VERSION ""

NS_ :

BS_:

BU_: PBWM MCPB MCPA IDCM EVCU2 ECM DMPI BPCM

BO_ 2564554485 DIAGNOSTIC_REQUEST_FUNC_FOTA: 64 EVCU2
 SG_ N_PDU : 7|64@0+ (1,0) [0|0] "" MCPB,MCPA

BO_ 292 BATTERY_HV_STATUS1: 64 BPCM
 SG_ MessageCounter_BATT_HV_STATUS1 : 435|4@0+ (1,0) [0|15] "-"  DMPI,EVCU2,MCPB,MCPA,IDCM
 SG_ CRC_BATT_HV_STATUS1 : 447|8@0+ (1,0) [0|255] "-"  DMPI,EVCU2,MCPB,MCPA,IDCM
 SG_ HVBatContactorWeldCheck : 302|1@0+ (1,0) [0|1] "" EVCU2
 SG_ HVBatReady : 268|1@0+ (1,0) [0|1] "" EVCU2
 SG_ BPCM_DC_CntctrsMidTrmOpeningWarn : 267|1@0+ (1,0) [0|1] "" EVCU2
 SG_ BPCM_DC_CntctrsShtTrmOpeningWarn : 266|1@0+ (1,0) [0|1] "" EVCU2
 SG_ BPCM_ImpactHardwireV : 188|1@0+ (1,0) [0|1] "" EVCU2
 SG_ BPCM_ImpactHardwire : 187|1@0+ (1,0) [0|1] "" EVCU2
 SG_ BPCM_HV_Char_Main_Contac_Sts : 178|3@0+ (1,0) [0|7] "" EVCU2
 SG_ BPCM_HV_Trac_Main_Contac_Sts : 181|3@0+ (1,0) [0|7] "" DMPI,EVCU2,MCPB,MCPA,IDCM
 SG_ BPCM_HV_BalancingMode : 164|2@0+ (1,0) [0|3] "" EVCU2
 SG_ BPCM_HV_ChargingBusVoltage : 162|11@0+ (1,0) [0|2047] "V"  EVCU2
 SG_ BPCM_HV_TractionBusVoltage : 146|11@0+ (1,0) [0|2047] "V"  DMPI,EVCU2,MCPB,MCPA,IDCM
 SG_ BPCM_Pwr_Limp_Home_On : 55|1@0+ (1,0) [0|1] "" EVCU2
 SG_ BPCM_HV_Trac_Bus_Sts : 36|3@0+ (1,0) [0|7] "" EVCU2,MCPB,MCPA,IDCM
 SG_ BPCM_HV_Char_Bus_Sts : 39|3@0+ (1,0) [0|7] "" EVCU2
 SG_ BPCM_HV_SOH_Low : 30|7@0+ (1,0) [0|127] "" EVCU2
 SG_ BPCM_HV_SOH : 22|7@0+ (1,0) [0|127] "" EVCU2
 SG_ HVBatContactorOpenTime : 15|8@0+ (0.2,0) [0|51] "Hours"  EVCU2
 SG_ HVBatLastSlept : 7|8@0+ (0.2,0) [0|51] "Days"  EVCU2
 SG_ BPCMInterlockSts : 54|3@0+ (1,0) [0|4] "" EVCU2
 SG_ BPCM_HV_BatIntrlk_InternalStat : 271|3@0+ (1,0) [0|3] "" EVCU2
 SG_ BPCM_HV_Temperature_Min : 218|11@0+ (0.1,-40) [-40|164.7] "°C"  EVCU2
 SG_ BPCM_HV_Temperature_Max : 202|11@0+ (0.1,-40) [-40|164.7] "°C"  EVCU2
 SG_ BPCM_HV_Temperature_Avg : 186|11@0+ (0.1,-40) [-40|164.7] "°C"  EVCU2
 SG_ BPCM_HV_SOC : 33|10@0+ (0.1,0) [0|102.3] "%"  DMPI,EVCU2
 SG_ BPCM_HV_Outlet_Temp : 250|11@0+ (0.1,-40) [-40|164.7] "°C"  EVCU2
 SG_ BPCM_HV_InternalVoltage : 133|14@0+ (0.1,90.9) [90.9|1729.2] "V"  DMPI,EVCU2
 SG_ BPCM_HV_Inlet_Temp : 234|11@0+ (0.1,-40) [-40|164.7] "°C"  EVCU2
 SG_ BPCM_HV_Current : 71|16@0+ (0.1,-3276.7) [-3276.7|3276.8] "A"  DMPI,EVCU2
 SG_ BPCM_HV_Capacity : 51|12@0+ (0.15,0) [0|614.25] "Ah"  EVCU2
 SG_ BPCM_HV_Battery_GFD_Sts : 149|3@0+ (1,0) [0|4] "" EVCU2
 SG_ BPCM_Wakeup_Request : 23|1@0+ (1,0) [0|1] "" EVCU2
 SG_ BPCM_HV_ThermalRunaway : 135|2@0+ (1,0) [0|3] "" EVCU2
 SG_ BPCM_MILRequest : 31|1@0+ (1,0) [0|1] "" EVCU2
 SG_ HVBP_Busbar_Temp : 423|8@0+ (1,-40) [-40|215] "°C"  EVCU2
 SG_ HVBP_BDU_Busbar_Temp : 415|8@0+ (1,-40) [-40|215] "°C"  EVCU2
 SG_ BPCM_HV_DCFC_Isolation_Sts : 167|3@0+ (1,0) [0|7] "" EVCU2
 SG_ BPCM_HV_Trac_PreCha_Contac_Sts : 354|3@0+ (1,0) [0|7] "" EVCU2

BO_ 485 BATTERY_HV_VLIMITS: 64 BPCM
 SG_ MessageCounter_BATT_HV_VLIMITS : 435|4@0+ (1,0) [0|15] "-"  EVCU2
 SG_ CRC_BATT_HV_VLIMITS : 447|8@0+ (1,0) [0|255] "-"  EVCU2
 SG_ BPCM_HV_NumCellMinTemp : 224|9@0+ (1,0) [0|511] "" EVCU2
 SG_ BPCM_HV_NumCellMaxTemp : 192|9@0+ (1,0) [0|511] "" EVCU2
 SG_ BPCM_HV_NumCellMinVolt : 80|9@0+ (1,0) [0|511] "" EVCU2
 SG_ BPCM_HV_NumCellMaxVolt : 64|9@0+ (1,0) [0|511] "" EVCU2
 SG_ BPCM_Min_Pk_Volt_Allowed : 50|11@0+ (1,0) [0|2047] "V"  EVCU2
 SG_ BPCM_Max_Pk_Volt_Allowed : 18|11@0+ (1,0) [0|2047] "V"  EVCU2
 SG_ BPCM_OCV_Min_Cell_Volt : 180|13@0+ (0.001,0) [0|8.191] "V"  EVCU2
 SG_ BPCM_OCV_Max_Cell_Volt : 164|13@0+ (0.001,0) [0|8.191] "V"  EVCU2
 SG_ BPCM_OCV_Avg_Cell_Volt : 148|13@0+ (0.001,0) [0|8.191] "V"  EVCU2
 SG_ BPCM_Min_Cell_Volt_Allowed : 36|13@0+ (0.001,0) [0|8.191] "V"  EVCU2
 SG_ BPCM_Max_Cell_Volt_Allowed : 132|13@0+ (0.001,0) [0|8.191] "V"  EVCU2
 SG_ BPCM_HV_Insulation_Resistance : 215|16@0+ (1,0) [0|65535] "kOhm"  EVCU2
 SG_ BPCM_Cell_Volt_Min : 116|13@0+ (0.001,0) [0|8.191] "V"  EVCU2
 SG_ BPCM_Cell_Volt_Max : 100|13@0+ (0.001,0) [0|8.191] "V"  EVCU2
 SG_ BPCM_Cell_Volt_Avg : 4|13@0+ (0.001,0) [0|8.191] "V"  EVCU2

BO_ 288 BATTERY_HV_POWERLIMITS: 64 BPCM
 SG_ BPCM_HV_HVBatChargeStat : 215|3@0+ (1,0) [0|7] "" EVCU2
 SG_ BPCM_HV_PwrLmtInstDschg : 245|14@0+ (0.1,0) [0|1638.3] "" EVCU2
 SG_ BPCM_HV_PwrLmtInstChrg : 309|14@0+ (0.1,0) [0|1638.3] "" EVCU2
 SG_ BPCM_HV_Pwr_MaxDischrg_ShrTrm : 69|14@0+ (0.1,0) [0|1638.3] "kW"  DMPI,EVCU2
 SG_ BPCM_HV_Power_MaxDischarge_MdTrm : 133|14@0+ (0.1,0) [0|1638.3] "kW"  EVCU2
 SG_ BPCM_HV_Power_MaxDischarge_LgTrm : 197|14@0+ (0.1,0) [0|1638.3] "kW"  EVCU2
 SG_ BPCM_HV_Power_MaxCharge_ShrTrm : 53|14@0+ (0.1,0) [0|1638.3] "kW"  EVCU2
 SG_ BPCM_HV_Power_MaxCharge_MdTrm : 117|14@0+ (0.1,0) [0|1638.3] "kW"  EVCU2
 SG_ BPCM_HV_Power_MaxCharge_LgTrm : 181|14@0+ (0.1,0) [0|1638.3] "kW"  EVCU2
 SG_ BPCM_HV_CrntLmtInstDschg : 374|15@0+ (0.1,0) [0|3276.7] "A"  EVCU2
 SG_ BPCM_HV_CrntLmtInstChrg : 390|15@0+ (0.1,0) [0|3276.7] "A"  EVCU2
 SG_ BPCM_HV_ChargingCurrentProfile : 6|15@0+ (0.1,0) [0|3276.7] "A"  EVCU2
 SG_ BPCM_HV_Cell_MinDischrg_Imped : 228|13@0+ (0.01,0) [0|81.91] "Ohm"  EVCU2
 SG_ BPCM_HV_Cell_MaxDischrg_Imped : 212|13@0+ (0.01,0) [0|81.91] "Ohm"  EVCU2
 SG_ BPCM_CntctrsShtTrmOpeningWarn : 417|1@0+ (1,0) [0|1] "" DMPI,EVCU2,IDCM
 SG_ BPCM_CntctrsMidTrmOpeningWarn : 416|1@0+ (1,0) [0|1] "" EVCU2
 SG_ MessageCounter_BATT_HV_POWERLIMS : 435|4@0+ (1,0) [0|15] "-"  EVCU2
 SG_ CRC_BATT_HV_POWERLIMS : 447|8@0+ (1,0) [0|255] "-"  EVCU2

BO_ 2654339161 PDC_INFO_FD_MCPB: 32 MCPB
 SG_ WakeupSource_FD16_MCPB : 95|8@0+ (1,0) [0|255] "" EVCU2
 SG_ WakeupSource_FD05_MCPB : 23|8@0+ (1,0) [0|255] "" EVCU2
 SG_ StayActiveSource_FD16_MCPB : 111|64@0+ (1,0) [0|0] "" EVCU2
 SG_ StayActiveSource_FD05_MCPB : 31|64@0+ (1,0) [0|0] "" EVCU2
 SG_ PreviousCanNMState_FD16_MCPB : 103|4@0+ (1,0) [0|15] "" EVCU2
 SG_ PreviousCanNMState_FD05_MCPB : 11|4@0+ (1,0) [0|15] "" EVCU2
 SG_ GenericFailSts_FD05_MCPB : 5|1@0+ (1,0) [0|1] "" EVCU2
 SG_ EOL_FD16_MCPB : 2|1@0+ (1,0) [0|1] "-"  EVCU2
 SG_ EOL_FD05_MCPB : 7|1@0+ (1,0) [0|1] "-"  EVCU2
 SG_ DES_FD05_MCPB : 4|2@0+ (1,0) [0|3] "" EVCU2
 SG_ CurrentFailSts_FD05_MCPB : 6|1@0+ (1,0) [0|1] "" EVCU2
 SG_ CurrentCanNMState_FD16_MCPB : 99|4@0+ (1,0) [0|15] "" EVCU2
 SG_ CurrentCanNMState_FD05_MCPB : 15|4@0+ (1,0) [0|15] "" EVCU2
 SG_ GenericFailSts_FD16_MCPB : 172|1@0+ (1,0) [0|1] "" EVCU2
 SG_ DES_FD16_MCPB : 175|2@0+ (1,0) [0|3] "" EVCU2
 SG_ CurrentFailSts_FD16_MCPB : 173|1@0+ (1,0) [0|1] "" EVCU2

BO_ 2654339160 PDC_INFO_FD_MCPA: 32 MCPA
 SG_ WakeupSource_FD16_MCPA : 95|8@0+ (1,0) [0|255] "" EVCU2
 SG_ WakeupSource_FD05_MCPA : 23|8@0+ (1,0) [0|255] "" EVCU2
 SG_ StayActiveSource_FD16_MCPA : 111|64@0+ (1,0) [0|0] "" EVCU2
 SG_ StayActiveSource_FD05_MCPA : 31|64@0+ (1,0) [0|0] "" EVCU2
 SG_ PreviousCanNMState_FD16_MCPA : 103|4@0+ (1,0) [0|15] "" EVCU2
 SG_ PreviousCanNMState_FD05_MCPA : 11|4@0+ (1,0) [0|15] "" EVCU2
 SG_ GenericFailSts_FD05_MCPA : 5|1@0+ (1,0) [0|1] "" EVCU2
 SG_ EOL_FD16_MCPA : 2|1@0+ (1,0) [0|1] "-"  EVCU2
 SG_ EOL_FD05_MCPA : 7|1@0+ (1,0) [0|1] "-"  EVCU2
 SG_ DES_FD05_MCPA : 4|2@0+ (1,0) [0|3] "" EVCU2
 SG_ CurrentFailSts_FD05_MCPA : 6|1@0+ (1,0) [0|1] "" EVCU2
 SG_ CurrentCanNMState_FD16_MCPA : 99|4@0+ (1,0) [0|15] "" EVCU2
 SG_ CurrentCanNMState_FD05_MCPA : 15|4@0+ (1,0) [0|15] "" EVCU2
 SG_ GenericFailSts_FD16_MCPA : 172|1@0+ (1,0) [0|1] "" EVCU2
 SG_ DES_FD16_MCPA : 175|2@0+ (1,0) [0|3] "" EVCU2
 SG_ CurrentFailSts_FD16_MCPA : 173|1@0+ (1,0) [0|1] "" EVCU2

BO_ 263 PT_SYSTEM_FD_1: 64 EVCU2
 SG_ OptimdStrtReqdActr : 2|3@0+ (1,0) [0|7] "" ECM
 SG_ OptimdEngStrtStpType : 7|5@0+ (1,0) [0|31] "" ECM
 SG_ OptimdEngOnOffCmd : 15|1@0+ (1,0) [0|1] "" ECM
 SG_ Hyb_ProducingTorque : 13|1@0+ (1,0) [0|1] "" ECM
 SG_ HCPFuelDisable : 14|1@0+ (1,0) [0|1] "" ECM
 SG_ PowertrainPrplsnActv_PT : 146|1@0+ (1,0) [0|1] "" MCPB,MCPA,BPCM
 SG_ GearEngagedForDisplay_PT : 12|5@0+ (1,0) [0|31] "" PBWM,MCPB,MCPA,BPCM
 SG_ GearEngaged_PT : 132|4@0+ (1,0) [0|15] "" MCPB
 SG_ DriveReady_PT : 166|1@0+ (1,0) [0|1] "" BPCM
 SG_ ParkCmd_PT : 151|2@0+ (1,0) [0|3] "" PBWM
 SG_ ShiftLeverPosition_PT : 51|4@0+ (1,0) [0|15] "" DMPI
 SG_ MessageCounter_PT_SYSTEM_FD_1 : 435|4@0+ (1,0) [0|15] "-"  PBWM,MCPB
 SG_ CRC_PT_SYSTEM_FD_1 : 447|8@0+ (1,0) [0|255] "-"  PBWM,MCPB
 SG_ EVCU_END_Request_Flag_PT : 320|1@0+ (1,0) [0|1] "" PBWM

BO_ 216 PT_ENERGY_FD_1: 64 EVCU2
 SG_ MC_PT_ENERGY_FD_1 : 435|4@0+ (1,0) [0|15] "-"  DMPI,IDCM,BPCM
 SG_ DCChrgVoltMin_PT : 55|14@0+ (0.1,0) [0|1638.30] "" Vector__XXX
 SG_ DCChrgVoltMax_PT : 151|14@0+ (0.1,0) [0|1638.30] "V"  Vector__XXX
 SG_ DCChrgPwrLim_PT : 119|14@0+ (0.1,-815) [-815|823.30] "kW"  Vector__XXX
 SG_ DCChrgCurrentRq_PT : 95|14@0+ (0.1,-815) [-815|823.30] "A"  Vector__XXX
 SG_ DCChrgCurrentLimit_PT : 21|14@0+ (0.1,-815) [-815|823.30] "A"  Vector__XXX
 SG_ DCChargeInitialized_PT : 56|1@0+ (1,0) [0|1] "" BPCM
 SG_ DCChargeEnRq_PT : 38|1@0+ (1,0) [0|1] "" Vector__XXX
 SG_ CRC_PT_ENERGY_FD_1 : 447|8@0+ (1,0) [0|255] "-"  DMPI,IDCM,BPCM
 SG_ BPCM_OBCM_AC_ContactorCmd_PT : 140|3@0+ (1,0) [0|7] "" IDCM,BPCM
 SG_ BMS_HV_TracCntctr_Cmd_PT : 4|3@0+ (1,0) [0|7] "" MCPB,MCPA,IDCM,BPCM
 SG_ BMS_HV_RefTracHVBus_V_Vldty_PT : 23|1@0+ (1,0) [0|1] "" BPCM
 SG_ BMS_HV_RefTracHVBus_V_PT : 1|10@0+ (1,0) [0|1023] "" BPCM
 SG_ BMS_HV_GFD_Inhibition_PT : 39|1@0+ (1,0) [0|1] "" BPCM
 SG_ BMS_HV_DC_Chrgng_Cntct_K_Cmd_PT : 82|3@0+ (1,0) [0|7] "" MCPB,MCPA,IDCM,BPCM
 SG_ BatteryVoltage_Raw_PT : 97|10@0+ (0.2,0) [0|204.60] "V"  MCPB,MCPA,IDCM,BPCM
 SG_ APM_LV_VsetPoint_PT : 135|11@0+ (0.01,0) [0|20.47] "V"  DMPI,IDCM
 SG_ APM_LV_VActual_PT : 71|9@0+ (0.04,0) [0|20.44] "V"  IDCM
 SG_ APM_LV_IMax_PT : 167|9@0+ (1,0) [0|511] "A"  IDCM
 SG_ APM_HV_IMax_PT : 87|5@0+ (0.8,0) [0|24.8] "A"  IDCM
 SG_ APM_TypeCtrl_PT : 78|4@0+ (1,0) [0|15] "" DMPI,IDCM,BPCM
 SG_ BMS_HV_Char_Main_Contac_Cmd_PT : 173|3@0+ (1,0) [0|7] "" BPCM

BO_ 1041 EVCU_ISO15118_STATUS1: 64 EVCU2
 SG_ EVMinCurrent : 264|9@0+ (1,0) [0|511] "A"  IDCM
 SG_ EVMaxVoltage : 233|10@0+ (1,0) [0|1023] "V"  IDCM
 SG_ EVMaxCurrent : 248|9@0+ (1,0) [0|511] "A"  IDCM
 SG_ Eamount : 281|18@0+ (1,0) [0|262143] "Wh"  IDCM

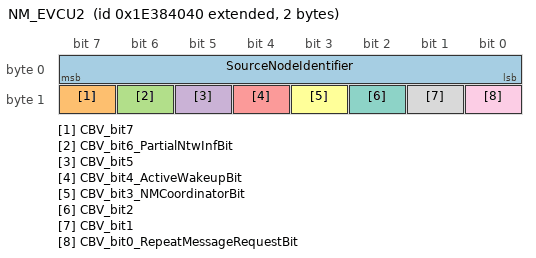
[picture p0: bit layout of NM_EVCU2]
BO_ 2654486592 NM_EVCU2: 2 EVCU2
 SG_ SourceNodeIdentifier : 7|8@0+ (1,0) [0|255] "-"  DMPI,PBWM,MCPB,MCPA,IDCM,BPCM,ECM
 SG_ CBV_bit7 : 15|1@0+ (1,0) [0|1] "" DMPI,PBWM,MCPB,MCPA,IDCM,BPCM,ECM
 SG_ CBV_bit6_PartialNtwInfBit : 14|1@0+ (1,0) [0|1] "" DMPI,PBWM,MCPB,MCPA,IDCM,BPCM,ECM
 SG_ CBV_bit5 : 13|1@0+ (1,0) [0|1] "" DMPI,PBWM,MCPB,MCPA,IDCM,BPCM,ECM
 SG_ CBV_bit4_ActiveWakeupBit : 12|1@0+ (1,0) [0|1] "" DMPI,PBWM,MCPB,MCPA,IDCM,BPCM,ECM
 SG_ CBV_bit3_NMCoordinatorBit : 11|1@0+ (1,0) [0|1] "" DMPI,PBWM,MCPB,MCPA,IDCM,BPCM,ECM
 SG_ CBV_bit2 : 10|1@0+ (1,0) [0|1] "" DMPI,PBWM,MCPB,MCPA,IDCM,BPCM,ECM
 SG_ CBV_bit1 : 9|1@0+ (1,0) [0|1] "" DMPI,PBWM,MCPB,MCPA,IDCM,BPCM,ECM
 SG_ CBV_bit0_RepeatMessageRequestBit : 8|1@0+ (1,0) [0|1] "" DMPI,PBWM,MCPB,MCPA,IDCM,BPCM,ECM

BO_ 212 PIM_B: 64 DMPI
 SG_ PIM_B_Torque_Achieved : 44|13@0+ (0.125,-512) [-512|511.875] "Nm"  EVCU2
 SG_ PIM_B_Torque_Achieved_V : 129|1@0+ (1,0) [0|1] "" EVCU2
 SG_ PIM_B_TorqAchieved_AEMD_V : 196|1@0+ (1,0) [0|1] "" EVCU2
 SG_ PIM_B_TorqAchieved_AEMD : 299|13@0+ (0.125,-512) [-512|511.875] "Nm"  EVCU2
 SG_ PIM_B_SPT_Stat : 78|2@0+ (1,0) [0|3] "" EVCU2
 SG_ PIM_B_Spd_Lim : 356|16@0+ (1,-32767) [-32767|32678] "rpm"  EVCU2
 SG_ PIM_B_RPM_V : 234|1@0+ (1,0) [0|1] "" EVCU2
 SG_ PIM_B_RPM : 28|16@0+ (1,-32768) [-32768|32767] "rpm"  EVCU2
 SG_ PIM_B_MtrMinCpbltyTrq : 321|13@0+ (0.125,-512) [-512|511.875] "Nm"  EVCU2
 SG_ PIM_B_MtrMaxCpbltyTrq : 318|13@0+ (0.125,-512) [-512|511.875] "Nm"  EVCU2
 SG_ PIM_B_MtrIndex : 398|5@0+ (1,0) [0|31] "" EVCU2
 SG_ PIM_B_MinTorq : 280|13@0+ (0.125,-512) [-512|511.875] "Nm"  EVCU2
 SG_ PIM_B_MaxTorq : 277|13@0+ (0.125,-512) [-512|511.875] "Nm"  EVCU2
 SG_ PIM_B_Invrtr_State : 186|4@0+ (1,0) [0|15] "" EVCU2
 SG_ PIM_B_InterlockSts : 229|2@0+ (1,0) [0|3] "-"  EVCU2
 SG_ PIM_B_HV_CnctrOpn_Req : 195|1@0+ (1,0) [0|1] "" EVCU2
 SG_ PIM_B_Dschrge_Status : 393|2@0+ (1,0) [0|3] "" EVCU2
 SG_ PIM_B_DeratingFactor : 388|6@0+ (0.02,0) [0|1.26] "" EVCU2
 SG_ PIM_B_DerateReason : 170|4@0+ (1,0) [0|15] "-"  EVCU2
 SG_ PIM_B_DC_Voltage : 271|10@0+ (1,0) [0|1022] "V"  EVCU2
 SG_ PIM_B_DC_Volt_V : 197|1@0+ (1,0) [0|1] "" EVCU2
 SG_ PIM_B_DC_Current_V : 198|1@0+ (1,0) [0|1] "" EVCU2
 SG_ PIM_B_DC_Current : 63|15@0+ (0.1,-1638.4) [-1638.4|1638.3] "A"  EVCU2,BPCM
 SG_ PIM_B_CpbltySpdDivVolt : 340|16@0+ (1,0) [0|65535] "rpm"  EVCU2
 SG_ PIM_B_CoolantTemp : 407|11@0+ (0.1,-40) [-40|164.7] "°C"  EVCU2
 SG_ PIM_B_AccelRawV : 193|1@0+ (1,0) [0|1] "" EVCU2
 SG_ PIM_B_6SO_Status : 64|2@0+ (1,0) [0|3] "" EVCU2
 SG_ PIM_B_3PS_Pos : 194|1@0+ (1,0) [0|1] "" EVCU2
 SG_ MC_PIM_B : 435|4@0+ (1,0) [0|15] "-"  EVCU2
 SG_ MAC_PIM_B : 471|48@0+ (1,0) [0|0] "" EVCU2
 SG_ CRC_PIM_B : 447|8@0+ (1,0) [0|255] "-"  EVCU2
 SG_ Cntr_PIM_B : 455|16@0+ (1,0) [0|65535] "" EVCU2
 SG_ PIM_B_AccelRaw : 372|16@0+ (1,-32768) [-32768|32767] "rpm/sec"  EVCU2

BO_ 211 PIM_A: 64 DMPI
 SG_ PIM_A_Torque_Achieved : 44|13@0+ (0.125,-512) [-512|511.875] "Nm"  EVCU2,ECM
 SG_ PIM_A_Torque_Achieved_V : 129|1@0+ (1,0) [0|1] "" EVCU2,ECM
 SG_ PIM_A_TorqAchieved_AEMD_V : 196|1@0+ (1,0) [0|1] "" EVCU2
 SG_ PIM_A_TorqAchieved_AEMD : 299|13@0+ (0.125,-512) [-512|511.875] "Nm"  EVCU2
 SG_ PIM_A_SPT_Stat : 78|2@0+ (1,0) [0|3] "" EVCU2
 SG_ PIM_A_Spd_Lim : 356|16@0+ (1,-32767) [-32767|32678] "rpm"  EVCU2
 SG_ PIM_A_RPM_V : 234|1@0+ (1,0) [0|1] "" EVCU2
 SG_ PIM_A_RPM : 28|16@0+ (1,-32768) [-32768|32767] "rpm"  EVCU2
 SG_ PIM_A_MtrMinCpbltyTrq : 321|13@0+ (0.125,-512) [-512|511.875] "Nm"  EVCU2
 SG_ PIM_A_MtrMaxCpbltyTrq : 318|13@0+ (0.125,-512) [-512|511.875] "Nm"  EVCU2
 SG_ PIM_A_MtrIndex : 398|5@0+ (1,0) [0|31] "" EVCU2
 SG_ PIM_A_MinTorq : 280|13@0+ (0.125,-512) [-512|511.875] "Nm"  EVCU2
 SG_ PIM_A_MaxTorq : 277|13@0+ (0.125,-512) [-512|511.875] "Nm"  EVCU2
 SG_ PIM_A_Invrtr_State : 186|4@0+ (1,0) [0|15] "" EVCU2
 SG_ PIM_A_InterlockSts : 229|2@0+ (1,0) [0|3] "-"  EVCU2
 SG_ PIM_A_HV_CnctrOpn_Req : 195|1@0+ (1,0) [0|1] "" EVCU2
 SG_ PIM_A_Dschrge_Status : 393|2@0+ (1,0) [0|3] "" EVCU2
 SG_ PIM_A_DeratingFactor : 388|6@0+ (0.02,0) [0|1.26] "" EVCU2
 SG_ PIM_A_DerateReason : 170|4@0+ (1,0) [0|15] "-"  EVCU2
 SG_ PIM_A_DC_Voltage : 271|10@0+ (1,0) [0|1022] "V"  EVCU2
 SG_ PIM_A_DC_Volt_V : 197|1@0+ (1,0) [0|1] "" EVCU2
 SG_ PIM_A_DC_Current_V : 198|1@0+ (1,0) [0|1] "" EVCU2
 SG_ PIM_A_DC_Current : 63|15@0+ (0.1,-1638.4) [-1638.4|1638.3] "A"  EVCU2,BPCM
 SG_ PIM_A_CpbltySpdDivVolt : 340|16@0+ (1,0) [0|65535] "rpm"  EVCU2
 SG_ PIM_A_CoolantTemp : 407|11@0+ (0.1,-40) [-40|164.7] "°C"  EVCU2
 SG_ PIM_A_AccelRawV : 193|1@0+ (1,0) [0|1] "" EVCU2
 SG_ PIM_A_6SO_Status : 64|2@0+ (1,0) [0|3] "" EVCU2
 SG_ PIM_A_3PS_Pos : 194|1@0+ (1,0) [0|1] "" EVCU2
 SG_ MC_PIM_A : 435|4@0+ (1,0) [0|15] "-"  EVCU2
 SG_ MAC_PIM_A : 471|48@0+ (1,0) [0|0] "" EVCU2
 SG_ CRC_PIM_A : 447|8@0+ (1,0) [0|255] "-"  EVCU2
 SG_ Cntr_PIM_A : 455|16@0+ (1,0) [0|65535] "" EVCU2
 SG_ PIM_A_AccelRaw : 372|16@0+ (1,-32768) [-32768|32767] "rpm/sec"  EVCU2

BO_ 1811 REAL_TIME_CLOCK: 64 EVCU2
 SG_ Real_Time_Validity : 39|1@0+ (1,0) [0|1] "" DMPI,MCPB,MCPA
 SG_ Real_Time_Clock : 7|32@0+ (1,0) [0|4294967295] "" DMPI,MCPB,MCPA
 SG_ MessageCounter_REAL_TIME_CLOCK : 435|4@0+ (1,0) [0|15] "-"  DMPI
 SG_ CRC_ANCHOR3_REAL_TIME_CLOCK : 447|8@0+ (1,0) [0|255] "-"  DMPI

BO_ 215 PCU_FD_1: 64 DMPI
 SG_ Pinion_OverspeedWarning : 33|1@0+ (1,0) [0|1] "" EVCU2
 SG_ PCU_Temporary_Stop_Flag : 75|1@0+ (1,0) [0|1] "" EVCU2
 SG_ PCU_MIL_Request : 103|1@0+ (1,0) [0|1] "" EVCU2
 SG_ PCU_MaxBoostedVoltage : 7|10@0+ (1,0) [0|1023] "V"  EVCU2
 SG_ PCU_Max_DischargePowerLmt : 31|14@0+ (0.01,0) [0|163.83] "kW"  EVCU2
 SG_ PCU_Max_ChargePowerLmt : 13|14@0+ (0.01,0) [0|163.83] "kW"  EVCU2
 SG_ PCU_DriveReadyCompletion_Status : 32|1@0+ (1,0) [0|1] "" EVCU2
 SG_ PCU_Diagnostic_Code : 87|16@0+ (1,0) [0|65535] "" EVCU2
 SG_ MessageCounter_PCU_FD_1 : 435|4@0+ (1,0) [0|15] "" EVCU2
 SG_ MAC_PCU_FD_1 : 471|48@0+ (1,0) [0|0] "" EVCU2
 SG_ CRC_PCU_FD_1 : 447|8@0+ (1,0) [0|255] "" EVCU2
 SG_ Cntr_PCU_FD_1 : 455|16@0+ (1,0) [0|65535] "" EVCU2
 SG_ BoostConverterFailureSts : 74|3@0+ (1,0) [0|7] "" EVCU2
 SG_ BoostConverter_Current : 102|15@0+ (0.1,-1638.3) [-1638.3|1638.40] "A"  EVCU2
 SG_ BoostConv_UpperIGBT_TempFltd : 47|12@0+ (0.1,-40) [-40|369.5] "°C"  EVCU2
 SG_ BoostConv_ReactorTemp : 71|12@0+ (0.1,-40) [-40|369.5] "ºC"  EVCU2
 SG_ BoostConv_LowerIGBT_TempFltd : 51|12@0+ (0.1,-40) [-40|369.5] "ºC"  EVCU2
 SG_ Output_Torque_Limit : 127|15@0+ (2,0) [0|65534] "Nm"  EVCU2
 SG_ BoostConverterDerateReason : 136|9@0+ (1,0) [0|511] "" EVCU2
 SG_ PCU_Max_DischargePowerLmt_ShrTrm : 159|14@0+ (0.01,0) [0|163.83] "kW"  EVCU2
 SG_ DMPI_OilTemperatureSts : 128|1@0+ (1,0) [0|1] "" EVCU2
 SG_ DMPI_TransmissionTemperature : 143|6@0+ (3,-40) [-40|149] "ºC"  EVCU2

CM_ SG_ 2564554485 N_PDU "This signal is used for diagnostic purposes";
CM_ SG_ 292 HVBP_Busbar_Temp "HVBP Busbar temp";
CM_ SG_ 292 HVBP_BDU_Busbar_Temp "HVBP BDU Busbar temp";
CM_ SG_ 292 HVBatReady "High Voltage Battery Ready";
CM_ SG_ 292 HVBatLastSlept "Time since BPCM last went to sleep.";
CM_ SG_ 292 HVBatContactorWeldCheck "Contactor weld check report from BPCM for DC charging.";
CM_ SG_ 292 HVBatContactorOpenTime "Time Since Bat contactors last transitioned to Open.";
CM_ SG_ 292 MessageCounter_BATT_HV_STATUS1 "This signal is a counter used for safety checks strategies. This counter is incremented of 1 (one) unit at each frame transmission.";
CM_ SG_ 292 CRC_BATT_HV_STATUS1 "CRC according to SAE J1850 standard at each frame transmission.";
CM_ SG_ 292 BPCMInterlockSts "BPCM interlock state";
CM_ SG_ 292 BPCM_Wakeup_Request "BPCM Wakeup event";
CM_ SG_ 292 BPCM_Pwr_Limp_Home_On "Traction Battery Limp Home mode flag.";
CM_ SG_ 292 BPCM_MILRequest "BPCM MIL Request 0 = False 1 = True";
CM_ SG_ 292 BPCM_ImpactHardwireV "This signal is used to indicate a Valid serial line comunication";
CM_ SG_ 292 BPCM_ImpactHardwire "This signal is used to indicate that a crash happened";
CM_ SG_ 292 BPCM_HV_Trac_PreCha_Contac_Sts "Status of DC Circuit isolation failure";
CM_ SG_ 292 BPCM_HV_TractionBusVoltage "Battery link traction bus voltage.";
CM_ SG_ 292 BPCM_HV_Trac_Main_Contac_Sts "Traction main contactor physical relay status";
CM_ SG_ 292 BPCM_HV_ThermalRunaway "Thermal runaway status";
CM_ SG_ 292 BPCM_HV_Temperature_Min "Battery Minimum Temperature22/06/2020 Allegra Giordano - changes: Value, Max (previous values: 164,7 - 164,6) (Daniele Zaharia's request)";
CM_ SG_ 292 BPCM_HV_Temperature_Max "Battery Max Temperature22/06/2020 Allegra Giordano - changes: Value, Max (previous values: 164,7 - 164,6) (Daniele Zaharia's request)";
CM_ SG_ 292 BPCM_HV_Temperature_Avg "Battery Average Temperature22/06/2020 Allegra Giordano - changes: Value, Max (previous values: 164,7 - 164,6) (Daniele Zaharia' request)";
CM_ SG_ 292 BPCM_HV_SOH_Low "State of Health calculated at low SOC.";
CM_ SG_ 292 BPCM_HV_SOH "Status of Healt";
CM_ SG_ 292 BPCM_HV_SOC "State of Charge";
CM_ SG_ 292 BPCM_HV_Outlet_Temp "Outlet Temperature";
CM_ SG_ 292 BPCM_HV_InternalVoltage "Battery internal voltage.";
CM_ SG_ 292 BPCM_HV_Inlet_Temp "Inlet temperature";
CM_ SG_ 292 BPCM_HV_DCFC_Isolation_Sts "Status of DC Circuit isolation failure";
CM_ SG_ 292 BPCM_HV_Current "Battery Current";
CM_ SG_ 292 BPCM_HV_ChargingBusVoltage "Voltage measurement between positive main bus (after contactor) and negative charging branch.";
CM_ SG_ 292 BPCM_HV_Char_Main_Contac_Sts "DC Charging main contactor physical relay status.";
CM_ SG_ 292 BPCM_HV_Capacity "Battery Capacity";
CM_ SG_ 292 BPCM_HV_Battery_GFD_Sts "HV Battery ground fault detection(Isolation).";
CM_ SG_ 292 BPCM_HV_BatIntrlk_InternalStat "HVIL Status internal";
CM_ SG_ 292 BPCM_HV_BalancingMode "Balancing Mode";
CM_ SG_ 485 MessageCounter_BATT_HV_VLIMITS "This signal is a counter used for safety checks strategies. This counter is incremented of 1 (one) unit at each frame transmission.";
CM_ SG_ 485 CRC_BATT_HV_VLIMITS "CRC according to SAE J1850 standard at each frame transmission.";
CM_ SG_ 485 BPCM_OCV_Min_Cell_Volt "This signal indicates the Cell open circuit minimum voltage.";
CM_ SG_ 485 BPCM_OCV_Max_Cell_Volt "This signal indicates the Cell open circuit  maximum voltage.";
CM_ SG_ 485 BPCM_OCV_Avg_Cell_Volt "This signal indicates the Cell open circuit average voltage .";
CM_ SG_ 485 BPCM_Min_Pk_Volt_Allowed "This signal indicates the Minimum battery peak pack voltage.";
CM_ SG_ 485 BPCM_Min_Cell_Volt_Allowed "This signal indicates the Minimum battery pack voltage.";
CM_ SG_ 485 BPCM_Max_Pk_Volt_Allowed "This signal indicates the Maximum battery pack voltage allowed.";
CM_ SG_ 485 BPCM_Max_Cell_Volt_Allowed "This signal indicates the Max cell voltage allowed.";
CM_ SG_ 485 BPCM_HV_NumCellMinVolt "This signal indicates the ID No. of cell with min. voltage";
CM_ SG_ 485 BPCM_HV_NumCellMinTemp "This signal indicates the Numner of the battery cell with the lowest temperature.";
CM_ SG_ 485 BPCM_HV_NumCellMaxVolt "This signal indicates the ID No. of cell with max. voltage";
CM_ SG_ 485 BPCM_HV_NumCellMaxTemp "This signal indicates the Number of the battery cell with the highest temperature.";
CM_ SG_ 485 BPCM_HV_Insulation_Resistance "This signal indicates the Insulation resistance.";
CM_ SG_ 485 BPCM_Cell_Volt_Min "This signal indicates the Min cell voltage.";
CM_ SG_ 485 BPCM_Cell_Volt_Max "This signal indicates the Max cell voltage.";
CM_ SG_ 485 BPCM_Cell_Volt_Avg "This signal indicates the Cell average voltage.";
CM_ SG_ 288 MessageCounter_BATT_HV_POWERLIMS "This signal is a counter used for safety checks strategies. This counter is incremented of 1 (one) unit at each frame transmission.";
CM_ SG_ 288 CRC_BATT_HV_POWERLIMS "CRC according to SAE J1850 standard at each frame transmission.";
CM_ SG_ 288 BPCM_HV_PwrLmtInstDschg "Instantaneous power prediction limit in discharge";
CM_ SG_ 288 BPCM_HV_PwrLmtInstChrg "Instantaneous power prediction limit in charge";
CM_ SG_ 288 BPCM_HV_Pwr_MaxDischrg_ShrTrm "This signal indicates the Maximum discharge power available for the next short term.";
CM_ SG_ 288 BPCM_HV_Power_MaxDischarge_MdTrm "This signal indicates the Maximum discharge power available for the next mid term.";
CM_ SG_ 288 BPCM_HV_Power_MaxDischarge_LgTrm "This signal indicates the Maximum discharge power available for the next long term.";
CM_ SG_ 288 BPCM_HV_Power_MaxCharge_ShrTrm "This signal indicates the Maximum charge power available for the next short term.";
CM_ SG_ 288 BPCM_HV_Power_MaxCharge_MdTrm "This signal indicates the Maximum charge power available for the next mid term.";
CM_ SG_ 288 BPCM_HV_Power_MaxCharge_LgTrm "This signal indicates the Maximum charge power available for the next long term.";
CM_ SG_ 288 BPCM_HV_CrntLmtInstDschg "BPCM_HV_CrntLmtInstDschg";
CM_ SG_ 288 BPCM_HV_CrntLmtInstChrg "BPCM_HV_CrntLmtInstChrg";
CM_ SG_ 288 BPCM_HV_ChargingCurrentProfile "This signal indicates the Charging current profile.";
CM_ SG_ 288 BPCM_HV_Cell_MinDischrg_Imped "This signal indicates the Maximum cell discharge impedance.";
CM_ SG_ 288 BPCM_HV_Cell_MaxDischrg_Imped "This signal indicates the Maximum cell discharge impedance.";
CM_ SG_ 288 BPCM_CntctrsShtTrmOpeningWarn "This signal indicates the Battery warning imminent emergency contactors opening.";
CM_ SG_ 288 BPCM_CntctrsMidTrmOpeningWarn "This signal indicates the Battery warning mid term emergency contactors opening.";
CM_ SG_ 2654339161 WakeupSource_FD16_MCPB "Indicates the reason the ECU was most recently awakened";
CM_ SG_ 2654339161 WakeupSource_FD05_MCPB "Indicates the reason the ECU was most recently awakened";
CM_ SG_ 2654339161 StayActiveSource_FD16_MCPB "Indicates the source that requests the ECU to stay active";
CM_ SG_ 2654339161 StayActiveSource_FD05_MCPB "Indicates the source that requests the ECU to stay active";
CM_ SG_ 2654339161 PreviousCanNMState_FD16_MCPB "Indicates the last CanNM state that the ECU existed in";
CM_ SG_ 2654339161 PreviousCanNMState_FD05_MCPB "Indicates the last CanNM state that the ECU existed in";
CM_ SG_ 2654339161 GenericFailSts_FD16_MCPB "Indicates the presence/absent of at least one DTC in the System Memory";
CM_ SG_ 2654339161 GenericFailSts_FD05_MCPB "Indicates the presence/absent of at least one DTC in the System Memory";
CM_ SG_ 2654339161 EOL_FD16_MCPB "Indicates if the ECU requires configuration data at the assembly plant End Of Line";
CM_ SG_ 2654339161 EOL_FD05_MCPB "Indicates if the ECU requires configuration data at the assembly plant End Of Line";
CM_ SG_ 2654339161 DES_FD16_MCPB "Indicates whether the ECU?s CAN cell is in either ErrorActive, or ErrorPassive state OR has just now recovered from a BusOff condition";
CM_ SG_ 2654339161 DES_FD05_MCPB "Indicates whether the ECU?s CAN cell is in either ErrorActive, or ErrorPassive state OR has just now recovered from a BusOff condition";
CM_ SG_ 2654339161 CurrentFailSts_FD16_MCPB "Indicates the presence/absence of at least one DTC with DTCStatus = present in the System Memory";
CM_ SG_ 2654339161 CurrentFailSts_FD05_MCPB "Indicates the presence/absence of at least one DTC with DTCStatus = present in the System Memory";
CM_ SG_ 2654339161 CurrentCanNMState_FD16_MCPB "Indicates that CanNM state the ECU is currently executing";
CM_ SG_ 2654339161 CurrentCanNMState_FD05_MCPB "Indicates that CanNM state the ECU is currently executing";
CM_ SG_ 2654339160 WakeupSource_FD16_MCPA "Indicates the reason the ECU was most recently awakened";
CM_ SG_ 2654339160 WakeupSource_FD05_MCPA "Indicates the reason the ECU was most recently awakened";
CM_ SG_ 2654339160 StayActiveSource_FD16_MCPA "Indicates the source that requests the ECU to stay active";
CM_ SG_ 2654339160 StayActiveSource_FD05_MCPA "Indicates the source that requests the ECU to stay active";
CM_ SG_ 2654339160 PreviousCanNMState_FD16_MCPA "Indicates the last CanNM state that the ECU existed in";
CM_ SG_ 2654339160 PreviousCanNMState_FD05_MCPA "Indicates the last CanNM state that the ECU existed in";
CM_ SG_ 2654339160 GenericFailSts_FD16_MCPA "Indicates the presence/absent of at least one DTC in the System Memory";
CM_ SG_ 2654339160 GenericFailSts_FD05_MCPA "Indicates the presence/absent of at least one DTC in the System Memory";
CM_ SG_ 2654339160 EOL_FD16_MCPA "Indicates if the ECU requires configuration data at the assembly plant End Of Line";
CM_ SG_ 2654339160 EOL_FD05_MCPA "Indicates if the ECU requires configuration data at the assembly plant End Of Line";
CM_ SG_ 2654339160 DES_FD16_MCPA "Indicates whether the ECU?s CAN cell is in either ErrorActive, or ErrorPassive state OR has just now recovered from a BusOff condition";
CM_ SG_ 2654339160 DES_FD05_MCPA "Indicates whether the ECU?s CAN cell is in either ErrorActive, or ErrorPassive state OR has just now recovered from a BusOff condition";
CM_ SG_ 2654339160 CurrentFailSts_FD16_MCPA "Indicates the presence/absence of at least one DTC with DTCStatus = present in the System Memory";
CM_ SG_ 2654339160 CurrentFailSts_FD05_MCPA "Indicates the presence/absence of at least one DTC with DTCStatus = present in the System Memory";
CM_ SG_ 2654339160 CurrentCanNMState_FD16_MCPA "Indicates that CanNM state the ECU is currently executing";
CM_ SG_ 2654339160 CurrentCanNMState_FD05_MCPA "Indicates that CanNM state the ECU is currently executing";
CM_ SG_ 263 ShiftLeverPosition_PT "Shift Lever Position";
CM_ SG_ 263 PowertrainPrplsnActv_PT "Powertrain Propulsion System Status";
CM_ SG_ 263 ParkCmd_PT "Park Command for MCP.";
CM_ SG_ 263 OptimdStrtReqdActr "Signal to determine which actuator will be used to spin/crank the engine";
CM_ SG_ 263 OptimdEngStrtStpType "This signal indicates the type of engine start";
CM_ SG_ 263 OptimdEngOnOffCmd "Signal to give the final command on if the engine should be On or Off";
CM_ SG_ 263 MessageCounter_PT_SYSTEM_FD_1 "This signal is a counter used for safety checks strategies. This counter is incremented of 1 (one) unit at each frame transmission.";
CM_ SG_ 263 Hyb_ProducingTorque "This signal indicates that hybrid control unit is declaring enging producing torque";
CM_ SG_ 263 HCPFuelDisable "Signal to disable fueling for engine ramp or ramp down purposes";
CM_ SG_ 263 GearEngagedForDisplay_PT "Transmission Gear Engaged signal for the instrument cluster display";
CM_ SG_ 263 GearEngaged_PT "Current engaged gear";
CM_ SG_ 263 EVCU_END_Request_Flag_PT "PBWM END Request Flag";
CM_ SG_ 263 DriveReady_PT "Drive Ready allowed status";
CM_ SG_ 263 CRC_PT_SYSTEM_FD_1 "CRC according to SAE J1850 standard at each frame transmission.";
CM_ SG_ 216 MC_PT_ENERGY_FD_1 "Message counter according to SAE J1850 standard that has to be calculated from bit 63 to bit 8 at each frame transmission.";
CM_ SG_ 216 DCChrgVoltMin_PT "This signal indicates the DC charging voltage min for DC-DC";
CM_ SG_ 216 DCChrgVoltMax_PT "This signal indicates the DC charging voltage max for DC-DC";
CM_ SG_ 216 DCChrgPwrLim_PT "This signal indicates the DC Charging power limit for the DC-DC";
CM_ SG_ 216 DCChrgCurrentRq_PT "This signal indicates the Requested charging current to DC-DC";
CM_ SG_ 216 DCChrgCurrentLimit_PT "This signal indicates the DC charging current limit to DC-DC";
CM_ SG_ 216 DCChargeEnRq_PT "This signal indicates the DC charge enable request";
CM_ SG_ 216 CRC_PT_ENERGY_FD_1 "CRC according to SAE J1850 standard that has to be calculated from bit 63 to bit 8 at each frame transmission.";
CM_ SG_ 216 BPCM_OBCM_AC_ContactorCmd_PT "AC Charging Strategy Status";
CM_ SG_ 216 BMS_HV_TracCntctr_Cmd_PT "This signal indicates the contactor closure command";
CM_ SG_ 216 BMS_HV_RefTracHVBus_V_Vldty_PT "This signal indicates the HV bus voltage reference for HV Precharge validity";
CM_ SG_ 216 BMS_HV_RefTracHVBus_V_PT "This signal indicates the HV bus volatage reference for HV Precharge";
CM_ SG_ 216 BMS_HV_GFD_Inhibition_PT "This signal indicates the Battery GFD Inhibition, used when an external GFD detection is performed";
CM_ SG_ 216 BMS_HV_DC_Chrgng_Cntct_K_Cmd_PT "DC Charging K7 contactor command signal";
CM_ SG_ 216 BMS_HV_Char_Main_Contac_Cmd_PT "DC charging main contactor command";
CM_ SG_ 216 BatteryVoltage_Raw_PT "Battery Voltage value measured from the electrified powertrain control module pin";
CM_ SG_ 216 APM_TypeCtrl_PT "This signal indicates the DC-DC request mode";
CM_ SG_ 216 APM_LV_VsetPoint_PT "The signal indicates the desired Low Voltage Set Point of Electronic Voltage Regulator";
CM_ SG_ 216 APM_LV_VActual_PT "This signal indicates the Low Voltage bus actual voltage";
CM_ SG_ 216 APM_LV_IMax_PT "This signal indicates the DC-DC maximun current limitations from the LV";
CM_ SG_ 216 APM_HV_IMax_PT "This signal indicates the DC-DC maximum current limitation from HV";
CM_ SG_ 1041 EVMinCurrent "EV Minumum current below which it is not energy or cost efficient";
CM_ SG_ 1041 EVMaxVoltage "RMS of the maximum voltage vehicle can accept";
CM_ SG_ 1041 EVMaxCurrent "EV Maximum current supported per Phase";
CM_ SG_ 1041 Eamount "Estimated Energy to Full charge";
CM_ SG_ 212 PIM_B_Torque_Achieved_V "Achieved Torque value Validity, [1] = True";
CM_ SG_ 212 PIM_B_Torque_Achieved "Motr B Torque Achieved";
CM_ SG_ 212 PIM_B_TorqAchieved_AEMD_V "Motor Torque Achieved Validity";
CM_ SG_ 212 PIM_B_TorqAchieved_AEMD "Motor Torque Achieved";
CM_ SG_ 212 PIM_B_SPT_Stat "Inverter Isolation Status";
CM_ SG_ 212 PIM_B_Spd_Lim "Limited motor speed during reduced performance from MCP B";
CM_ SG_ 212 PIM_B_RPM_V "Motor B Speed Validity, [1] = True";
CM_ SG_ 212 PIM_B_RPM "Motor B Speed Raw";
CM_ SG_ 212 PIM_B_MtrMinCpbltyTrq "Motor B Min Capability Torque";
CM_ SG_ 212 PIM_B_MtrMaxCpbltyTrq "Motor B Max Capability Torque";
CM_ SG_ 212 PIM_B_MtrIndex "Motor B Capability Curve Array Index";
CM_ SG_ 212 PIM_B_MinTorq "Motor B Minimum Torque";
CM_ SG_ 212 PIM_B_MaxTorq "Motor B Maximum Torque";
CM_ SG_ 212 PIM_B_Invrtr_State "Inverter State of Operation of Motor B";
CM_ SG_ 212 PIM_B_InterlockSts "Front inverter interlock state";
CM_ SG_ 212 PIM_B_HV_CnctrOpn_Req "HV Battery pack contactor request";
CM_ SG_ 212 PIM_B_Dschrge_Status "The active discharge status of MCPB";
CM_ SG_ 212 PIM_B_DeratingFactor "Motor B Derating Factor";
CM_ SG_ 212 PIM_B_DerateReason "Inverter Derating Reason";
CM_ SG_ 212 PIM_B_DC_Voltage "Inverter Front DC Voltage.";
CM_ SG_ 212 PIM_B_DC_Volt_V "Motor B DC current  validity, [1] = True";
CM_ SG_ 212 PIM_B_DC_Current_V "Motor B DC current  validity, [1] = True";
CM_ SG_ 212 PIM_B_DC_Current "Motor B DC Current";
CM_ SG_ 212 PIM_B_CpbltySpdDivVolt "Motor B Speed at Capability Curve";
CM_ SG_ 212 PIM_B_CoolantTemp "PIM Coolant Temperature";
CM_ SG_ 212 PIM_B_AccelRawV "Motor B Acceleration Validity";
CM_ SG_ 212 PIM_B_AccelRaw "Motor B Acceleration";
CM_ SG_ 212 PIM_B_3PS_Pos "3 phase motor short possible from MCP B; True = [1]";
CM_ SG_ 212 MC_PIM_B "Message counter according to SAE J1850 standard that has to be calculated from bit 63 to bit 8 at each frame transmission.";
CM_ SG_ 212 CRC_PIM_B "CRC according to SAE J1850 standard that has to be calculated from bit 63 to bit 8 at each frame transmission.";
CM_ SG_ 211 PIM_A_Torque_Achieved_V "Achieved Torque value Validity, [1] = True";
CM_ SG_ 211 PIM_A_Torque_Achieved "Motr A Torque Achieved";
CM_ SG_ 211 PIM_A_TorqAchieved_AEMD_V "Motor Torque Achieved Validity";
CM_ SG_ 211 PIM_A_TorqAchieved_AEMD "Motor Torque Achieved";
CM_ SG_ 211 PIM_A_SPT_Stat "Inverter Isolation Status";
CM_ SG_ 211 PIM_A_Spd_Lim "Limited motor speed during reduced performance from MCP B";
CM_ SG_ 211 PIM_A_RPM_V "Motor A Speed Validity, [1] = True";
CM_ SG_ 211 PIM_A_RPM "Motor A Speed Raw";
CM_ SG_ 211 PIM_A_MtrMinCpbltyTrq "Motor A Min Capability Torque";
CM_ SG_ 211 PIM_A_MtrMaxCpbltyTrq "Motor A Max Capability Torque";
CM_ SG_ 211 PIM_A_MtrIndex "Motor A Capability Curve Array Index";
CM_ SG_ 211 PIM_A_MinTorq "Motor A Minimum Torque";
CM_ SG_ 211 PIM_A_MaxTorq "Motor A Maximum Torque";
CM_ SG_ 211 PIM_A_Invrtr_State "Inverter State of Operation of Motor A";
CM_ SG_ 211 PIM_A_InterlockSts "Front inverter interlock state";
CM_ SG_ 211 PIM_A_HV_CnctrOpn_Req "HV Battery pack contactor request";
CM_ SG_ 211 PIM_A_Dschrge_Status "The active discharge status of MCPA";
CM_ SG_ 211 PIM_A_DeratingFactor "Motor A Derating Factor";
CM_ SG_ 211 PIM_A_DerateReason "Inverter Derating Reason";
CM_ SG_ 211 PIM_A_DC_Voltage "Inverter Front DC Voltage.";
CM_ SG_ 211 PIM_A_DC_Volt_V "Motor A DC current  validity, [1] = True";
CM_ SG_ 211 PIM_A_DC_Current_V "Motor A DC current  validity, [1] = True";
CM_ SG_ 211 PIM_A_DC_Current "Motor A DC Current";
CM_ SG_ 211 PIM_A_CpbltySpdDivVolt "Motor A Speed at Capability Curve";
CM_ SG_ 211 PIM_A_CoolantTemp "PIM Coolant Temperature";
CM_ SG_ 211 PIM_A_AccelRawV "Motor A Acceleration Validity";
CM_ SG_ 211 PIM_A_AccelRaw "Motor A Acceleration";
CM_ SG_ 211 PIM_A_3PS_Pos "3 phase motor short possible from MCP B; True = [1]";
CM_ SG_ 211 MC_PIM_A "Message counter according to SAE J1850 standard that has to be calculated from bit 63 to bit 8 at each frame transmission.";
CM_ SG_ 211 CRC_PIM_A "CRC according to SAE J1850 standard that has to be calculated from bit 63 to bit 8 at each frame transmission.";
CM_ SG_ 1811 Real_Time_Validity "EVCU Real Time Clock Validity";
CM_ SG_ 1811 Real_Time_Clock "EVCU Real Time Clock";
CM_ SG_ 1811 MessageCounter_REAL_TIME_CLOCK "This signal is a counter used for safety checks strategies. This counter is incremented of 1 (one) unit at each frame transmission.";
CM_ SG_ 1811 CRC_ANCHOR3_REAL_TIME_CLOCK "CRC according to SAE J1850 standard at each frame transmission.";
CM_ SG_ 215 Pinion_OverspeedWarning "Over Speed flag";
CM_ SG_ 215 PCU_Temporary_Stop_Flag "Temporary Stop Flag";
CM_ SG_ 215 PCU_MaxBoostedVoltage "Maximum Achievable Boosted Voltage";
CM_ SG_ 215 PCU_Max_DischargePowerLmt_ShrTrm "This signal indicates maximum boost converter discharge power limit for the short term";
CM_ SG_ 215 PCU_Max_DischargePowerLmt "Availability Wout";
CM_ SG_ 215 PCU_Max_ChargePowerLmt "Availability Win";
CM_ SG_ 215 PCU_DriveReadyCompletion_Status "PCU Drive Ready Completion Status";
CM_ SG_ 215 PCU_Diagnostic_Code "PCU Diagnostic code";
CM_ SG_ 215 Output_Torque_Limit "Output Torque Limit for Differential Protection (Abs/positive values only)";
CM_ SG_ 215 MessageCounter_PCU_FD_1 "This signal is a counter used for safety checks strategies. This counter is incremented of 1 (one) unit at each frame transmission.";
CM_ SG_ 215 MAC_PCU_FD_1 "MAC";
CM_ SG_ 215 DMPI_TransmissionTemperature "Transmission Oil Teperature";
CM_ SG_ 215 DMPI_OilTemperatureSts "Transmission oil temperature status flag";
CM_ SG_ 215 CRC_PCU_FD_1 "CRC according to SAE J1850 standard at each frame transmission.";
CM_ SG_ 215 Cntr_PCU_FD_1 "Cntr";
CM_ SG_ 215 BoostConverterFailureSts "Boost Converter Failure Status";
CM_ SG_ 215 BoostConverterDerateReason "Boost Converter Derate Reason";
CM_ SG_ 215 BoostConv_UpperIGBT_TempFltd "Boost converter lower IGBT temperature";
CM_ SG_ 215 BoostConv_LowerIGBT_TempFltd "Boost converter upper IGBT temperature";
CM_ SG_ 215 BoostConv_ReactorTemp "Boost converter reactor temperature";
BA_DEF_ BO_ "CANFD_BRS" ENUM "0","1";
BA_DEF_ BO_ "VFrameFormat" ENUM "StandardCAN","ExtendedCAN","reserved","reserved","reserved","reserved","reserved","reserved","reserved","reserved","reserved","reserved","reserved","reserved","StandardCAN_FD","ExtendedCAN_FD";
BA_DEF_ BO_ "DiagConnection" HEX 0 65535;
BA_DEF_ BO_ "DiagState" ENUM "No","Yes";
BA_DEF_ BO_ "NmAsrMessage" ENUM "No","Yes";
BA_DEF_ BO_ "GenMsgDelayTime" INT 0 65535;
BA_DEF_ BO_ "GenMsgCycleTime" INT 0 65535;
BA_DEF_ BO_ "GenMsgCycleTimeFast" INT 0 65535;
BA_DEF_ BO_ "GenMsgStartDelayTime" INT 0 65535;
BA_DEF_ BO_ "GenMsgILSupport" ENUM "No","Yes";
BA_DEF_ BO_ "GenMsgNrOfRepetition" INT 0 255;
BA_DEF_ BO_ "GenMsgSendType" ENUM "Cyclic","NotUsed","NotUsed","NotUsed","NotUsed","NotUsed","NotUsed","NotUsed","NoMsgSendType";
BA_DEF_ BO_ "NmMessage" ENUM "No","Yes";
BA_DEF_ BO_ "DiagResponse" ENUM "No","Yes";
BA_DEF_ BO_ "Type" ENUM "P","C","PE","COC","PE_Cntrl","E","E_Cntrl","OC","S","BAF","DC","EM","MM","ISO-TP","-";
BA_DEF_ BO_ "DiagRequest" ENUM "No","Yes";
BA_DEF_ SG_ "GenSigTimeoutTime_PBWM" INT 0 65535;
BA_DEF_ SG_ "GenSigTimeoutTime_MCPB" INT 0 65535;
BA_DEF_ SG_ "GenSigTimeoutTime_MCPA" INT 0 65535;
BA_DEF_ SG_ "GenSigTimeoutTime_IDCM" INT 0 65535;
BA_DEF_ SG_ "GenSigTimeoutTime_EVCU2" INT 0 65535;
BA_DEF_ SG_ "GenSigTimeoutTime_ECM" INT 0 65535;
BA_DEF_ SG_ "GenSigTimeoutTime_DMPI" INT 0 65535;
BA_DEF_ SG_ "GenSigTimeoutTime_BPCM" INT 0 65535;
BA_DEF_ SG_ "SystemSignalLongSymbol" STRING ;
BA_DEF_ SG_ "GenSigSendType" ENUM "NotUsed","OnWrite","OnWriteWithRepetition","OnChange","OnChangeWithRepetition","IfActive","IfActiveWithRepetition","NoSigSendType";
BA_DEF_ SG_ "GenSigInactiveValue" INT 0 2147483647;
BA_DEF_ SG_ "GenSigStartValue" INT 0 2147483647;
BA_DEF_DEF_ "CANFD_BRS" "0";
BA_DEF_DEF_ "VFrameFormat" "StandardCAN_FD";
BA_DEF_DEF_ "DiagConnection" 0;
BA_DEF_DEF_ "DiagState" "No";
BA_DEF_DEF_ "NmAsrMessage" "No";
BA_DEF_DEF_ "GenMsgDelayTime" 0;
BA_DEF_DEF_ "GenMsgCycleTime" 0;
BA_DEF_DEF_ "GenMsgCycleTimeFast" 0;
BA_DEF_DEF_ "GenMsgStartDelayTime" 0;
BA_DEF_DEF_ "GenMsgILSupport" "No";
BA_DEF_DEF_ "GenMsgNrOfRepetition" 0;
BA_DEF_DEF_ "GenMsgSendType" "NoMsgSendType";
BA_DEF_DEF_ "NmMessage" "No";
BA_DEF_DEF_ "DiagResponse" "No";
BA_DEF_DEF_ "Type" "-";
BA_DEF_DEF_ "DiagRequest" "No";
BA_DEF_DEF_ "GenSigTimeoutTime_PBWM" 2500;
BA_DEF_DEF_ "GenSigTimeoutTime_MCPB" 2500;
BA_DEF_DEF_ "GenSigTimeoutTime_MCPA" 2500;
BA_DEF_DEF_ "GenSigTimeoutTime_IDCM" 2500;
BA_DEF_DEF_ "GenSigTimeoutTime_EVCU2" 2500;
BA_DEF_DEF_ "GenSigTimeoutTime_ECM" 2500;
BA_DEF_DEF_ "GenSigTimeoutTime_DMPI" 2500;
BA_DEF_DEF_ "GenSigTimeoutTime_BPCM" 2500;
BA_DEF_DEF_ "SystemSignalLongSymbol" "";
BA_DEF_DEF_ "GenSigSendType" "NoSigSendType";
BA_DEF_DEF_ "GenSigInactiveValue" 0;
BA_DEF_DEF_ "GenSigStartValue" 0;
BA_ "CANFD_BRS" BO_ 2564554485 1;
BA_ "VFrameFormat" BO_ 2564554485 15;
BA_ "DiagConnection" BO_ 2564554485 62974;
BA_ "DiagState" BO_ 2564554485 1;
BA_ "Type" BO_ 2564554485 8;
BA_ "Type" BO_ 292 1;
BA_ "CANFD_BRS" BO_ 292 1;
BA_ "GenMsgCycleTime" BO_ 292 10;
BA_ "GenMsgILSupport" BO_ 292 1;
BA_ "GenMsgSendType" BO_ 292 0;
BA_ "CANFD_BRS" BO_ 485 1;
BA_ "GenMsgCycleTime" BO_ 485 20;
BA_ "GenMsgILSupport" BO_ 485 1;
BA_ "GenMsgSendType" BO_ 485 0;
BA_ "Type" BO_ 485 1;
BA_ "CANFD_BRS" BO_ 288 1;
BA_ "GenMsgCycleTime" BO_ 288 10;
BA_ "GenMsgILSupport" BO_ 288 1;
BA_ "GenMsgSendType" BO_ 288 0;
BA_ "Type" BO_ 288 1;
BA_ "CANFD_BRS" BO_ 2654339161 1;
BA_ "VFrameFormat" BO_ 2654339161 15;
BA_ "GenMsgCycleTime" BO_ 2654339161 1000;
BA_ "GenMsgILSupport" BO_ 2654339161 1;
BA_ "GenMsgSendType" BO_ 2654339161 0;
BA_ "Type" BO_ 2654339161 1;
BA_ "CANFD_BRS" BO_ 2654339160 1;
BA_ "VFrameFormat" BO_ 2654339160 15;
BA_ "GenMsgCycleTime" BO_ 2654339160 1000;
BA_ "GenMsgILSupport" BO_ 2654339160 1;
BA_ "GenMsgSendType" BO_ 2654339160 0;
BA_ "Type" BO_ 2654339160 1;
BA_ "CANFD_BRS" BO_ 263 1;
BA_ "GenMsgCycleTime" BO_ 263 10;
BA_ "GenMsgILSupport" BO_ 263 1;
BA_ "GenMsgSendType" BO_ 263 0;
BA_ "Type" BO_ 263 1;
BA_ "CANFD_BRS" BO_ 216 1;
BA_ "GenMsgCycleTime" BO_ 216 10;
BA_ "GenMsgILSupport" BO_ 216 1;
BA_ "GenMsgSendType" BO_ 216 0;
BA_ "Type" BO_ 216 1;
BA_ "CANFD_BRS" BO_ 1041 1;
BA_ "GenMsgCycleTime" BO_ 1041 100;
BA_ "GenMsgILSupport" BO_ 1041 1;
BA_ "GenMsgSendType" BO_ 1041 0;
BA_ "Type" BO_ 1041 1;
BA_ "CANFD_BRS" BO_ 2654486592 1;
BA_ "VFrameFormat" BO_ 2654486592 15;
BA_ "NmAsrMessage" BO_ 2654486592 1;
BA_ "NmMessage" BO_ 2654486592 1;
BA_ "Type" BO_ 2654486592 8;
BA_ "CANFD_BRS" BO_ 212 1;
BA_ "GenMsgCycleTime" BO_ 212 10;
BA_ "GenMsgILSupport" BO_ 212 1;
BA_ "GenMsgSendType" BO_ 212 0;
BA_ "Type" BO_ 212 1;
BA_ "CANFD_BRS" BO_ 211 1;
BA_ "GenMsgCycleTime" BO_ 211 10;
BA_ "GenMsgILSupport" BO_ 211 1;
BA_ "GenMsgSendType" BO_ 211 0;
BA_ "Type" BO_ 211 1;
BA_ "GenMsgDelayTime" BO_ 1811 20;
BA_ "GenMsgCycleTime" BO_ 1811 1000;
BA_ "CANFD_BRS" BO_ 1811 1;
BA_ "GenMsgILSupport" BO_ 1811 1;
BA_ "GenMsgSendType" BO_ 1811 0;
BA_ "Type" BO_ 1811 1;
BA_ "CANFD_BRS" BO_ 215 1;
BA_ "GenMsgCycleTime" BO_ 215 10;
BA_ "GenMsgILSupport" BO_ 215 1;
BA_ "GenMsgSendType" BO_ 215 0;
BA_ "Type" BO_ 215 1;
BA_ "GenSigTimeoutTime_PBWM" SG_ 1811 MessageCounter_REAL_TIME_CLOCK 0;
BA_ "GenSigTimeoutTime_MCPB" SG_ 1811 MessageCounter_REAL_TIME_CLOCK 0;
BA_ "GenSigTimeoutTime_MCPA" SG_ 1811 MessageCounter_REAL_TIME_CLOCK 0;
BA_ "GenSigTimeoutTime_IDCM" SG_ 1811 MessageCounter_REAL_TIME_CLOCK 0;
BA_ "GenSigTimeoutTime_EVCU2" SG_ 1811 MessageCounter_REAL_TIME_CLOCK 0;
BA_ "GenSigTimeoutTime_ECM" SG_ 1811 MessageCounter_REAL_TIME_CLOCK 0;
BA_ "GenSigTimeoutTime_BPCM" SG_ 1811 MessageCounter_REAL_TIME_CLOCK 0;
BA_ "GenSigTimeoutTime_PBWM" SG_ 1811 CRC_ANCHOR3_REAL_TIME_CLOCK 0;
BA_ "GenSigTimeoutTime_MCPB" SG_ 1811 CRC_ANCHOR3_REAL_TIME_CLOCK 0;
BA_ "GenSigTimeoutTime_MCPA" SG_ 1811 CRC_ANCHOR3_REAL_TIME_CLOCK 0;
BA_ "GenSigTimeoutTime_IDCM" SG_ 1811 CRC_ANCHOR3_REAL_TIME_CLOCK 0;
BA_ "GenSigTimeoutTime_EVCU2" SG_ 1811 CRC_ANCHOR3_REAL_TIME_CLOCK 0;
BA_ "GenSigTimeoutTime_ECM" SG_ 1811 CRC_ANCHOR3_REAL_TIME_CLOCK 0;
BA_ "GenSigTimeoutTime_BPCM" SG_ 1811 CRC_ANCHOR3_REAL_TIME_CLOCK 0;
BA_ "GenSigTimeoutTime_PBWM" SG_ 1811 Real_Time_Validity 0;
BA_ "GenSigTimeoutTime_IDCM" SG_ 1811 Real_Time_Validity 0;
BA_ "GenSigTimeoutTime_EVCU2" SG_ 1811 Real_Time_Validity 0;
BA_ "GenSigTimeoutTime_ECM" SG_ 1811 Real_Time_Validity 0;
BA_ "GenSigTimeoutTime_BPCM" SG_ 1811 Real_Time_Validity 0;
BA_ "GenSigTimeoutTime_PBWM" SG_ 1811 Real_Time_Clock 0;
BA_ "GenSigTimeoutTime_IDCM" SG_ 1811 Real_Time_Clock 0;
BA_ "GenSigTimeoutTime_EVCU2" SG_ 1811 Real_Time_Clock 0;
BA_ "GenSigTimeoutTime_ECM" SG_ 1811 Real_Time_Clock 0;
BA_ "GenSigTimeoutTime_BPCM" SG_ 1811 Real_Time_Clock 0;
BA_ "GenSigTimeoutTime_MCPA" SG_ 263 ParkCmd_PT 0;
BA_ "GenSigTimeoutTime_IDCM" SG_ 263 ParkCmd_PT 0;
BA_ "GenSigTimeoutTime_EVCU2" SG_ 263 ParkCmd_PT 0;
BA_ "GenSigTimeoutTime_ECM" SG_ 263 ParkCmd_PT 0;
BA_ "GenSigTimeoutTime_DMPI" SG_ 263 ParkCmd_PT 0;
BA_ "GenSigTimeoutTime_BPCM" SG_ 263 ParkCmd_PT 0;
BA_ "GenSigTimeoutTime_MCPB" SG_ 263 ParkCmd_PT 0;
BA_ "GenSigTimeoutTime_PBWM" SG_ 263 ShiftLeverPosition_PT 0;
BA_ "GenSigTimeoutTime_MCPB" SG_ 263 ShiftLeverPosition_PT 0;
BA_ "GenSigTimeoutTime_MCPA" SG_ 263 ShiftLeverPosition_PT 0;
BA_ "GenSigTimeoutTime_IDCM" SG_ 263 ShiftLeverPosition_PT 0;
BA_ "GenSigTimeoutTime_EVCU2" SG_ 263 ShiftLeverPosition_PT 0;
BA_ "GenSigTimeoutTime_ECM" SG_ 263 ShiftLeverPosition_PT 0;
BA_ "GenSigTimeoutTime_BPCM" SG_ 263 ShiftLeverPosition_PT 0;
BA_ "GenSigTimeoutTime_MCPA" SG_ 263 MessageCounter_PT_SYSTEM_FD_1 0;
BA_ "GenSigTimeoutTime_PBWM" SG_ 263 PowertrainPrplsnActv_PT 0;
BA_ "GenSigTimeoutTime_IDCM" SG_ 263 PowertrainPrplsnActv_PT 0;
BA_ "GenSigTimeoutTime_EVCU2" SG_ 263 PowertrainPrplsnActv_PT 0;
BA_ "GenSigTimeoutTime_ECM" SG_ 263 PowertrainPrplsnActv_PT 0;
BA_ "GenSigTimeoutTime_DMPI" SG_ 263 PowertrainPrplsnActv_PT 0;
BA_ "GenSigTimeoutTime_PBWM" SG_ 263 OptimdStrtReqdActr 0;
BA_ "GenSigTimeoutTime_MCPB" SG_ 263 OptimdStrtReqdActr 0;
BA_ "GenSigTimeoutTime_MCPA" SG_ 263 OptimdStrtReqdActr 0;
BA_ "GenSigTimeoutTime_IDCM" SG_ 263 OptimdStrtReqdActr 0;
BA_ "GenSigTimeoutTime_EVCU2" SG_ 263 OptimdStrtReqdActr 0;
BA_ "GenSigTimeoutTime_DMPI" SG_ 263 OptimdStrtReqdActr 0;
BA_ "GenSigTimeoutTime_BPCM" SG_ 263 OptimdStrtReqdActr 0;
BA_ "GenSigTimeoutTime_PBWM" SG_ 263 OptimdEngOnOffCmd 0;
BA_ "GenSigTimeoutTime_MCPB" SG_ 263 OptimdEngOnOffCmd 0;
BA_ "GenSigTimeoutTime_MCPA" SG_ 263 OptimdEngOnOffCmd 0;
BA_ "GenSigTimeoutTime_IDCM" SG_ 263 OptimdEngOnOffCmd 0;
BA_ "GenSigTimeoutTime_EVCU2" SG_ 263 OptimdEngOnOffCmd 0;
BA_ "GenSigTimeoutTime_DMPI" SG_ 263 OptimdEngOnOffCmd 0;
BA_ "GenSigTimeoutTime_BPCM" SG_ 263 OptimdEngOnOffCmd 0;
BA_ "GenSigTimeoutTime_PBWM" SG_ 263 OptimdEngStrtStpType 0;
BA_ "GenSigTimeoutTime_MCPB" SG_ 263 OptimdEngStrtStpType 0;
BA_ "GenSigTimeoutTime_MCPA" SG_ 263 OptimdEngStrtStpType 0;
BA_ "GenSigTimeoutTime_IDCM" SG_ 263 OptimdEngStrtStpType 0;
BA_ "GenSigTimeoutTime_EVCU2" SG_ 263 OptimdEngStrtStpType 0;
BA_ "GenSigTimeoutTime_DMPI" SG_ 263 OptimdEngStrtStpType 0;
BA_ "GenSigTimeoutTime_BPCM" SG_ 263 OptimdEngStrtStpType 0;
BA_ "GenSigTimeoutTime_MCPB" SG_ 263 EVCU_END_Request_Flag_PT 0;
BA_ "GenSigTimeoutTime_MCPA" SG_ 263 EVCU_END_Request_Flag_PT 0;
BA_ "GenSigTimeoutTime_IDCM" SG_ 263 EVCU_END_Request_Flag_PT 0;
BA_ "GenSigTimeoutTime_EVCU2" SG_ 263 EVCU_END_Request_Flag_PT 0;
BA_ "GenSigTimeoutTime_ECM" SG_ 263 EVCU_END_Request_Flag_PT 0;
BA_ "GenSigTimeoutTime_DMPI" SG_ 263 EVCU_END_Request_Flag_PT 0;
BA_ "GenSigTimeoutTime_BPCM" SG_ 263 EVCU_END_Request_Flag_PT 0;
BA_ "GenSigTimeoutTime_PBWM" SG_ 216 BMS_HV_Char_Main_Contac_Cmd_PT 0;
BA_ "GenSigTimeoutTime_MCPB" SG_ 216 BMS_HV_Char_Main_Contac_Cmd_PT 0;
BA_ "GenSigTimeoutTime_MCPA" SG_ 216 BMS_HV_Char_Main_Contac_Cmd_PT 0;
BA_ "GenSigTimeoutTime_IDCM" SG_ 216 BMS_HV_Char_Main_Contac_Cmd_PT 0;
BA_ "GenSigTimeoutTime_EVCU2" SG_ 216 BMS_HV_Char_Main_Contac_Cmd_PT 0;
BA_ "GenSigTimeoutTime_ECM" SG_ 216 BMS_HV_Char_Main_Contac_Cmd_PT 0;
BA_ "GenSigTimeoutTime_DMPI" SG_ 216 BMS_HV_Char_Main_Contac_Cmd_PT 0;
BA_ "GenSigTimeoutTime_PBWM" SG_ 263 HCPFuelDisable 0;
BA_ "GenSigTimeoutTime_MCPB" SG_ 263 HCPFuelDisable 0;
BA_ "GenSigTimeoutTime_MCPA" SG_ 263 HCPFuelDisable 0;
BA_ "GenSigTimeoutTime_IDCM" SG_ 263 HCPFuelDisable 0;
BA_ "GenSigTimeoutTime_EVCU2" SG_ 263 HCPFuelDisable 0;
BA_ "GenSigTimeoutTime_DMPI" SG_ 263 HCPFuelDisable 0;
BA_ "GenSigTimeoutTime_BPCM" SG_ 263 HCPFuelDisable 0;
BA_ "GenSigStartValue" SG_ 263 HCPFuelDisable 1;
BA_ "GenSigTimeoutTime_PBWM" SG_ 263 Hyb_ProducingTorque 0;
BA_ "GenSigTimeoutTime_MCPB" SG_ 263 Hyb_ProducingTorque 0;
BA_ "GenSigTimeoutTime_MCPA" SG_ 263 Hyb_ProducingTorque 0;
BA_ "GenSigTimeoutTime_IDCM" SG_ 263 Hyb_ProducingTorque 0;
BA_ "GenSigTimeoutTime_EVCU2" SG_ 263 Hyb_ProducingTorque 0;
BA_ "GenSigTimeoutTime_DMPI" SG_ 263 Hyb_ProducingTorque 0;
BA_ "GenSigTimeoutTime_BPCM" SG_ 263 Hyb_ProducingTorque 0;
BA_ "GenSigTimeoutTime_PBWM" SG_ 263 GearEngaged_PT 0;
BA_ "GenSigTimeoutTime_MCPA" SG_ 263 GearEngaged_PT 0;
BA_ "GenSigTimeoutTime_IDCM" SG_ 263 GearEngaged_PT 0;
BA_ "GenSigTimeoutTime_EVCU2" SG_ 263 GearEngaged_PT 0;
BA_ "GenSigTimeoutTime_ECM" SG_ 263 GearEngaged_PT 0;
BA_ "GenSigTimeoutTime_DMPI" SG_ 263 GearEngaged_PT 0;
BA_ "GenSigTimeoutTime_BPCM" SG_ 263 GearEngaged_PT 0;
BA_ "GenSigTimeoutTime_IDCM" SG_ 263 GearEngagedForDisplay_PT 0;
BA_ "GenSigTimeoutTime_EVCU2" SG_ 263 GearEngagedForDisplay_PT 0;
BA_ "GenSigTimeoutTime_ECM" SG_ 263 GearEngagedForDisplay_PT 0;
BA_ "GenSigTimeoutTime_DMPI" SG_ 263 GearEngagedForDisplay_PT 0;
BA_ "GenSigTimeoutTime_PBWM" SG_ 216 DCChargeInitialized_PT 0;
BA_ "GenSigTimeoutTime_MCPB" SG_ 216 DCChargeInitialized_PT 0;
BA_ "GenSigTimeoutTime_MCPA" SG_ 216 DCChargeInitialized_PT 0;
BA_ "GenSigTimeoutTime_IDCM" SG_ 216 DCChargeInitialized_PT 0;
BA_ "GenSigTimeoutTime_EVCU2" SG_ 216 DCChargeInitialized_PT 0;
BA_ "GenSigTimeoutTime_ECM" SG_ 216 DCChargeInitialized_PT 0;
BA_ "GenSigTimeoutTime_DMPI" SG_ 216 DCChargeInitialized_PT 0;
BA_ "GenSigTimeoutTime_PBWM" SG_ 216 DCChrgCurrentLimit_PT 0;
BA_ "GenSigTimeoutTime_MCPB" SG_ 216 DCChrgCurrentLimit_PT 0;
BA_ "GenSigTimeoutTime_MCPA" SG_ 216 DCChrgCurrentLimit_PT 0;
BA_ "GenSigTimeoutTime_IDCM" SG_ 216 DCChrgCurrentLimit_PT 0;
BA_ "GenSigTimeoutTime_EVCU2" SG_ 216 DCChrgCurrentLimit_PT 0;
BA_ "GenSigTimeoutTime_ECM" SG_ 216 DCChrgCurrentLimit_PT 0;
BA_ "GenSigTimeoutTime_DMPI" SG_ 216 DCChrgCurrentLimit_PT 0;
BA_ "GenSigTimeoutTime_BPCM" SG_ 216 DCChrgCurrentLimit_PT 0;
BA_ "GenSigStartValue" SG_ 216 DCChrgCurrentLimit_PT 815;
BA_ "GenSigTimeoutTime_PBWM" SG_ 216 DCChrgCurrentRq_PT 0;
BA_ "GenSigTimeoutTime_MCPB" SG_ 216 DCChrgCurrentRq_PT 0;
BA_ "GenSigTimeoutTime_MCPA" SG_ 216 DCChrgCurrentRq_PT 0;
BA_ "GenSigTimeoutTime_IDCM" SG_ 216 DCChrgCurrentRq_PT 0;
BA_ "GenSigTimeoutTime_EVCU2" SG_ 216 DCChrgCurrentRq_PT 0;
BA_ "GenSigTimeoutTime_ECM" SG_ 216 DCChrgCurrentRq_PT 0;
BA_ "GenSigTimeoutTime_DMPI" SG_ 216 DCChrgCurrentRq_PT 0;
BA_ "GenSigTimeoutTime_BPCM" SG_ 216 DCChrgCurrentRq_PT 0;
BA_ "GenSigStartValue" SG_ 216 DCChrgCurrentRq_PT 815;
BA_ "GenSigTimeoutTime_PBWM" SG_ 216 DCChrgPwrLim_PT 0;
BA_ "GenSigTimeoutTime_MCPB" SG_ 216 DCChrgPwrLim_PT 0;
BA_ "GenSigTimeoutTime_MCPA" SG_ 216 DCChrgPwrLim_PT 0;
BA_ "GenSigTimeoutTime_IDCM" SG_ 216 DCChrgPwrLim_PT 0;
BA_ "GenSigTimeoutTime_EVCU2" SG_ 216 DCChrgPwrLim_PT 0;
BA_ "GenSigTimeoutTime_ECM" SG_ 216 DCChrgPwrLim_PT 0;
BA_ "GenSigTimeoutTime_DMPI" SG_ 216 DCChrgPwrLim_PT 0;
BA_ "GenSigTimeoutTime_BPCM" SG_ 216 DCChrgPwrLim_PT 0;
BA_ "GenSigStartValue" SG_ 216 DCChrgPwrLim_PT 815;
BA_ "GenSigTimeoutTime_PBWM" SG_ 216 DCChrgVoltMax_PT 0;
BA_ "GenSigTimeoutTime_MCPB" SG_ 216 DCChrgVoltMax_PT 0;
BA_ "GenSigTimeoutTime_MCPA" SG_ 216 DCChrgVoltMax_PT 0;
BA_ "GenSigTimeoutTime_IDCM" SG_ 216 DCChrgVoltMax_PT 0;
BA_ "GenSigTimeoutTime_EVCU2" SG_ 216 DCChrgVoltMax_PT 0;
BA_ "GenSigTimeoutTime_ECM" SG_ 216 DCChrgVoltMax_PT 0;
BA_ "GenSigTimeoutTime_DMPI" SG_ 216 DCChrgVoltMax_PT 0;
BA_ "GenSigTimeoutTime_BPCM" SG_ 216 DCChrgVoltMax_PT 0;
BA_ "GenSigTimeoutTime_PBWM" SG_ 216 DCChrgVoltMin_PT 0;
BA_ "GenSigTimeoutTime_MCPB" SG_ 216 DCChrgVoltMin_PT 0;
BA_ "GenSigTimeoutTime_MCPA" SG_ 216 DCChrgVoltMin_PT 0;
BA_ "GenSigTimeoutTime_IDCM" SG_ 216 DCChrgVoltMin_PT 0;
BA_ "GenSigTimeoutTime_EVCU2" SG_ 216 DCChrgVoltMin_PT 0;
BA_ "GenSigTimeoutTime_ECM" SG_ 216 DCChrgVoltMin_PT 0;
BA_ "GenSigTimeoutTime_DMPI" SG_ 216 DCChrgVoltMin_PT 0;
BA_ "GenSigTimeoutTime_BPCM" SG_ 216 DCChrgVoltMin_PT 0;
BA_ "GenSigTimeoutTime_PBWM" SG_ 216 MC_PT_ENERGY_FD_1 0;
BA_ "GenSigTimeoutTime_MCPB" SG_ 216 MC_PT_ENERGY_FD_1 0;
BA_ "GenSigTimeoutTime_MCPA" SG_ 216 MC_PT_ENERGY_FD_1 0;
BA_ "GenSigTimeoutTime_EVCU2" SG_ 216 MC_PT_ENERGY_FD_1 0;
BA_ "GenSigTimeoutTime_ECM" SG_ 216 MC_PT_ENERGY_FD_1 0;
BA_ "GenSigTimeoutTime_PBWM" SG_ 263 DriveReady_PT 0;
BA_ "GenSigTimeoutTime_MCPB" SG_ 263 DriveReady_PT 0;
BA_ "GenSigTimeoutTime_MCPA" SG_ 263 DriveReady_PT 0;
BA_ "GenSigTimeoutTime_IDCM" SG_ 263 DriveReady_PT 0;
BA_ "GenSigTimeoutTime_EVCU2" SG_ 263 DriveReady_PT 0;
BA_ "GenSigTimeoutTime_ECM" SG_ 263 DriveReady_PT 0;
BA_ "GenSigTimeoutTime_DMPI" SG_ 263 DriveReady_PT 0;
BA_ "GenSigTimeoutTime_PBWM" SG_ 216 APM_HV_IMax_PT 0;
BA_ "GenSigTimeoutTime_MCPB" SG_ 216 APM_HV_IMax_PT 0;
BA_ "GenSigTimeoutTime_MCPA" SG_ 216 APM_HV_IMax_PT 0;
BA_ "GenSigTimeoutTime_EVCU2" SG_ 216 APM_HV_IMax_PT 0;
BA_ "GenSigTimeoutTime_ECM" SG_ 216 APM_HV_IMax_PT 0;
BA_ "GenSigTimeoutTime_DMPI" SG_ 216 APM_HV_IMax_PT 0;
BA_ "GenSigTimeoutTime_BPCM" SG_ 216 APM_HV_IMax_PT 0;
BA_ "GenSigTimeoutTime_PBWM" SG_ 216 APM_LV_IMax_PT 0;
BA_ "GenSigTimeoutTime_MCPB" SG_ 216 APM_LV_IMax_PT 0;
BA_ "GenSigTimeoutTime_MCPA" SG_ 216 APM_LV_IMax_PT 0;
BA_ "GenSigTimeoutTime_EVCU2" SG_ 216 APM_LV_IMax_PT 0;
BA_ "GenSigTimeoutTime_ECM" SG_ 216 APM_LV_IMax_PT 0;
BA_ "GenSigTimeoutTime_DMPI" SG_ 216 APM_LV_IMax_PT 0;
BA_ "GenSigTimeoutTime_BPCM" SG_ 216 APM_LV_IMax_PT 0;
BA_ "GenSigTimeoutTime_EVCU2" SG_ 216 APM_LV_VActual_PT 0;
BA_ "GenSigTimeoutTime_ECM" SG_ 216 APM_LV_VActual_PT 0;
BA_ "GenSigTimeoutTime_DMPI" SG_ 216 APM_LV_VActual_PT 0;
BA_ "GenSigTimeoutTime_BPCM" SG_ 216 APM_LV_VActual_PT 0;
BA_ "GenSigTimeoutTime_PBWM" SG_ 216 APM_LV_VActual_PT 0;
BA_ "GenSigTimeoutTime_MCPB" SG_ 216 APM_LV_VActual_PT 0;
BA_ "GenSigTimeoutTime_MCPA" SG_ 216 APM_LV_VActual_PT 0;
BA_ "GenSigTimeoutTime_PBWM" SG_ 216 APM_LV_VsetPoint_PT 0;
BA_ "GenSigTimeoutTime_MCPB" SG_ 216 APM_LV_VsetPoint_PT 0;
BA_ "GenSigTimeoutTime_MCPA" SG_ 216 APM_LV_VsetPoint_PT 0;
BA_ "GenSigTimeoutTime_EVCU2" SG_ 216 APM_LV_VsetPoint_PT 0;
BA_ "GenSigTimeoutTime_ECM" SG_ 216 APM_LV_VsetPoint_PT 0;
BA_ "GenSigTimeoutTime_BPCM" SG_ 216 APM_LV_VsetPoint_PT 0;
BA_ "GenSigTimeoutTime_PBWM" SG_ 216 BatteryVoltage_Raw_PT 0;
BA_ "GenSigTimeoutTime_EVCU2" SG_ 216 BatteryVoltage_Raw_PT 0;
BA_ "GenSigTimeoutTime_ECM" SG_ 216 BatteryVoltage_Raw_PT 0;
BA_ "GenSigTimeoutTime_DMPI" SG_ 216 BatteryVoltage_Raw_PT 0;
BA_ "GenSigTimeoutTime_PBWM" SG_ 216 BMS_HV_DC_Chrgng_Cntct_K_Cmd_PT 0;
BA_ "GenSigTimeoutTime_EVCU2" SG_ 216 BMS_HV_DC_Chrgng_Cntct_K_Cmd_PT 0;
BA_ "GenSigTimeoutTime_ECM" SG_ 216 BMS_HV_DC_Chrgng_Cntct_K_Cmd_PT 0;
BA_ "GenSigTimeoutTime_DMPI" SG_ 216 BMS_HV_DC_Chrgng_Cntct_K_Cmd_PT 0;
BA_ "GenSigTimeoutTime_PBWM" SG_ 216 BMS_HV_GFD_Inhibition_PT 0;
BA_ "GenSigTimeoutTime_MCPB" SG_ 216 BMS_HV_GFD_Inhibition_PT 0;
BA_ "GenSigTimeoutTime_MCPA" SG_ 216 BMS_HV_GFD_Inhibition_PT 0;
BA_ "GenSigTimeoutTime_IDCM" SG_ 216 BMS_HV_GFD_Inhibition_PT 0;
BA_ "GenSigTimeoutTime_EVCU2" SG_ 216 BMS_HV_GFD_Inhibition_PT 0;
BA_ "GenSigTimeoutTime_ECM" SG_ 216 BMS_HV_GFD_Inhibition_PT 0;
BA_ "GenSigTimeoutTime_DMPI" SG_ 216 BMS_HV_GFD_Inhibition_PT 0;
BA_ "GenSigTimeoutTime_PBWM" SG_ 216 BMS_HV_RefTracHVBus_V_PT 0;
BA_ "GenSigTimeoutTime_MCPB" SG_ 216 BMS_HV_RefTracHVBus_V_PT 0;
BA_ "GenSigTimeoutTime_MCPA" SG_ 216 BMS_HV_RefTracHVBus_V_PT 0;
BA_ "GenSigTimeoutTime_IDCM" SG_ 216 BMS_HV_RefTracHVBus_V_PT 0;
BA_ "GenSigTimeoutTime_EVCU2" SG_ 216 BMS_HV_RefTracHVBus_V_PT 0;
BA_ "GenSigTimeoutTime_ECM" SG_ 216 BMS_HV_RefTracHVBus_V_PT 0;
BA_ "GenSigTimeoutTime_DMPI" SG_ 216 BMS_HV_RefTracHVBus_V_PT 0;
BA_ "GenSigTimeoutTime_PBWM" SG_ 216 BMS_HV_RefTracHVBus_V_Vldty_PT 0;
BA_ "GenSigTimeoutTime_MCPB" SG_ 216 BMS_HV_RefTracHVBus_V_Vldty_PT 0;
BA_ "GenSigTimeoutTime_MCPA" SG_ 216 BMS_HV_RefTracHVBus_V_Vldty_PT 0;
BA_ "GenSigTimeoutTime_IDCM" SG_ 216 BMS_HV_RefTracHVBus_V_Vldty_PT 0;
BA_ "GenSigTimeoutTime_EVCU2" SG_ 216 BMS_HV_RefTracHVBus_V_Vldty_PT 0;
BA_ "GenSigTimeoutTime_ECM" SG_ 216 BMS_HV_RefTracHVBus_V_Vldty_PT 0;
BA_ "GenSigTimeoutTime_DMPI" SG_ 216 BMS_HV_RefTracHVBus_V_Vldty_PT 0;
BA_ "GenSigTimeoutTime_PBWM" SG_ 216 BMS_HV_TracCntctr_Cmd_PT 0;
BA_ "GenSigTimeoutTime_EVCU2" SG_ 216 BMS_HV_TracCntctr_Cmd_PT 0;
BA_ "GenSigTimeoutTime_ECM" SG_ 216 BMS_HV_TracCntctr_Cmd_PT 0;
BA_ "GenSigTimeoutTime_DMPI" SG_ 216 BMS_HV_TracCntctr_Cmd_PT 0;
BA_ "GenSigTimeoutTime_PBWM" SG_ 216 BPCM_OBCM_AC_ContactorCmd_PT 0;
BA_ "GenSigTimeoutTime_MCPB" SG_ 216 BPCM_OBCM_AC_ContactorCmd_PT 0;
BA_ "GenSigTimeoutTime_MCPA" SG_ 216 BPCM_OBCM_AC_ContactorCmd_PT 0;
BA_ "GenSigTimeoutTime_EVCU2" SG_ 216 BPCM_OBCM_AC_ContactorCmd_PT 0;
BA_ "GenSigTimeoutTime_ECM" SG_ 216 BPCM_OBCM_AC_ContactorCmd_PT 0;
BA_ "GenSigTimeoutTime_DMPI" SG_ 216 BPCM_OBCM_AC_ContactorCmd_PT 0;
BA_ "GenSigTimeoutTime_PBWM" SG_ 216 CRC_PT_ENERGY_FD_1 0;
BA_ "GenSigTimeoutTime_MCPB" SG_ 216 CRC_PT_ENERGY_FD_1 0;
BA_ "GenSigTimeoutTime_MCPA" SG_ 216 CRC_PT_ENERGY_FD_1 0;
BA_ "GenSigTimeoutTime_EVCU2" SG_ 216 CRC_PT_ENERGY_FD_1 0;
BA_ "GenSigTimeoutTime_ECM" SG_ 216 CRC_PT_ENERGY_FD_1 0;
BA_ "GenSigTimeoutTime_PBWM" SG_ 216 DCChargeEnRq_PT 0;
BA_ "GenSigTimeoutTime_MCPB" SG_ 216 DCChargeEnRq_PT 0;
BA_ "GenSigTimeoutTime_MCPA" SG_ 216 DCChargeEnRq_PT 0;
BA_ "GenSigTimeoutTime_IDCM" SG_ 216 DCChargeEnRq_PT 0;
BA_ "GenSigTimeoutTime_EVCU2" SG_ 216 DCChargeEnRq_PT 0;
BA_ "GenSigTimeoutTime_ECM" SG_ 216 DCChargeEnRq_PT 0;
BA_ "GenSigTimeoutTime_DMPI" SG_ 216 DCChargeEnRq_PT 0;
BA_ "GenSigTimeoutTime_BPCM" SG_ 216 DCChargeEnRq_PT 0;
BA_ "GenSigTimeoutTime_IDCM" SG_ 263 MessageCounter_PT_SYSTEM_FD_1 0;
BA_ "GenSigTimeoutTime_EVCU2" SG_ 263 MessageCounter_PT_SYSTEM_FD_1 0;
BA_ "GenSigTimeoutTime_ECM" SG_ 263 MessageCounter_PT_SYSTEM_FD_1 0;
BA_ "GenSigTimeoutTime_DMPI" SG_ 263 MessageCounter_PT_SYSTEM_FD_1 0;
BA_ "GenSigTimeoutTime_BPCM" SG_ 263 MessageCounter_PT_SYSTEM_FD_1 0;
BA_ "GenSigTimeoutTime_MCPA" SG_ 263 CRC_PT_SYSTEM_FD_1 0;
BA_ "GenSigTimeoutTime_IDCM" SG_ 263 CRC_PT_SYSTEM_FD_1 0;
BA_ "GenSigTimeoutTime_EVCU2" SG_ 263 CRC_PT_SYSTEM_FD_1 0;
BA_ "GenSigTimeoutTime_ECM" SG_ 263 CRC_PT_SYSTEM_FD_1 0;
BA_ "GenSigTimeoutTime_DMPI" SG_ 263 CRC_PT_SYSTEM_FD_1 0;
BA_ "GenSigTimeoutTime_BPCM" SG_ 263 CRC_PT_SYSTEM_FD_1 0;
BA_ "GenSigTimeoutTime_PBWM" SG_ 216 APM_TypeCtrl_PT 0;
BA_ "GenSigTimeoutTime_MCPB" SG_ 216 APM_TypeCtrl_PT 0;
BA_ "GenSigTimeoutTime_MCPA" SG_ 216 APM_TypeCtrl_PT 0;
BA_ "GenSigTimeoutTime_EVCU2" SG_ 216 APM_TypeCtrl_PT 0;
BA_ "GenSigTimeoutTime_ECM" SG_ 216 APM_TypeCtrl_PT 0;
BA_ "GenSigTimeoutTime_PBWM" SG_ 212 PIM_B_Torque_Achieved_V 0;
BA_ "GenSigTimeoutTime_MCPB" SG_ 212 PIM_B_Torque_Achieved_V 0;
BA_ "GenSigTimeoutTime_MCPA" SG_ 212 PIM_B_Torque_Achieved_V 0;
BA_ "GenSigTimeoutTime_IDCM" SG_ 212 PIM_B_Torque_Achieved_V 0;
BA_ "GenSigTimeoutTime_ECM" SG_ 212 PIM_B_Torque_Achieved_V 0;
BA_ "GenSigTimeoutTime_DMPI" SG_ 212 PIM_B_Torque_Achieved_V 0;
BA_ "GenSigTimeoutTime_BPCM" SG_ 212 PIM_B_Torque_Achieved_V 0;
BA_ "GenSigTimeoutTime_PBWM" SG_ 212 PIM_B_Torque_Achieved 0;
BA_ "GenSigTimeoutTime_MCPB" SG_ 212 PIM_B_Torque_Achieved 0;
BA_ "GenSigTimeoutTime_MCPA" SG_ 212 PIM_B_Torque_Achieved 0;
BA_ "GenSigTimeoutTime_IDCM" SG_ 212 PIM_B_Torque_Achieved 0;
BA_ "GenSigTimeoutTime_ECM" SG_ 212 PIM_B_Torque_Achieved 0;
BA_ "GenSigTimeoutTime_DMPI" SG_ 212 PIM_B_Torque_Achieved 0;
BA_ "GenSigTimeoutTime_BPCM" SG_ 212 PIM_B_Torque_Achieved 0;
BA_ "GenSigStartValue" SG_ 212 PIM_B_Torque_Achieved 4096;
BA_ "GenSigTimeoutTime_PBWM" SG_ 212 PIM_B_TorqAchieved_AEMD_V 0;
BA_ "GenSigTimeoutTime_MCPB" SG_ 212 PIM_B_TorqAchieved_AEMD_V 0;
BA_ "GenSigTimeoutTime_MCPA" SG_ 212 PIM_B_TorqAchieved_AEMD_V 0;
BA_ "GenSigTimeoutTime_IDCM" SG_ 212 PIM_B_TorqAchieved_AEMD_V 0;
BA_ "GenSigTimeoutTime_ECM" SG_ 212 PIM_B_TorqAchieved_AEMD_V 0;
BA_ "GenSigTimeoutTime_DMPI" SG_ 212 PIM_B_TorqAchieved_AEMD_V 0;
BA_ "GenSigTimeoutTime_BPCM" SG_ 212 PIM_B_TorqAchieved_AEMD_V 0;
BA_ "GenSigTimeoutTime_PBWM" SG_ 212 PIM_B_RPM_V 0;
BA_ "GenSigTimeoutTime_MCPB" SG_ 212 PIM_B_RPM_V 0;
BA_ "GenSigTimeoutTime_MCPA" SG_ 212 PIM_B_RPM_V 0;
BA_ "GenSigTimeoutTime_IDCM" SG_ 212 PIM_B_RPM_V 0;
BA_ "GenSigTimeoutTime_ECM" SG_ 212 PIM_B_RPM_V 0;
BA_ "GenSigTimeoutTime_DMPI" SG_ 212 PIM_B_RPM_V 0;
BA_ "GenSigTimeoutTime_BPCM" SG_ 212 PIM_B_RPM_V 0;
BA_ "GenSigTimeoutTime_PBWM" SG_ 212 PIM_B_Spd_Lim 0;
BA_ "GenSigTimeoutTime_MCPB" SG_ 212 PIM_B_Spd_Lim 0;
BA_ "GenSigTimeoutTime_MCPA" SG_ 212 PIM_B_Spd_Lim 0;
BA_ "GenSigTimeoutTime_IDCM" SG_ 212 PIM_B_Spd_Lim 0;
BA_ "GenSigTimeoutTime_ECM" SG_ 212 PIM_B_Spd_Lim 0;
BA_ "GenSigTimeoutTime_DMPI" SG_ 212 PIM_B_Spd_Lim 0;
BA_ "GenSigTimeoutTime_BPCM" SG_ 212 PIM_B_Spd_Lim 0;
BA_ "GenSigTimeoutTime_PBWM" SG_ 212 PIM_B_SPT_Stat 0;
BA_ "GenSigTimeoutTime_MCPB" SG_ 212 PIM_B_SPT_Stat 0;
BA_ "GenSigTimeoutTime_MCPA" SG_ 212 PIM_B_SPT_Stat 0;
BA_ "GenSigTimeoutTime_IDCM" SG_ 212 PIM_B_SPT_Stat 0;
BA_ "GenSigTimeoutTime_ECM" SG_ 212 PIM_B_SPT_Stat 0;
BA_ "GenSigTimeoutTime_DMPI" SG_ 212 PIM_B_SPT_Stat 0;
BA_ "GenSigTimeoutTime_BPCM" SG_ 212 PIM_B_SPT_Stat 0;
BA_ "GenSigTimeoutTime_PBWM" SG_ 212 PIM_B_TorqAchieved_AEMD 0;
BA_ "GenSigTimeoutTime_MCPB" SG_ 212 PIM_B_TorqAchieved_AEMD 0;
BA_ "GenSigTimeoutTime_MCPA" SG_ 212 PIM_B_TorqAchieved_AEMD 0;
BA_ "GenSigTimeoutTime_IDCM" SG_ 212 PIM_B_TorqAchieved_AEMD 0;
BA_ "GenSigTimeoutTime_ECM" SG_ 212 PIM_B_TorqAchieved_AEMD 0;
BA_ "GenSigTimeoutTime_DMPI" SG_ 212 PIM_B_TorqAchieved_AEMD 0;
BA_ "GenSigTimeoutTime_BPCM" SG_ 212 PIM_B_TorqAchieved_AEMD 0;
BA_ "GenSigStartValue" SG_ 212 PIM_B_TorqAchieved_AEMD 4096;
BA_ "GenSigTimeoutTime_PBWM" SG_ 212 MAC_PIM_B 0;
BA_ "GenSigTimeoutTime_MCPB" SG_ 212 MAC_PIM_B 0;
BA_ "GenSigTimeoutTime_MCPA" SG_ 212 MAC_PIM_B 0;
BA_ "GenSigTimeoutTime_IDCM" SG_ 212 MAC_PIM_B 0;
BA_ "GenSigTimeoutTime_ECM" SG_ 212 MAC_PIM_B 0;
BA_ "GenSigTimeoutTime_DMPI" SG_ 212 MAC_PIM_B 0;
BA_ "GenSigTimeoutTime_BPCM" SG_ 212 MAC_PIM_B 0;
BA_ "GenSigTimeoutTime_PBWM" SG_ 212 MC_PIM_B 0;
BA_ "GenSigTimeoutTime_MCPB" SG_ 212 MC_PIM_B 0;
BA_ "GenSigTimeoutTime_MCPA" SG_ 212 MC_PIM_B 0;
BA_ "GenSigTimeoutTime_IDCM" SG_ 212 MC_PIM_B 0;
BA_ "GenSigTimeoutTime_ECM" SG_ 212 MC_PIM_B 0;
BA_ "GenSigTimeoutTime_DMPI" SG_ 212 MC_PIM_B 0;
BA_ "GenSigTimeoutTime_BPCM" SG_ 212 MC_PIM_B 0;
BA_ "GenSigTimeoutTime_PBWM" SG_ 212 PIM_B_3PS_Pos 0;
BA_ "GenSigTimeoutTime_MCPB" SG_ 212 PIM_B_3PS_Pos 0;
BA_ "GenSigTimeoutTime_MCPA" SG_ 212 PIM_B_3PS_Pos 0;
BA_ "GenSigTimeoutTime_IDCM" SG_ 212 PIM_B_3PS_Pos 0;
BA_ "GenSigTimeoutTime_ECM" SG_ 212 PIM_B_3PS_Pos 0;
BA_ "GenSigTimeoutTime_DMPI" SG_ 212 PIM_B_3PS_Pos 0;
BA_ "GenSigTimeoutTime_BPCM" SG_ 212 PIM_B_3PS_Pos 0;
BA_ "GenSigTimeoutTime_PBWM" SG_ 212 PIM_B_6SO_Status 0;
BA_ "GenSigTimeoutTime_MCPB" SG_ 212 PIM_B_6SO_Status 0;
BA_ "GenSigTimeoutTime_MCPA" SG_ 212 PIM_B_6SO_Status 0;
BA_ "GenSigTimeoutTime_IDCM" SG_ 212 PIM_B_6SO_Status 0;
BA_ "GenSigTimeoutTime_ECM" SG_ 212 PIM_B_6SO_Status 0;
BA_ "GenSigTimeoutTime_DMPI" SG_ 212 PIM_B_6SO_Status 0;
BA_ "GenSigTimeoutTime_BPCM" SG_ 212 PIM_B_6SO_Status 0;
BA_ "GenSigTimeoutTime_PBWM" SG_ 212 PIM_B_AccelRawV 0;
BA_ "GenSigTimeoutTime_MCPB" SG_ 212 PIM_B_AccelRawV 0;
BA_ "GenSigTimeoutTime_MCPA" SG_ 212 PIM_B_AccelRawV 0;
BA_ "GenSigTimeoutTime_IDCM" SG_ 212 PIM_B_AccelRawV 0;
BA_ "GenSigTimeoutTime_ECM" SG_ 212 PIM_B_AccelRawV 0;
BA_ "GenSigTimeoutTime_DMPI" SG_ 212 PIM_B_AccelRawV 0;
BA_ "GenSigTimeoutTime_BPCM" SG_ 212 PIM_B_AccelRawV 0;
BA_ "GenSigTimeoutTime_PBWM" SG_ 212 PIM_B_CoolantTemp 0;
BA_ "GenSigTimeoutTime_MCPB" SG_ 212 PIM_B_CoolantTemp 0;
BA_ "GenSigTimeoutTime_MCPA" SG_ 212 PIM_B_CoolantTemp 0;
BA_ "GenSigTimeoutTime_IDCM" SG_ 212 PIM_B_CoolantTemp 0;
BA_ "GenSigTimeoutTime_ECM" SG_ 212 PIM_B_CoolantTemp 0;
BA_ "GenSigTimeoutTime_DMPI" SG_ 212 PIM_B_CoolantTemp 0;
BA_ "GenSigTimeoutTime_BPCM" SG_ 212 PIM_B_CoolantTemp 0;
BA_ "GenSigTimeoutTime_PBWM" SG_ 212 PIM_B_CpbltySpdDivVolt 0;
BA_ "GenSigTimeoutTime_MCPB" SG_ 212 PIM_B_CpbltySpdDivVolt 0;
BA_ "GenSigTimeoutTime_MCPA" SG_ 212 PIM_B_CpbltySpdDivVolt 0;
BA_ "GenSigTimeoutTime_IDCM" SG_ 212 PIM_B_CpbltySpdDivVolt 0;
BA_ "GenSigTimeoutTime_ECM" SG_ 212 PIM_B_CpbltySpdDivVolt 0;
BA_ "GenSigTimeoutTime_DMPI" SG_ 212 PIM_B_CpbltySpdDivVolt 0;
BA_ "GenSigTimeoutTime_BPCM" SG_ 212 PIM_B_CpbltySpdDivVolt 0;
BA_ "GenSigTimeoutTime_PBWM" SG_ 212 PIM_B_DC_Current 0;
BA_ "GenSigTimeoutTime_MCPB" SG_ 212 PIM_B_DC_Current 0;
BA_ "GenSigTimeoutTime_MCPA" SG_ 212 PIM_B_DC_Current 0;
BA_ "GenSigTimeoutTime_IDCM" SG_ 212 PIM_B_DC_Current 0;
BA_ "GenSigTimeoutTime_ECM" SG_ 212 PIM_B_DC_Current 0;
BA_ "GenSigTimeoutTime_DMPI" SG_ 212 PIM_B_DC_Current 0;
BA_ "GenSigStartValue" SG_ 212 PIM_B_DC_Current 16384;
BA_ "GenSigTimeoutTime_PBWM" SG_ 212 PIM_B_DC_Current_V 0;
BA_ "GenSigTimeoutTime_MCPB" SG_ 212 PIM_B_DC_Current_V 0;
BA_ "GenSigTimeoutTime_MCPA" SG_ 212 PIM_B_DC_Current_V 0;
BA_ "GenSigTimeoutTime_IDCM" SG_ 212 PIM_B_DC_Current_V 0;
BA_ "GenSigTimeoutTime_ECM" SG_ 212 PIM_B_DC_Current_V 0;
BA_ "GenSigTimeoutTime_DMPI" SG_ 212 PIM_B_DC_Current_V 0;
BA_ "GenSigTimeoutTime_BPCM" SG_ 212 PIM_B_DC_Current_V 0;
BA_ "GenSigTimeoutTime_PBWM" SG_ 212 PIM_B_DC_Volt_V 0;
BA_ "GenSigTimeoutTime_MCPB" SG_ 212 PIM_B_DC_Volt_V 0;
BA_ "GenSigTimeoutTime_MCPA" SG_ 212 PIM_B_DC_Volt_V 0;
BA_ "GenSigTimeoutTime_IDCM" SG_ 212 PIM_B_DC_Volt_V 0;
BA_ "GenSigTimeoutTime_ECM" SG_ 212 PIM_B_DC_Volt_V 0;
BA_ "GenSigTimeoutTime_DMPI" SG_ 212 PIM_B_DC_Volt_V 0;
BA_ "GenSigTimeoutTime_BPCM" SG_ 212 PIM_B_DC_Volt_V 0;
BA_ "GenSigTimeoutTime_PBWM" SG_ 212 PIM_B_DC_Voltage 0;
BA_ "GenSigTimeoutTime_MCPB" SG_ 212 PIM_B_DC_Voltage 0;
BA_ "GenSigTimeoutTime_MCPA" SG_ 212 PIM_B_DC_Voltage 0;
BA_ "GenSigTimeoutTime_IDCM" SG_ 212 PIM_B_DC_Voltage 0;
BA_ "GenSigTimeoutTime_ECM" SG_ 212 PIM_B_DC_Voltage 0;
BA_ "GenSigTimeoutTime_DMPI" SG_ 212 PIM_B_DC_Voltage 0;
BA_ "GenSigTimeoutTime_BPCM" SG_ 212 PIM_B_DC_Voltage 0;
BA_ "GenSigTimeoutTime_PBWM" SG_ 212 PIM_B_DerateReason 0;
BA_ "GenSigTimeoutTime_MCPB" SG_ 212 PIM_B_DerateReason 0;
BA_ "GenSigTimeoutTime_MCPA" SG_ 212 PIM_B_DerateReason 0;
BA_ "GenSigTimeoutTime_IDCM" SG_ 212 PIM_B_DerateReason 0;
BA_ "GenSigTimeoutTime_ECM" SG_ 212 PIM_B_DerateReason 0;
BA_ "GenSigTimeoutTime_DMPI" SG_ 212 PIM_B_DerateReason 0;
BA_ "GenSigTimeoutTime_BPCM" SG_ 212 PIM_B_DerateReason 0;
BA_ "GenSigTimeoutTime_PBWM" SG_ 212 PIM_B_DeratingFactor 0;
BA_ "GenSigTimeoutTime_MCPB" SG_ 212 PIM_B_DeratingFactor 0;
BA_ "GenSigTimeoutTime_MCPA" SG_ 212 PIM_B_DeratingFactor 0;
BA_ "GenSigTimeoutTime_IDCM" SG_ 212 PIM_B_DeratingFactor 0;
BA_ "GenSigTimeoutTime_ECM" SG_ 212 PIM_B_DeratingFactor 0;
BA_ "GenSigTimeoutTime_DMPI" SG_ 212 PIM_B_DeratingFactor 0;
BA_ "GenSigTimeoutTime_BPCM" SG_ 212 PIM_B_DeratingFactor 0;
BA_ "GenSigTimeoutTime_PBWM" SG_ 212 PIM_B_Dschrge_Status 0;
BA_ "GenSigTimeoutTime_MCPB" SG_ 212 PIM_B_Dschrge_Status 0;
BA_ "GenSigTimeoutTime_MCPA" SG_ 212 PIM_B_Dschrge_Status 0;
BA_ "GenSigTimeoutTime_IDCM" SG_ 212 PIM_B_Dschrge_Status 0;
BA_ "GenSigTimeoutTime_ECM" SG_ 212 PIM_B_Dschrge_Status 0;
BA_ "GenSigTimeoutTime_DMPI" SG_ 212 PIM_B_Dschrge_Status 0;
BA_ "GenSigTimeoutTime_BPCM" SG_ 212 PIM_B_Dschrge_Status 0;
BA_ "GenSigTimeoutTime_PBWM" SG_ 212 PIM_B_HV_CnctrOpn_Req 0;
BA_ "GenSigTimeoutTime_MCPB" SG_ 212 PIM_B_HV_CnctrOpn_Req 0;
BA_ "GenSigTimeoutTime_MCPA" SG_ 212 PIM_B_HV_CnctrOpn_Req 0;
BA_ "GenSigTimeoutTime_IDCM" SG_ 212 PIM_B_HV_CnctrOpn_Req 0;
BA_ "GenSigTimeoutTime_ECM" SG_ 212 PIM_B_HV_CnctrOpn_Req 0;
BA_ "GenSigTimeoutTime_DMPI" SG_ 212 PIM_B_HV_CnctrOpn_Req 0;
BA_ "GenSigTimeoutTime_BPCM" SG_ 212 PIM_B_HV_CnctrOpn_Req 0;
BA_ "GenSigTimeoutTime_PBWM" SG_ 212 PIM_B_InterlockSts 0;
BA_ "GenSigTimeoutTime_MCPB" SG_ 212 PIM_B_InterlockSts 0;
BA_ "GenSigTimeoutTime_MCPA" SG_ 212 PIM_B_InterlockSts 0;
BA_ "GenSigTimeoutTime_IDCM" SG_ 212 PIM_B_InterlockSts 0;
BA_ "GenSigTimeoutTime_ECM" SG_ 212 PIM_B_InterlockSts 0;
BA_ "GenSigTimeoutTime_DMPI" SG_ 212 PIM_B_InterlockSts 0;
BA_ "GenSigTimeoutTime_BPCM" SG_ 212 PIM_B_InterlockSts 0;
BA_ "GenSigTimeoutTime_PBWM" SG_ 212 PIM_B_Invrtr_State 0;
BA_ "GenSigTimeoutTime_MCPB" SG_ 212 PIM_B_Invrtr_State 0;
BA_ "GenSigTimeoutTime_MCPA" SG_ 212 PIM_B_Invrtr_State 0;
BA_ "GenSigTimeoutTime_IDCM" SG_ 212 PIM_B_Invrtr_State 0;
BA_ "GenSigTimeoutTime_ECM" SG_ 212 PIM_B_Invrtr_State 0;
BA_ "GenSigTimeoutTime_DMPI" SG_ 212 PIM_B_Invrtr_State 0;
BA_ "GenSigTimeoutTime_BPCM" SG_ 212 PIM_B_Invrtr_State 0;
BA_ "GenSigTimeoutTime_PBWM" SG_ 212 PIM_B_MaxTorq 0;
BA_ "GenSigTimeoutTime_MCPB" SG_ 212 PIM_B_MaxTorq 0;
BA_ "GenSigTimeoutTime_MCPA" SG_ 212 PIM_B_MaxTorq 0;
BA_ "GenSigTimeoutTime_IDCM" SG_ 212 PIM_B_MaxTorq 0;
BA_ "GenSigTimeoutTime_ECM" SG_ 212 PIM_B_MaxTorq 0;
BA_ "GenSigTimeoutTime_DMPI" SG_ 212 PIM_B_MaxTorq 0;
BA_ "GenSigTimeoutTime_BPCM" SG_ 212 PIM_B_MaxTorq 0;
BA_ "GenSigStartValue" SG_ 212 PIM_B_MaxTorq 4096;
BA_ "GenSigTimeoutTime_PBWM" SG_ 212 PIM_B_MinTorq 0;
BA_ "GenSigTimeoutTime_MCPB" SG_ 212 PIM_B_MinTorq 0;
BA_ "GenSigTimeoutTime_MCPA" SG_ 212 PIM_B_MinTorq 0;
BA_ "GenSigTimeoutTime_IDCM" SG_ 212 PIM_B_MinTorq 0;
BA_ "GenSigTimeoutTime_ECM" SG_ 212 PIM_B_MinTorq 0;
BA_ "GenSigTimeoutTime_DMPI" SG_ 212 PIM_B_MinTorq 0;
BA_ "GenSigTimeoutTime_BPCM" SG_ 212 PIM_B_MinTorq 0;
BA_ "GenSigStartValue" SG_ 212 PIM_B_MinTorq 4096;
BA_ "GenSigTimeoutTime_PBWM" SG_ 212 PIM_B_MtrIndex 0;
BA_ "GenSigTimeoutTime_MCPB" SG_ 212 PIM_B_MtrIndex 0;
BA_ "GenSigTimeoutTime_MCPA" SG_ 212 PIM_B_MtrIndex 0;
BA_ "GenSigTimeoutTime_IDCM" SG_ 212 PIM_B_MtrIndex 0;
BA_ "GenSigTimeoutTime_ECM" SG_ 212 PIM_B_MtrIndex 0;
BA_ "GenSigTimeoutTime_DMPI" SG_ 212 PIM_B_MtrIndex 0;
BA_ "GenSigTimeoutTime_BPCM" SG_ 212 PIM_B_MtrIndex 0;
BA_ "GenSigTimeoutTime_PBWM" SG_ 212 PIM_B_MtrMaxCpbltyTrq 0;
BA_ "GenSigTimeoutTime_MCPB" SG_ 212 PIM_B_MtrMaxCpbltyTrq 0;
BA_ "GenSigTimeoutTime_MCPA" SG_ 212 PIM_B_MtrMaxCpbltyTrq 0;
BA_ "GenSigTimeoutTime_IDCM" SG_ 212 PIM_B_MtrMaxCpbltyTrq 0;
BA_ "GenSigTimeoutTime_ECM" SG_ 212 PIM_B_MtrMaxCpbltyTrq 0;
BA_ "GenSigTimeoutTime_DMPI" SG_ 212 PIM_B_MtrMaxCpbltyTrq 0;
BA_ "GenSigTimeoutTime_BPCM" SG_ 212 PIM_B_MtrMaxCpbltyTrq 0;
BA_ "GenSigStartValue" SG_ 212 PIM_B_MtrMaxCpbltyTrq 4096;
BA_ "GenSigTimeoutTime_PBWM" SG_ 212 PIM_B_MtrMinCpbltyTrq 0;
BA_ "GenSigTimeoutTime_MCPB" SG_ 212 PIM_B_MtrMinCpbltyTrq 0;
BA_ "GenSigTimeoutTime_MCPA" SG_ 212 PIM_B_MtrMinCpbltyTrq 0;
BA_ "GenSigTimeoutTime_IDCM" SG_ 212 PIM_B_MtrMinCpbltyTrq 0;
BA_ "GenSigTimeoutTime_ECM" SG_ 212 PIM_B_MtrMinCpbltyTrq 0;
BA_ "GenSigTimeoutTime_DMPI" SG_ 212 PIM_B_MtrMinCpbltyTrq 0;
BA_ "GenSigTimeoutTime_BPCM" SG_ 212 PIM_B_MtrMinCpbltyTrq 0;
BA_ "GenSigStartValue" SG_ 212 PIM_B_MtrMinCpbltyTrq 4096;
BA_ "GenSigTimeoutTime_PBWM" SG_ 212 PIM_B_RPM 0;
BA_ "GenSigTimeoutTime_MCPB" SG_ 212 PIM_B_RPM 0;
BA_ "GenSigTimeoutTime_MCPA" SG_ 212 PIM_B_RPM 0;
BA_ "GenSigTimeoutTime_IDCM" SG_ 212 PIM_B_RPM 0;
BA_ "GenSigTimeoutTime_ECM" SG_ 212 PIM_B_RPM 0;
BA_ "GenSigTimeoutTime_DMPI" SG_ 212 PIM_B_RPM 0;
BA_ "GenSigTimeoutTime_BPCM" SG_ 212 PIM_B_RPM 0;
BA_ "GenSigStartValue" SG_ 212 PIM_B_RPM 32768;
BA_ "GenSigTimeoutTime_PBWM" SG_ 212 PIM_B_AccelRaw 0;
BA_ "GenSigTimeoutTime_MCPB" SG_ 212 PIM_B_AccelRaw 0;
BA_ "GenSigTimeoutTime_MCPA" SG_ 212 PIM_B_AccelRaw 0;
BA_ "GenSigTimeoutTime_IDCM" SG_ 212 PIM_B_AccelRaw 0;
BA_ "GenSigTimeoutTime_ECM" SG_ 212 PIM_B_AccelRaw 0;
BA_ "GenSigTimeoutTime_DMPI" SG_ 212 PIM_B_AccelRaw 0;
BA_ "GenSigTimeoutTime_BPCM" SG_ 212 PIM_B_AccelRaw 0;
BA_ "GenSigStartValue" SG_ 212 PIM_B_AccelRaw 32768;
BA_ "GenSigTimeoutTime_PBWM" SG_ 211 Cntr_PIM_A 0;
BA_ "GenSigTimeoutTime_MCPB" SG_ 211 Cntr_PIM_A 0;
BA_ "GenSigTimeoutTime_MCPA" SG_ 211 Cntr_PIM_A 0;
BA_ "GenSigTimeoutTime_IDCM" SG_ 211 Cntr_PIM_A 0;
BA_ "GenSigTimeoutTime_ECM" SG_ 211 Cntr_PIM_A 0;
BA_ "GenSigTimeoutTime_DMPI" SG_ 211 Cntr_PIM_A 0;
BA_ "GenSigTimeoutTime_BPCM" SG_ 211 Cntr_PIM_A 0;
BA_ "GenSigTimeoutTime_PBWM" SG_ 211 CRC_PIM_A 0;
BA_ "GenSigTimeoutTime_MCPB" SG_ 211 CRC_PIM_A 0;
BA_ "GenSigTimeoutTime_MCPA" SG_ 211 CRC_PIM_A 0;
BA_ "GenSigTimeoutTime_IDCM" SG_ 211 CRC_PIM_A 0;
BA_ "GenSigTimeoutTime_ECM" SG_ 211 CRC_PIM_A 0;
BA_ "GenSigTimeoutTime_DMPI" SG_ 211 CRC_PIM_A 0;
BA_ "GenSigTimeoutTime_BPCM" SG_ 211 CRC_PIM_A 0;
BA_ "GenSigTimeoutTime_PBWM" SG_ 211 MAC_PIM_A 0;
BA_ "GenSigTimeoutTime_MCPB" SG_ 211 MAC_PIM_A 0;
BA_ "GenSigTimeoutTime_MCPA" SG_ 211 MAC_PIM_A 0;
BA_ "GenSigTimeoutTime_IDCM" SG_ 211 MAC_PIM_A 0;
BA_ "GenSigTimeoutTime_ECM" SG_ 211 MAC_PIM_A 0;
BA_ "GenSigTimeoutTime_DMPI" SG_ 211 MAC_PIM_A 0;
BA_ "GenSigTimeoutTime_BPCM" SG_ 211 MAC_PIM_A 0;
BA_ "GenSigTimeoutTime_PBWM" SG_ 211 MC_PIM_A 0;
BA_ "GenSigTimeoutTime_MCPB" SG_ 211 MC_PIM_A 0;
BA_ "GenSigTimeoutTime_MCPA" SG_ 211 MC_PIM_A 0;
BA_ "GenSigTimeoutTime_IDCM" SG_ 211 MC_PIM_A 0;
BA_ "GenSigTimeoutTime_ECM" SG_ 211 MC_PIM_A 0;
BA_ "GenSigTimeoutTime_DMPI" SG_ 211 MC_PIM_A 0;
BA_ "GenSigTimeoutTime_BPCM" SG_ 211 MC_PIM_A 0;
BA_ "GenSigTimeoutTime_PBWM" SG_ 211 PIM_A_3PS_Pos 0;
BA_ "GenSigTimeoutTime_MCPB" SG_ 211 PIM_A_3PS_Pos 0;
BA_ "GenSigTimeoutTime_MCPA" SG_ 211 PIM_A_3PS_Pos 0;
BA_ "GenSigTimeoutTime_IDCM" SG_ 211 PIM_A_3PS_Pos 0;
BA_ "GenSigTimeoutTime_ECM" SG_ 211 PIM_A_3PS_Pos 0;
BA_ "GenSigTimeoutTime_DMPI" SG_ 211 PIM_A_3PS_Pos 0;
BA_ "GenSigTimeoutTime_BPCM" SG_ 211 PIM_A_3PS_Pos 0;
BA_ "GenSigTimeoutTime_PBWM" SG_ 2654339161 DES_FD16_MCPB 0;
BA_ "GenSigTimeoutTime_MCPB" SG_ 2654339161 DES_FD16_MCPB 0;
BA_ "GenSigTimeoutTime_MCPA" SG_ 2654339161 DES_FD16_MCPB 0;
BA_ "GenSigTimeoutTime_IDCM" SG_ 2654339161 DES_FD16_MCPB 0;
BA_ "GenSigTimeoutTime_ECM" SG_ 2654339161 DES_FD16_MCPB 0;
BA_ "GenSigTimeoutTime_DMPI" SG_ 2654339161 DES_FD16_MCPB 0;
BA_ "GenSigTimeoutTime_BPCM" SG_ 2654339161 DES_FD16_MCPB 0;
BA_ "GenSigTimeoutTime_PBWM" SG_ 2654339161 GenericFailSts_FD16_MCPB 0;
BA_ "GenSigTimeoutTime_MCPB" SG_ 2654339161 GenericFailSts_FD16_MCPB 0;
BA_ "GenSigTimeoutTime_MCPA" SG_ 2654339161 GenericFailSts_FD16_MCPB 0;
BA_ "GenSigTimeoutTime_IDCM" SG_ 2654339161 GenericFailSts_FD16_MCPB 0;
BA_ "GenSigTimeoutTime_ECM" SG_ 2654339161 GenericFailSts_FD16_MCPB 0;
BA_ "GenSigTimeoutTime_DMPI" SG_ 2654339161 GenericFailSts_FD16_MCPB 0;
BA_ "GenSigTimeoutTime_BPCM" SG_ 2654339161 GenericFailSts_FD16_MCPB 0;
BA_ "GenSigTimeoutTime_PBWM" SG_ 2654339160 GenericFailSts_FD16_MCPA 0;
BA_ "GenSigTimeoutTime_MCPB" SG_ 2654339160 GenericFailSts_FD16_MCPA 0;
BA_ "GenSigTimeoutTime_MCPA" SG_ 2654339160 GenericFailSts_FD16_MCPA 0;
BA_ "GenSigTimeoutTime_IDCM" SG_ 2654339160 GenericFailSts_FD16_MCPA 0;
BA_ "GenSigTimeoutTime_ECM" SG_ 2654339160 GenericFailSts_FD16_MCPA 0;
BA_ "GenSigTimeoutTime_DMPI" SG_ 2654339160 GenericFailSts_FD16_MCPA 0;
BA_ "GenSigTimeoutTime_BPCM" SG_ 2654339160 GenericFailSts_FD16_MCPA 0;
BA_ "GenSigTimeoutTime_PBWM" SG_ 2654339161 CurrentFailSts_FD16_MCPB 0;
BA_ "GenSigTimeoutTime_MCPB" SG_ 2654339161 CurrentFailSts_FD16_MCPB 0;
BA_ "GenSigTimeoutTime_MCPA" SG_ 2654339161 CurrentFailSts_FD16_MCPB 0;
BA_ "GenSigTimeoutTime_IDCM" SG_ 2654339161 CurrentFailSts_FD16_MCPB 0;
BA_ "GenSigTimeoutTime_ECM" SG_ 2654339161 CurrentFailSts_FD16_MCPB 0;
BA_ "GenSigTimeoutTime_DMPI" SG_ 2654339161 CurrentFailSts_FD16_MCPB 0;
BA_ "GenSigTimeoutTime_BPCM" SG_ 2654339161 CurrentFailSts_FD16_MCPB 0;
BA_ "GenSigTimeoutTime_PBWM" SG_ 2654339160 EOL_FD16_MCPA 0;
BA_ "GenSigTimeoutTime_MCPB" SG_ 2654339160 EOL_FD16_MCPA 0;
BA_ "GenSigTimeoutTime_MCPA" SG_ 2654339160 EOL_FD16_MCPA 0;
BA_ "GenSigTimeoutTime_PBWM" SG_ 2654339160 GenericFailSts_FD05_MCPA 0;
BA_ "GenSigTimeoutTime_MCPB" SG_ 2654339160 GenericFailSts_FD05_MCPA 0;
BA_ "GenSigTimeoutTime_MCPA" SG_ 2654339160 GenericFailSts_FD05_MCPA 0;
BA_ "GenSigTimeoutTime_IDCM" SG_ 2654339160 GenericFailSts_FD05_MCPA 0;
BA_ "GenSigTimeoutTime_ECM" SG_ 2654339160 GenericFailSts_FD05_MCPA 0;
BA_ "GenSigTimeoutTime_DMPI" SG_ 2654339160 GenericFailSts_FD05_MCPA 0;
BA_ "GenSigTimeoutTime_BPCM" SG_ 2654339160 GenericFailSts_FD05_MCPA 0;
BA_ "GenSigTimeoutTime_PBWM" SG_ 2654339160 PreviousCanNMState_FD05_MCPA 0;
BA_ "GenSigTimeoutTime_MCPB" SG_ 2654339160 PreviousCanNMState_FD05_MCPA 0;
BA_ "GenSigTimeoutTime_MCPA" SG_ 2654339160 PreviousCanNMState_FD05_MCPA 0;
BA_ "GenSigTimeoutTime_IDCM" SG_ 2654339160 PreviousCanNMState_FD05_MCPA 0;
BA_ "GenSigTimeoutTime_ECM" SG_ 2654339160 PreviousCanNMState_FD05_MCPA 0;
BA_ "GenSigTimeoutTime_DMPI" SG_ 2654339160 PreviousCanNMState_FD05_MCPA 0;
BA_ "GenSigTimeoutTime_BPCM" SG_ 2654339160 PreviousCanNMState_FD05_MCPA 0;
BA_ "GenSigTimeoutTime_IDCM" SG_ 2654339160 PreviousCanNMState_FD16_MCPA 0;
BA_ "GenSigTimeoutTime_ECM" SG_ 2654339160 PreviousCanNMState_FD16_MCPA 0;
BA_ "GenSigTimeoutTime_DMPI" SG_ 2654339160 PreviousCanNMState_FD16_MCPA 0;
BA_ "GenSigTimeoutTime_BPCM" SG_ 2654339160 PreviousCanNMState_FD16_MCPA 0;
BA_ "GenSigTimeoutTime_PBWM" SG_ 2654339160 PreviousCanNMState_FD16_MCPA 0;
BA_ "GenSigTimeoutTime_MCPB" SG_ 2654339160 PreviousCanNMState_FD16_MCPA 0;
BA_ "GenSigTimeoutTime_MCPA" SG_ 2654339160 PreviousCanNMState_FD16_MCPA 0;
BA_ "GenSigTimeoutTime_PBWM" SG_ 2654339160 StayActiveSource_FD05_MCPA 0;
BA_ "GenSigTimeoutTime_MCPB" SG_ 2654339160 StayActiveSource_FD05_MCPA 0;
BA_ "GenSigTimeoutTime_MCPA" SG_ 2654339160 StayActiveSource_FD05_MCPA 0;
BA_ "GenSigTimeoutTime_IDCM" SG_ 2654339160 StayActiveSource_FD05_MCPA 0;
BA_ "GenSigTimeoutTime_ECM" SG_ 2654339160 StayActiveSource_FD05_MCPA 0;
BA_ "GenSigTimeoutTime_DMPI" SG_ 2654339160 StayActiveSource_FD05_MCPA 0;
BA_ "GenSigTimeoutTime_BPCM" SG_ 2654339160 StayActiveSource_FD05_MCPA 0;
BA_ "GenSigTimeoutTime_PBWM" SG_ 2654339160 StayActiveSource_FD16_MCPA 0;
BA_ "GenSigTimeoutTime_MCPB" SG_ 2654339160 StayActiveSource_FD16_MCPA 0;
BA_ "GenSigTimeoutTime_MCPA" SG_ 2654339160 StayActiveSource_FD16_MCPA 0;
BA_ "GenSigTimeoutTime_IDCM" SG_ 2654339160 StayActiveSource_FD16_MCPA 0;
BA_ "GenSigTimeoutTime_ECM" SG_ 2654339160 StayActiveSource_FD16_MCPA 0;
BA_ "GenSigTimeoutTime_DMPI" SG_ 2654339160 StayActiveSource_FD16_MCPA 0;
BA_ "GenSigTimeoutTime_BPCM" SG_ 2654339160 StayActiveSource_FD16_MCPA 0;
BA_ "GenSigTimeoutTime_PBWM" SG_ 2654339160 WakeupSource_FD05_MCPA 0;
BA_ "GenSigTimeoutTime_MCPB" SG_ 2654339160 WakeupSource_FD05_MCPA 0;
BA_ "GenSigTimeoutTime_MCPA" SG_ 2654339160 WakeupSource_FD05_MCPA 0;
BA_ "GenSigTimeoutTime_IDCM" SG_ 2654339160 WakeupSource_FD05_MCPA 0;
BA_ "GenSigTimeoutTime_ECM" SG_ 2654339160 WakeupSource_FD05_MCPA 0;
BA_ "GenSigTimeoutTime_DMPI" SG_ 2654339160 WakeupSource_FD05_MCPA 0;
BA_ "GenSigTimeoutTime_BPCM" SG_ 2654339160 WakeupSource_FD05_MCPA 0;
BA_ "GenSigTimeoutTime_PBWM" SG_ 2654339160 WakeupSource_FD16_MCPA 0;
BA_ "GenSigTimeoutTime_MCPB" SG_ 2654339160 WakeupSource_FD16_MCPA 0;
BA_ "GenSigTimeoutTime_MCPA" SG_ 2654339160 WakeupSource_FD16_MCPA 0;
BA_ "GenSigTimeoutTime_IDCM" SG_ 2654339160 WakeupSource_FD16_MCPA 0;
BA_ "GenSigTimeoutTime_ECM" SG_ 2654339160 WakeupSource_FD16_MCPA 0;
BA_ "GenSigTimeoutTime_DMPI" SG_ 2654339160 WakeupSource_FD16_MCPA 0;
BA_ "GenSigTimeoutTime_BPCM" SG_ 2654339160 WakeupSource_FD16_MCPA 0;
BA_ "GenSigTimeoutTime_PBWM" SG_ 2654339161 CurrentCanNMState_FD05_MCPB 0;
BA_ "GenSigTimeoutTime_MCPB" SG_ 2654339161 CurrentCanNMState_FD05_MCPB 0;
BA_ "GenSigTimeoutTime_MCPA" SG_ 2654339161 CurrentCanNMState_FD05_MCPB 0;
BA_ "GenSigTimeoutTime_IDCM" SG_ 2654339161 CurrentCanNMState_FD05_MCPB 0;
BA_ "GenSigTimeoutTime_ECM" SG_ 2654339161 CurrentCanNMState_FD05_MCPB 0;
BA_ "GenSigTimeoutTime_DMPI" SG_ 2654339161 CurrentCanNMState_FD05_MCPB 0;
BA_ "GenSigTimeoutTime_BPCM" SG_ 2654339161 CurrentCanNMState_FD05_MCPB 0;
BA_ "GenSigTimeoutTime_PBWM" SG_ 2654339161 CurrentCanNMState_FD16_MCPB 0;
BA_ "GenSigTimeoutTime_MCPB" SG_ 2654339161 CurrentCanNMState_FD16_MCPB 0;
BA_ "GenSigTimeoutTime_MCPA" SG_ 2654339161 CurrentCanNMState_FD16_MCPB 0;
BA_ "GenSigTimeoutTime_IDCM" SG_ 2654339161 CurrentCanNMState_FD16_MCPB 0;
BA_ "GenSigTimeoutTime_ECM" SG_ 2654339161 CurrentCanNMState_FD16_MCPB 0;
BA_ "GenSigTimeoutTime_DMPI" SG_ 2654339161 CurrentCanNMState_FD16_MCPB 0;
BA_ "GenSigTimeoutTime_BPCM" SG_ 2654339161 CurrentCanNMState_FD16_MCPB 0;
BA_ "GenSigTimeoutTime_PBWM" SG_ 2654339161 CurrentFailSts_FD05_MCPB 0;
BA_ "GenSigTimeoutTime_MCPB" SG_ 2654339161 CurrentFailSts_FD05_MCPB 0;
BA_ "GenSigTimeoutTime_MCPA" SG_ 2654339161 CurrentFailSts_FD05_MCPB 0;
BA_ "GenSigTimeoutTime_IDCM" SG_ 2654339161 CurrentFailSts_FD05_MCPB 0;
BA_ "GenSigTimeoutTime_ECM" SG_ 2654339161 CurrentFailSts_FD05_MCPB 0;
BA_ "GenSigTimeoutTime_DMPI" SG_ 2654339161 CurrentFailSts_FD05_MCPB 0;
BA_ "GenSigTimeoutTime_BPCM" SG_ 2654339161 CurrentFailSts_FD05_MCPB 0;
BA_ "GenSigTimeoutTime_PBWM" SG_ 2654339161 DES_FD05_MCPB 0;
BA_ "GenSigTimeoutTime_MCPB" SG_ 2654339161 DES_FD05_MCPB 0;
BA_ "GenSigTimeoutTime_MCPA" SG_ 2654339161 DES_FD05_MCPB 0;
BA_ "GenSigTimeoutTime_IDCM" SG_ 2654339161 DES_FD05_MCPB 0;
BA_ "GenSigTimeoutTime_ECM" SG_ 2654339161 DES_FD05_MCPB 0;
BA_ "GenSigTimeoutTime_DMPI" SG_ 2654339161 DES_FD05_MCPB 0;
BA_ "GenSigTimeoutTime_BPCM" SG_ 2654339161 DES_FD05_MCPB 0;
BA_ "GenSigTimeoutTime_PBWM" SG_ 2654339161 EOL_FD05_MCPB 0;
BA_ "GenSigTimeoutTime_MCPB" SG_ 2654339161 EOL_FD05_MCPB 0;
BA_ "GenSigTimeoutTime_MCPA" SG_ 2654339161 EOL_FD05_MCPB 0;
BA_ "GenSigTimeoutTime_IDCM" SG_ 2654339161 EOL_FD05_MCPB 0;
BA_ "GenSigTimeoutTime_ECM" SG_ 2654339161 EOL_FD05_MCPB 0;
BA_ "GenSigTimeoutTime_DMPI" SG_ 2654339161 EOL_FD05_MCPB 0;
BA_ "GenSigTimeoutTime_BPCM" SG_ 2654339161 EOL_FD05_MCPB 0;
BA_ "GenSigTimeoutTime_PBWM" SG_ 2654339161 EOL_FD16_MCPB 0;
BA_ "GenSigTimeoutTime_MCPB" SG_ 2654339161 EOL_FD16_MCPB 0;
BA_ "GenSigTimeoutTime_MCPA" SG_ 2654339161 EOL_FD16_MCPB 0;
BA_ "GenSigTimeoutTime_IDCM" SG_ 2654339161 EOL_FD16_MCPB 0;
BA_ "GenSigTimeoutTime_ECM" SG_ 2654339161 EOL_FD16_MCPB 0;
BA_ "GenSigTimeoutTime_DMPI" SG_ 2654339161 EOL_FD16_MCPB 0;
BA_ "GenSigTimeoutTime_BPCM" SG_ 2654339161 EOL_FD16_MCPB 0;
BA_ "GenSigTimeoutTime_PBWM" SG_ 2654339161 GenericFailSts_FD05_MCPB 0;
BA_ "GenSigTimeoutTime_MCPB" SG_ 2654339161 GenericFailSts_FD05_MCPB 0;
BA_ "GenSigTimeoutTime_MCPA" SG_ 2654339161 GenericFailSts_FD05_MCPB 0;
BA_ "GenSigTimeoutTime_IDCM" SG_ 2654339161 GenericFailSts_FD05_MCPB 0;
BA_ "GenSigTimeoutTime_ECM" SG_ 2654339161 GenericFailSts_FD05_MCPB 0;
BA_ "GenSigTimeoutTime_DMPI" SG_ 2654339161 GenericFailSts_FD05_MCPB 0;
BA_ "GenSigTimeoutTime_BPCM" SG_ 2654339161 GenericFailSts_FD05_MCPB 0;
BA_ "GenSigTimeoutTime_PBWM" SG_ 2654339161 PreviousCanNMState_FD05_MCPB 0;
BA_ "GenSigTimeoutTime_MCPB" SG_ 2654339161 PreviousCanNMState_FD05_MCPB 0;
BA_ "GenSigTimeoutTime_MCPA" SG_ 2654339161 PreviousCanNMState_FD05_MCPB 0;
BA_ "GenSigTimeoutTime_IDCM" SG_ 2654339161 PreviousCanNMState_FD05_MCPB 0;
BA_ "GenSigTimeoutTime_ECM" SG_ 2654339161 PreviousCanNMState_FD05_MCPB 0;
BA_ "GenSigTimeoutTime_DMPI" SG_ 2654339161 PreviousCanNMState_FD05_MCPB 0;
BA_ "GenSigTimeoutTime_BPCM" SG_ 2654339161 PreviousCanNMState_FD05_MCPB 0;
BA_ "GenSigTimeoutTime_PBWM" SG_ 2654339161 PreviousCanNMState_FD16_MCPB 0;
BA_ "GenSigTimeoutTime_MCPB" SG_ 2654339161 PreviousCanNMState_FD16_MCPB 0;
BA_ "GenSigTimeoutTime_MCPA" SG_ 2654339161 PreviousCanNMState_FD16_MCPB 0;
BA_ "GenSigTimeoutTime_IDCM" SG_ 2654339161 PreviousCanNMState_FD16_MCPB 0;
BA_ "GenSigTimeoutTime_ECM" SG_ 2654339161 PreviousCanNMState_FD16_MCPB 0;
BA_ "GenSigTimeoutTime_DMPI" SG_ 2654339161 PreviousCanNMState_FD16_MCPB 0;
BA_ "GenSigTimeoutTime_BPCM" SG_ 2654339161 PreviousCanNMState_FD16_MCPB 0;
BA_ "GenSigTimeoutTime_PBWM" SG_ 2654339161 StayActiveSource_FD05_MCPB 0;
BA_ "GenSigTimeoutTime_MCPB" SG_ 2654339161 StayActiveSource_FD05_MCPB 0;
BA_ "GenSigTimeoutTime_MCPA" SG_ 2654339161 StayActiveSource_FD05_MCPB 0;
BA_ "GenSigTimeoutTime_IDCM" SG_ 2654339161 StayActiveSource_FD05_MCPB 0;
BA_ "GenSigTimeoutTime_ECM" SG_ 2654339161 StayActiveSource_FD05_MCPB 0;
BA_ "GenSigTimeoutTime_DMPI" SG_ 2654339161 StayActiveSource_FD05_MCPB 0;
BA_ "GenSigTimeoutTime_BPCM" SG_ 2654339161 StayActiveSource_FD05_MCPB 0;
BA_ "GenSigTimeoutTime_PBWM" SG_ 2654339161 StayActiveSource_FD16_MCPB 0;
BA_ "GenSigTimeoutTime_MCPB" SG_ 2654339161 StayActiveSource_FD16_MCPB 0;
BA_ "GenSigTimeoutTime_MCPA" SG_ 2654339161 StayActiveSource_FD16_MCPB 0;
BA_ "GenSigTimeoutTime_IDCM" SG_ 2654339161 StayActiveSource_FD16_MCPB 0;
BA_ "GenSigTimeoutTime_ECM" SG_ 2654339161 StayActiveSource_FD16_MCPB 0;
BA_ "GenSigTimeoutTime_DMPI" SG_ 2654339161 StayActiveSource_FD16_MCPB 0;
BA_ "GenSigTimeoutTime_BPCM" SG_ 2654339161 StayActiveSource_FD16_MCPB 0;
BA_ "GenSigTimeoutTime_PBWM" SG_ 2654339161 WakeupSource_FD05_MCPB 0;
BA_ "GenSigTimeoutTime_MCPB" SG_ 2654339161 WakeupSource_FD05_MCPB 0;
BA_ "GenSigTimeoutTime_MCPA" SG_ 2654339161 WakeupSource_FD05_MCPB 0;
BA_ "GenSigTimeoutTime_IDCM" SG_ 2654339161 WakeupSource_FD05_MCPB 0;
BA_ "GenSigTimeoutTime_ECM" SG_ 2654339161 WakeupSource_FD05_MCPB 0;
BA_ "GenSigTimeoutTime_DMPI" SG_ 2654339161 WakeupSource_FD05_MCPB 0;
BA_ "GenSigTimeoutTime_BPCM" SG_ 2654339161 WakeupSource_FD05_MCPB 0;
BA_ "GenSigTimeoutTime_PBWM" SG_ 2654339161 WakeupSource_FD16_MCPB 0;
BA_ "GenSigTimeoutTime_MCPB" SG_ 2654339161 WakeupSource_FD16_MCPB 0;
BA_ "GenSigTimeoutTime_MCPA" SG_ 2654339161 WakeupSource_FD16_MCPB 0;
BA_ "GenSigTimeoutTime_IDCM" SG_ 2654339161 WakeupSource_FD16_MCPB 0;
BA_ "GenSigTimeoutTime_ECM" SG_ 2654339161 WakeupSource_FD16_MCPB 0;
BA_ "GenSigTimeoutTime_DMPI" SG_ 2654339161 WakeupSource_FD16_MCPB 0;
BA_ "GenSigTimeoutTime_BPCM" SG_ 2654339161 WakeupSource_FD16_MCPB 0;
BA_ "GenSigTimeoutTime_IDCM" SG_ 2654339160 EOL_FD16_MCPA 0;
BA_ "GenSigTimeoutTime_ECM" SG_ 2654339160 EOL_FD16_MCPA 0;
BA_ "GenSigTimeoutTime_DMPI" SG_ 2654339160 EOL_FD16_MCPA 0;
BA_ "GenSigTimeoutTime_BPCM" SG_ 2654339160 EOL_FD16_MCPA 0;
BA_ "GenSigTimeoutTime_PBWM" SG_ 2654339160 CurrentCanNMState_FD16_MCPA 0;
BA_ "GenSigTimeoutTime_MCPB" SG_ 2654339160 CurrentCanNMState_FD16_MCPA 0;
BA_ "GenSigTimeoutTime_MCPA" SG_ 2654339160 CurrentCanNMState_FD16_MCPA 0;
BA_ "GenSigTimeoutTime_IDCM" SG_ 2654339160 CurrentCanNMState_FD16_MCPA 0;
BA_ "GenSigTimeoutTime_ECM" SG_ 2654339160 CurrentCanNMState_FD16_MCPA 0;
BA_ "GenSigTimeoutTime_DMPI" SG_ 2654339160 CurrentCanNMState_FD16_MCPA 0;
BA_ "GenSigTimeoutTime_BPCM" SG_ 2654339160 CurrentCanNMState_FD16_MCPA 0;
BA_ "GenSigTimeoutTime_PBWM" SG_ 2654339160 CurrentFailSts_FD05_MCPA 0;
BA_ "GenSigTimeoutTime_MCPB" SG_ 2654339160 CurrentFailSts_FD05_MCPA 0;
BA_ "GenSigTimeoutTime_MCPA" SG_ 2654339160 CurrentFailSts_FD05_MCPA 0;
BA_ "GenSigTimeoutTime_IDCM" SG_ 2654339160 CurrentFailSts_FD05_MCPA 0;
BA_ "GenSigTimeoutTime_ECM" SG_ 2654339160 CurrentFailSts_FD05_MCPA 0;
BA_ "GenSigTimeoutTime_DMPI" SG_ 2654339160 CurrentFailSts_FD05_MCPA 0;
BA_ "GenSigTimeoutTime_BPCM" SG_ 2654339160 CurrentFailSts_FD05_MCPA 0;
BA_ "GenSigTimeoutTime_PBWM" SG_ 2654339160 DES_FD05_MCPA 0;
BA_ "GenSigTimeoutTime_MCPB" SG_ 2654339160 DES_FD05_MCPA 0;
BA_ "GenSigTimeoutTime_MCPA" SG_ 2654339160 DES_FD05_MCPA 0;
BA_ "GenSigTimeoutTime_IDCM" SG_ 2654339160 DES_FD05_MCPA 0;
BA_ "GenSigTimeoutTime_ECM" SG_ 2654339160 DES_FD05_MCPA 0;
BA_ "GenSigTimeoutTime_DMPI" SG_ 2654339160 DES_FD05_MCPA 0;
BA_ "GenSigTimeoutTime_BPCM" SG_ 2654339160 DES_FD05_MCPA 0;
BA_ "GenSigTimeoutTime_PBWM" SG_ 2654339160 EOL_FD05_MCPA 0;
BA_ "GenSigTimeoutTime_MCPB" SG_ 2654339160 EOL_FD05_MCPA 0;
BA_ "GenSigTimeoutTime_MCPA" SG_ 2654339160 EOL_FD05_MCPA 0;
BA_ "GenSigTimeoutTime_IDCM" SG_ 2654339160 EOL_FD05_MCPA 0;
BA_ "GenSigTimeoutTime_ECM" SG_ 2654339160 EOL_FD05_MCPA 0;
BA_ "GenSigTimeoutTime_DMPI" SG_ 2654339160 EOL_FD05_MCPA 0;
BA_ "GenSigTimeoutTime_BPCM" SG_ 2654339160 EOL_FD05_MCPA 0;
BA_ "GenSigTimeoutTime_PBWM" SG_ 2654339160 CurrentCanNMState_FD05_MCPA 0;
BA_ "GenSigTimeoutTime_MCPB" SG_ 2654339160 CurrentCanNMState_FD05_MCPA 0;
BA_ "GenSigTimeoutTime_MCPA" SG_ 2654339160 CurrentCanNMState_FD05_MCPA 0;
BA_ "GenSigTimeoutTime_IDCM" SG_ 2654339160 CurrentCanNMState_FD05_MCPA 0;
BA_ "GenSigTimeoutTime_ECM" SG_ 2654339160 CurrentCanNMState_FD05_MCPA 0;
BA_ "GenSigTimeoutTime_DMPI" SG_ 2654339160 CurrentCanNMState_FD05_MCPA 0;
BA_ "GenSigTimeoutTime_BPCM" SG_ 2654339160 CurrentCanNMState_FD05_MCPA 0;
BA_ "GenSigTimeoutTime_PBWM" SG_ 2654339160 CurrentFailSts_FD16_MCPA 0;
BA_ "GenSigTimeoutTime_MCPB" SG_ 2654339160 CurrentFailSts_FD16_MCPA 0;
BA_ "GenSigTimeoutTime_MCPA" SG_ 2654339160 CurrentFailSts_FD16_MCPA 0;
BA_ "GenSigTimeoutTime_IDCM" SG_ 2654339160 CurrentFailSts_FD16_MCPA 0;
BA_ "GenSigTimeoutTime_ECM" SG_ 2654339160 CurrentFailSts_FD16_MCPA 0;
BA_ "GenSigTimeoutTime_DMPI" SG_ 2654339160 CurrentFailSts_FD16_MCPA 0;
BA_ "GenSigTimeoutTime_BPCM" SG_ 2654339160 CurrentFailSts_FD16_MCPA 0;
BA_ "GenSigTimeoutTime_PBWM" SG_ 2654339160 DES_FD16_MCPA 0;
BA_ "GenSigTimeoutTime_MCPB" SG_ 2654339160 DES_FD16_MCPA 0;
BA_ "GenSigTimeoutTime_MCPA" SG_ 2654339160 DES_FD16_MCPA 0;
BA_ "GenSigTimeoutTime_IDCM" SG_ 2654339160 DES_FD16_MCPA 0;
BA_ "GenSigTimeoutTime_ECM" SG_ 2654339160 DES_FD16_MCPA 0;
BA_ "GenSigTimeoutTime_DMPI" SG_ 2654339160 DES_FD16_MCPA 0;
BA_ "GenSigTimeoutTime_BPCM" SG_ 2654339160 DES_FD16_MCPA 0;
BA_ "GenSigTimeoutTime_PBWM" SG_ 215 PCU_Diagnostic_Code 0;
BA_ "GenSigTimeoutTime_MCPB" SG_ 215 PCU_Diagnostic_Code 0;
BA_ "GenSigTimeoutTime_MCPA" SG_ 215 PCU_Diagnostic_Code 0;
BA_ "GenSigTimeoutTime_IDCM" SG_ 215 PCU_Diagnostic_Code 0;
BA_ "GenSigTimeoutTime_ECM" SG_ 215 PCU_Diagnostic_Code 0;
BA_ "GenSigTimeoutTime_DMPI" SG_ 215 PCU_Diagnostic_Code 0;
BA_ "GenSigTimeoutTime_BPCM" SG_ 215 PCU_Diagnostic_Code 0;
BA_ "GenSigTimeoutTime_PBWM" SG_ 215 PCU_DriveReadyCompletion_Status 0;
BA_ "GenSigTimeoutTime_MCPB" SG_ 215 PCU_DriveReadyCompletion_Status 0;
BA_ "GenSigTimeoutTime_MCPA" SG_ 215 PCU_DriveReadyCompletion_Status 0;
BA_ "GenSigTimeoutTime_IDCM" SG_ 215 PCU_DriveReadyCompletion_Status 0;
BA_ "GenSigTimeoutTime_ECM" SG_ 215 PCU_DriveReadyCompletion_Status 0;
BA_ "GenSigTimeoutTime_DMPI" SG_ 215 PCU_DriveReadyCompletion_Status 0;
BA_ "GenSigTimeoutTime_BPCM" SG_ 215 PCU_DriveReadyCompletion_Status 0;
BA_ "GenSigTimeoutTime_PBWM" SG_ 215 PCU_Max_ChargePowerLmt 0;
BA_ "GenSigTimeoutTime_MCPB" SG_ 215 PCU_Max_ChargePowerLmt 0;
BA_ "GenSigTimeoutTime_MCPA" SG_ 215 PCU_Max_ChargePowerLmt 0;
BA_ "GenSigTimeoutTime_IDCM" SG_ 215 PCU_Max_ChargePowerLmt 0;
BA_ "GenSigTimeoutTime_ECM" SG_ 215 PCU_Max_ChargePowerLmt 0;
BA_ "GenSigTimeoutTime_DMPI" SG_ 215 PCU_Max_ChargePowerLmt 0;
BA_ "GenSigTimeoutTime_BPCM" SG_ 215 PCU_Max_ChargePowerLmt 0;
BA_ "GenSigTimeoutTime_PBWM" SG_ 215 PCU_Max_DischargePowerLmt 0;
BA_ "GenSigTimeoutTime_MCPB" SG_ 215 PCU_Max_DischargePowerLmt 0;
BA_ "GenSigTimeoutTime_MCPA" SG_ 215 PCU_Max_DischargePowerLmt 0;
BA_ "GenSigTimeoutTime_IDCM" SG_ 215 PCU_Max_DischargePowerLmt 0;
BA_ "GenSigTimeoutTime_ECM" SG_ 215 PCU_Max_DischargePowerLmt 0;
BA_ "GenSigTimeoutTime_DMPI" SG_ 215 PCU_Max_DischargePowerLmt 0;
BA_ "GenSigTimeoutTime_BPCM" SG_ 215 PCU_Max_DischargePowerLmt 0;
BA_ "GenSigTimeoutTime_PBWM" SG_ 215 PCU_MaxBoostedVoltage 0;
BA_ "GenSigTimeoutTime_MCPB" SG_ 215 PCU_MaxBoostedVoltage 0;
BA_ "GenSigTimeoutTime_MCPA" SG_ 215 PCU_MaxBoostedVoltage 0;
BA_ "GenSigTimeoutTime_IDCM" SG_ 215 PCU_MaxBoostedVoltage 0;
BA_ "GenSigTimeoutTime_ECM" SG_ 215 PCU_MaxBoostedVoltage 0;
BA_ "GenSigTimeoutTime_DMPI" SG_ 215 PCU_MaxBoostedVoltage 0;
BA_ "GenSigTimeoutTime_BPCM" SG_ 215 PCU_MaxBoostedVoltage 0;
BA_ "GenSigTimeoutTime_PBWM" SG_ 215 PCU_MIL_Request 0;
BA_ "GenSigTimeoutTime_MCPB" SG_ 215 PCU_MIL_Request 0;
BA_ "GenSigTimeoutTime_MCPA" SG_ 215 PCU_MIL_Request 0;
BA_ "GenSigTimeoutTime_IDCM" SG_ 215 PCU_MIL_Request 0;
BA_ "GenSigTimeoutTime_ECM" SG_ 215 PCU_MIL_Request 0;
BA_ "GenSigTimeoutTime_DMPI" SG_ 215 PCU_MIL_Request 0;
BA_ "GenSigTimeoutTime_BPCM" SG_ 215 PCU_MIL_Request 0;
BA_ "GenSigTimeoutTime_PBWM" SG_ 215 PCU_Temporary_Stop_Flag 0;
BA_ "GenSigTimeoutTime_MCPB" SG_ 215 PCU_Temporary_Stop_Flag 0;
BA_ "GenSigTimeoutTime_MCPA" SG_ 215 PCU_Temporary_Stop_Flag 0;
BA_ "GenSigTimeoutTime_IDCM" SG_ 215 PCU_Temporary_Stop_Flag 0;
BA_ "GenSigTimeoutTime_ECM" SG_ 215 PCU_Temporary_Stop_Flag 0;
BA_ "GenSigTimeoutTime_DMPI" SG_ 215 PCU_Temporary_Stop_Flag 0;
BA_ "GenSigTimeoutTime_BPCM" SG_ 215 PCU_Temporary_Stop_Flag 0;
BA_ "GenSigTimeoutTime_PBWM" SG_ 215 Pinion_OverspeedWarning 0;
BA_ "GenSigTimeoutTime_MCPB" SG_ 215 Pinion_OverspeedWarning 0;
BA_ "GenSigTimeoutTime_MCPA" SG_ 215 Pinion_OverspeedWarning 0;
BA_ "GenSigTimeoutTime_IDCM" SG_ 215 Pinion_OverspeedWarning 0;
BA_ "GenSigTimeoutTime_ECM" SG_ 215 Pinion_OverspeedWarning 0;
BA_ "GenSigTimeoutTime_DMPI" SG_ 215 Pinion_OverspeedWarning 0;
BA_ "GenSigTimeoutTime_BPCM" SG_ 215 Pinion_OverspeedWarning 0;
BA_ "GenSigTimeoutTime_PBWM" SG_ 215 BoostConv_LowerIGBT_TempFltd 0;
BA_ "GenSigTimeoutTime_MCPB" SG_ 215 BoostConv_LowerIGBT_TempFltd 0;
BA_ "GenSigTimeoutTime_MCPA" SG_ 215 BoostConv_LowerIGBT_TempFltd 0;
BA_ "GenSigTimeoutTime_IDCM" SG_ 215 BoostConv_LowerIGBT_TempFltd 0;
BA_ "GenSigTimeoutTime_ECM" SG_ 215 BoostConv_LowerIGBT_TempFltd 0;
BA_ "GenSigTimeoutTime_DMPI" SG_ 215 BoostConv_LowerIGBT_TempFltd 0;
BA_ "GenSigTimeoutTime_BPCM" SG_ 215 BoostConv_LowerIGBT_TempFltd 0;
BA_ "GenSigTimeoutTime_PBWM" SG_ 215 BoostConv_ReactorTemp 0;
BA_ "GenSigTimeoutTime_MCPB" SG_ 215 BoostConv_ReactorTemp 0;
BA_ "GenSigTimeoutTime_MCPA" SG_ 215 BoostConv_ReactorTemp 0;
BA_ "GenSigTimeoutTime_IDCM" SG_ 215 BoostConv_ReactorTemp 0;
BA_ "GenSigTimeoutTime_ECM" SG_ 215 BoostConv_ReactorTemp 0;
BA_ "GenSigTimeoutTime_DMPI" SG_ 215 BoostConv_ReactorTemp 0;
BA_ "GenSigTimeoutTime_BPCM" SG_ 215 BoostConv_ReactorTemp 0;
BA_ "GenSigTimeoutTime_PBWM" SG_ 215 BoostConv_UpperIGBT_TempFltd 0;
BA_ "GenSigTimeoutTime_MCPB" SG_ 215 BoostConv_UpperIGBT_TempFltd 0;
BA_ "GenSigTimeoutTime_MCPA" SG_ 215 BoostConv_UpperIGBT_TempFltd 0;
BA_ "GenSigTimeoutTime_IDCM" SG_ 215 BoostConv_UpperIGBT_TempFltd 0;
BA_ "GenSigTimeoutTime_ECM" SG_ 215 BoostConv_UpperIGBT_TempFltd 0;
BA_ "GenSigTimeoutTime_DMPI" SG_ 215 BoostConv_UpperIGBT_TempFltd 0;
BA_ "GenSigTimeoutTime_BPCM" SG_ 215 BoostConv_UpperIGBT_TempFltd 0;
BA_ "GenSigTimeoutTime_PBWM" SG_ 215 BoostConverter_Current 0;
BA_ "GenSigTimeoutTime_MCPB" SG_ 215 BoostConverter_Current 0;
BA_ "GenSigTimeoutTime_MCPA" SG_ 215 BoostConverter_Current 0;
BA_ "GenSigTimeoutTime_IDCM" SG_ 215 BoostConverter_Current 0;
BA_ "GenSigTimeoutTime_ECM" SG_ 215 BoostConverter_Current 0;
BA_ "GenSigTimeoutTime_DMPI" SG_ 215 BoostConverter_Current 0;
BA_ "GenSigTimeoutTime_BPCM" SG_ 215 BoostConverter_Current 0;
BA_ "GenSigStartValue" SG_ 215 BoostConverter_Current 16384;
BA_ "GenSigTimeoutTime_PBWM" SG_ 215 BoostConverterFailureSts 0;
BA_ "GenSigTimeoutTime_MCPB" SG_ 215 BoostConverterFailureSts 0;
BA_ "GenSigTimeoutTime_MCPA" SG_ 215 BoostConverterFailureSts 0;
BA_ "GenSigTimeoutTime_IDCM" SG_ 215 BoostConverterFailureSts 0;
BA_ "GenSigTimeoutTime_ECM" SG_ 215 BoostConverterFailureSts 0;
BA_ "GenSigTimeoutTime_DMPI" SG_ 215 BoostConverterFailureSts 0;
BA_ "GenSigTimeoutTime_BPCM" SG_ 215 BoostConverterFailureSts 0;
BA_ "GenSigTimeoutTime_PBWM" SG_ 215 Cntr_PCU_FD_1 0;
BA_ "GenSigTimeoutTime_MCPB" SG_ 215 Cntr_PCU_FD_1 0;
BA_ "GenSigTimeoutTime_MCPA" SG_ 215 Cntr_PCU_FD_1 0;
BA_ "GenSigTimeoutTime_IDCM" SG_ 215 Cntr_PCU_FD_1 0;
BA_ "GenSigTimeoutTime_ECM" SG_ 215 Cntr_PCU_FD_1 0;
BA_ "GenSigTimeoutTime_DMPI" SG_ 215 Cntr_PCU_FD_1 0;
BA_ "GenSigTimeoutTime_BPCM" SG_ 215 Cntr_PCU_FD_1 0;
BA_ "GenSigTimeoutTime_PBWM" SG_ 215 CRC_PCU_FD_1 0;
BA_ "GenSigTimeoutTime_MCPB" SG_ 215 CRC_PCU_FD_1 0;
BA_ "GenSigTimeoutTime_MCPA" SG_ 215 CRC_PCU_FD_1 0;
BA_ "GenSigTimeoutTime_IDCM" SG_ 215 CRC_PCU_FD_1 0;
BA_ "GenSigTimeoutTime_ECM" SG_ 215 CRC_PCU_FD_1 0;
BA_ "GenSigTimeoutTime_DMPI" SG_ 215 CRC_PCU_FD_1 0;
BA_ "GenSigTimeoutTime_BPCM" SG_ 215 CRC_PCU_FD_1 0;
BA_ "GenSigTimeoutTime_PBWM" SG_ 215 MAC_PCU_FD_1 0;
BA_ "GenSigTimeoutTime_MCPB" SG_ 215 MAC_PCU_FD_1 0;
BA_ "GenSigTimeoutTime_MCPA" SG_ 215 MAC_PCU_FD_1 0;
BA_ "GenSigTimeoutTime_IDCM" SG_ 215 MAC_PCU_FD_1 0;
BA_ "GenSigTimeoutTime_ECM" SG_ 215 MAC_PCU_FD_1 0;
BA_ "GenSigTimeoutTime_DMPI" SG_ 215 MAC_PCU_FD_1 0;
BA_ "GenSigTimeoutTime_BPCM" SG_ 215 MAC_PCU_FD_1 0;
BA_ "GenSigTimeoutTime_PBWM" SG_ 215 MessageCounter_PCU_FD_1 0;
BA_ "GenSigTimeoutTime_MCPB" SG_ 215 MessageCounter_PCU_FD_1 0;
BA_ "GenSigTimeoutTime_MCPA" SG_ 215 MessageCounter_PCU_FD_1 0;
BA_ "GenSigTimeoutTime_IDCM" SG_ 215 MessageCounter_PCU_FD_1 0;
BA_ "GenSigTimeoutTime_ECM" SG_ 215 MessageCounter_PCU_FD_1 0;
BA_ "GenSigTimeoutTime_DMPI" SG_ 215 MessageCounter_PCU_FD_1 0;
BA_ "GenSigTimeoutTime_BPCM" SG_ 215 MessageCounter_PCU_FD_1 0;
BA_ "GenSigTimeoutTime_PBWM" SG_ 215 DMPI_TransmissionTemperature 0;
BA_ "GenSigTimeoutTime_MCPB" SG_ 215 DMPI_TransmissionTemperature 0;
BA_ "GenSigTimeoutTime_MCPA" SG_ 215 DMPI_TransmissionTemperature 0;
BA_ "GenSigTimeoutTime_IDCM" SG_ 215 DMPI_TransmissionTemperature 0;
BA_ "GenSigTimeoutTime_ECM" SG_ 215 DMPI_TransmissionTemperature 0;
BA_ "GenSigTimeoutTime_DMPI" SG_ 215 DMPI_TransmissionTemperature 0;
BA_ "GenSigTimeoutTime_BPCM" SG_ 215 DMPI_TransmissionTemperature 0;
BA_ "GenSigTimeoutTime_PBWM" SG_ 215 PCU_Max_DischargePowerLmt_ShrTrm 0;
BA_ "GenSigTimeoutTime_MCPB" SG_ 215 PCU_Max_DischargePowerLmt_ShrTrm 0;
BA_ "GenSigTimeoutTime_MCPA" SG_ 215 PCU_Max_DischargePowerLmt_ShrTrm 0;
BA_ "GenSigTimeoutTime_IDCM" SG_ 215 PCU_Max_DischargePowerLmt_ShrTrm 0;
BA_ "GenSigTimeoutTime_ECM" SG_ 215 PCU_Max_DischargePowerLmt_ShrTrm 0;
BA_ "GenSigTimeoutTime_DMPI" SG_ 215 PCU_Max_DischargePowerLmt_ShrTrm 0;
BA_ "GenSigTimeoutTime_BPCM" SG_ 215 PCU_Max_DischargePowerLmt_ShrTrm 0;
BA_ "GenSigTimeoutTime_PBWM" SG_ 215 DMPI_OilTemperatureSts 0;
BA_ "GenSigTimeoutTime_MCPB" SG_ 215 DMPI_OilTemperatureSts 0;
BA_ "GenSigTimeoutTime_MCPA" SG_ 215 DMPI_OilTemperatureSts 0;
BA_ "GenSigTimeoutTime_IDCM" SG_ 215 DMPI_OilTemperatureSts 0;
BA_ "GenSigTimeoutTime_ECM" SG_ 215 DMPI_OilTemperatureSts 0;
BA_ "GenSigTimeoutTime_DMPI" SG_ 215 DMPI_OilTemperatureSts 0;
BA_ "GenSigTimeoutTime_BPCM" SG_ 215 DMPI_OilTemperatureSts 0;
BA_ "GenSigTimeoutTime_PBWM" SG_ 215 BoostConverterDerateReason 0;
BA_ "GenSigTimeoutTime_MCPB" SG_ 215 BoostConverterDerateReason 0;
BA_ "GenSigTimeoutTime_MCPA" SG_ 215 BoostConverterDerateReason 0;
BA_ "GenSigTimeoutTime_IDCM" SG_ 215 BoostConverterDerateReason 0;
BA_ "GenSigTimeoutTime_ECM" SG_ 215 BoostConverterDerateReason 0;
BA_ "GenSigTimeoutTime_DMPI" SG_ 215 BoostConverterDerateReason 0;
BA_ "GenSigTimeoutTime_BPCM" SG_ 215 BoostConverterDerateReason 0;
BA_ "GenSigTimeoutTime_PBWM" SG_ 215 Output_Torque_Limit 0;
BA_ "GenSigTimeoutTime_MCPB" SG_ 215 Output_Torque_Limit 0;
BA_ "GenSigTimeoutTime_MCPA" SG_ 215 Output_Torque_Limit 0;
BA_ "GenSigTimeoutTime_IDCM" SG_ 215 Output_Torque_Limit 0;
BA_ "GenSigTimeoutTime_ECM" SG_ 215 Output_Torque_Limit 0;
BA_ "GenSigTimeoutTime_DMPI" SG_ 215 Output_Torque_Limit 0;
BA_ "GenSigTimeoutTime_BPCM" SG_ 215 Output_Torque_Limit 0;
BA_ "GenSigStartValue" SG_ 215 Output_Torque_Limit 32767;
BA_ "GenSigTimeoutTime_PBWM" SG_ 2654486592 CBV_bit0_RepeatMessageRequestBit 0;
BA_ "GenSigTimeoutTime_MCPB" SG_ 2654486592 CBV_bit0_RepeatMessageRequestBit 0;
BA_ "GenSigTimeoutTime_MCPA" SG_ 2654486592 CBV_bit0_RepeatMessageRequestBit 0;
BA_ "GenSigTimeoutTime_IDCM" SG_ 2654486592 CBV_bit0_RepeatMessageRequestBit 0;
BA_ "GenSigTimeoutTime_EVCU2" SG_ 2654486592 CBV_bit0_RepeatMessageRequestBit 0;
BA_ "GenSigTimeoutTime_ECM" SG_ 2654486592 CBV_bit0_RepeatMessageRequestBit 0;
BA_ "GenSigTimeoutTime_DMPI" SG_ 2654486592 CBV_bit0_RepeatMessageRequestBit 0;
BA_ "GenSigTimeoutTime_BPCM" SG_ 2654486592 CBV_bit0_RepeatMessageRequestBit 0;
BA_ "GenSigTimeoutTime_PBWM" SG_ 2654486592 CBV_bit1 0;
BA_ "GenSigTimeoutTime_MCPB" SG_ 2654486592 CBV_bit1 0;
BA_ "GenSigTimeoutTime_MCPA" SG_ 2654486592 CBV_bit1 0;
BA_ "GenSigTimeoutTime_IDCM" SG_ 2654486592 CBV_bit1 0;
BA_ "GenSigTimeoutTime_EVCU2" SG_ 2654486592 CBV_bit1 0;
BA_ "GenSigTimeoutTime_ECM" SG_ 2654486592 CBV_bit1 0;
BA_ "GenSigTimeoutTime_DMPI" SG_ 2654486592 CBV_bit1 0;
BA_ "GenSigTimeoutTime_BPCM" SG_ 2654486592 CBV_bit1 0;
BA_ "GenSigTimeoutTime_PBWM" SG_ 2654486592 CBV_bit2 0;
BA_ "GenSigTimeoutTime_MCPB" SG_ 2654486592 CBV_bit2 0;
BA_ "GenSigTimeoutTime_MCPA" SG_ 2654486592 CBV_bit2 0;
BA_ "GenSigTimeoutTime_IDCM" SG_ 2654486592 CBV_bit2 0;
BA_ "GenSigTimeoutTime_EVCU2" SG_ 2654486592 CBV_bit2 0;
BA_ "GenSigTimeoutTime_ECM" SG_ 2654486592 CBV_bit2 0;
BA_ "GenSigTimeoutTime_DMPI" SG_ 2654486592 CBV_bit2 0;
BA_ "GenSigTimeoutTime_BPCM" SG_ 2654486592 CBV_bit2 0;
BA_ "GenSigTimeoutTime_MCPA" SG_ 2654486592 CBV_bit3_NMCoordinatorBit 0;
BA_ "GenSigTimeoutTime_IDCM" SG_ 2654486592 CBV_bit3_NMCoordinatorBit 0;
BA_ "GenSigTimeoutTime_EVCU2" SG_ 2654486592 CBV_bit3_NMCoordinatorBit 0;
BA_ "GenSigTimeoutTime_ECM" SG_ 2654486592 CBV_bit3_NMCoordinatorBit 0;
BA_ "GenSigTimeoutTime_DMPI" SG_ 2654486592 CBV_bit3_NMCoordinatorBit 0;
BA_ "GenSigTimeoutTime_BPCM" SG_ 2654486592 CBV_bit3_NMCoordinatorBit 0;
BA_ "GenSigTimeoutTime_PBWM" SG_ 2654486592 CBV_bit3_NMCoordinatorBit 0;
BA_ "GenSigTimeoutTime_MCPB" SG_ 2654486592 CBV_bit3_NMCoordinatorBit 0;
BA_ "GenSigTimeoutTime_PBWM" SG_ 2654486592 CBV_bit4_ActiveWakeupBit 0;
BA_ "GenSigTimeoutTime_MCPB" SG_ 2654486592 CBV_bit4_ActiveWakeupBit 0;
BA_ "GenSigTimeoutTime_MCPA" SG_ 2654486592 CBV_bit4_ActiveWakeupBit 0;
BA_ "GenSigTimeoutTime_IDCM" SG_ 2654486592 CBV_bit4_ActiveWakeupBit 0;
BA_ "GenSigTimeoutTime_EVCU2" SG_ 2654486592 CBV_bit4_ActiveWakeupBit 0;
BA_ "GenSigTimeoutTime_ECM" SG_ 2654486592 CBV_bit4_ActiveWakeupBit 0;
BA_ "GenSigTimeoutTime_DMPI" SG_ 2654486592 CBV_bit4_ActiveWakeupBit 0;
BA_ "GenSigTimeoutTime_BPCM" SG_ 2654486592 CBV_bit4_ActiveWakeupBit 0;
BA_ "GenSigTimeoutTime_PBWM" SG_ 2654486592 CBV_bit5 0;
BA_ "GenSigTimeoutTime_MCPB" SG_ 2654486592 CBV_bit5 0;
BA_ "GenSigTimeoutTime_MCPA" SG_ 2654486592 CBV_bit5 0;
BA_ "GenSigTimeoutTime_IDCM" SG_ 2654486592 CBV_bit5 0;
BA_ "GenSigTimeoutTime_EVCU2" SG_ 2654486592 CBV_bit5 0;
BA_ "GenSigTimeoutTime_ECM" SG_ 2654486592 CBV_bit5 0;
BA_ "GenSigTimeoutTime_DMPI" SG_ 2654486592 CBV_bit5 0;
BA_ "GenSigTimeoutTime_BPCM" SG_ 2654486592 CBV_bit5 0;
BA_ "GenSigTimeoutTime_PBWM" SG_ 2654486592 CBV_bit6_PartialNtwInfBit 0;
BA_ "GenSigTimeoutTime_MCPB" SG_ 2654486592 CBV_bit6_PartialNtwInfBit 0;
BA_ "GenSigTimeoutTime_MCPA" SG_ 2654486592 CBV_bit6_PartialNtwInfBit 0;
BA_ "GenSigTimeoutTime_IDCM" SG_ 2654486592 CBV_bit6_PartialNtwInfBit 0;
BA_ "GenSigTimeoutTime_EVCU2" SG_ 2654486592 CBV_bit6_PartialNtwInfBit 0;
BA_ "GenSigTimeoutTime_ECM" SG_ 2654486592 CBV_bit6_PartialNtwInfBit 0;
BA_ "GenSigTimeoutTime_DMPI" SG_ 2654486592 CBV_bit6_PartialNtwInfBit 0;
BA_ "GenSigTimeoutTime_BPCM" SG_ 2654486592 CBV_bit6_PartialNtwInfBit 0;
BA_ "GenSigTimeoutTime_PBWM" SG_ 2654486592 CBV_bit7 0;
BA_ "GenSigTimeoutTime_MCPB" SG_ 2654486592 CBV_bit7 0;
BA_ "GenSigTimeoutTime_MCPA" SG_ 2654486592 CBV_bit7 0;
BA_ "GenSigTimeoutTime_IDCM" SG_ 2654486592 CBV_bit7 0;
BA_ "GenSigTimeoutTime_EVCU2" SG_ 2654486592 CBV_bit7 0;
BA_ "GenSigTimeoutTime_ECM" SG_ 2654486592 CBV_bit7 0;
BA_ "GenSigTimeoutTime_DMPI" SG_ 2654486592 CBV_bit7 0;
BA_ "GenSigTimeoutTime_BPCM" SG_ 2654486592 CBV_bit7 0;
BA_ "GenSigTimeoutTime_PBWM" SG_ 2654486592 SourceNodeIdentifier 0;
BA_ "GenSigTimeoutTime_MCPB" SG_ 2654486592 SourceNodeIdentifier 0;
BA_ "GenSigTimeoutTime_MCPA" SG_ 2654486592 SourceNodeIdentifier 0;
BA_ "GenSigTimeoutTime_IDCM" SG_ 2654486592 SourceNodeIdentifier 0;
BA_ "GenSigTimeoutTime_EVCU2" SG_ 2654486592 SourceNodeIdentifier 0;
BA_ "GenSigTimeoutTime_ECM" SG_ 2654486592 SourceNodeIdentifier 0;
BA_ "GenSigTimeoutTime_DMPI" SG_ 2654486592 SourceNodeIdentifier 0;
BA_ "GenSigTimeoutTime_BPCM" SG_ 2654486592 SourceNodeIdentifier 0;
BA_ "GenSigTimeoutTime_PBWM" SG_ 2564554485 N_PDU 0;
BA_ "GenSigTimeoutTime_MCPB" SG_ 2564554485 N_PDU 0;
BA_ "GenSigTimeoutTime_MCPA" SG_ 2564554485 N_PDU 0;
BA_ "GenSigTimeoutTime_IDCM" SG_ 2564554485 N_PDU 0;
BA_ "GenSigTimeoutTime_EVCU2" SG_ 2564554485 N_PDU 0;
BA_ "GenSigTimeoutTime_ECM" SG_ 2564554485 N_PDU 0;
BA_ "GenSigTimeoutTime_DMPI" SG_ 2564554485 N_PDU 0;
BA_ "GenSigTimeoutTime_BPCM" SG_ 2564554485 N_PDU 0;
BA_ "GenSigTimeoutTime_PBWM" SG_ 485 BPCM_Max_Pk_Volt_Allowed 0;
BA_ "GenSigTimeoutTime_MCPB" SG_ 485 BPCM_Max_Pk_Volt_Allowed 0;
BA_ "GenSigTimeoutTime_MCPA" SG_ 485 BPCM_Max_Pk_Volt_Allowed 0;
BA_ "GenSigTimeoutTime_IDCM" SG_ 485 BPCM_Max_Pk_Volt_Allowed 0;
BA_ "GenSigTimeoutTime_ECM" SG_ 485 BPCM_Max_Pk_Volt_Allowed 0;
BA_ "GenSigTimeoutTime_DMPI" SG_ 485 BPCM_Max_Pk_Volt_Allowed 0;
BA_ "GenSigTimeoutTime_BPCM" SG_ 485 BPCM_Max_Pk_Volt_Allowed 0;
BA_ "GenSigTimeoutTime_PBWM" SG_ 485 BPCM_Min_Pk_Volt_Allowed 0;
BA_ "GenSigTimeoutTime_MCPB" SG_ 485 BPCM_Min_Pk_Volt_Allowed 0;
BA_ "GenSigTimeoutTime_MCPA" SG_ 485 BPCM_Min_Pk_Volt_Allowed 0;
BA_ "GenSigTimeoutTime_IDCM" SG_ 485 BPCM_Min_Pk_Volt_Allowed 0;
BA_ "GenSigTimeoutTime_ECM" SG_ 485 BPCM_Min_Pk_Volt_Allowed 0;
BA_ "GenSigTimeoutTime_DMPI" SG_ 485 BPCM_Min_Pk_Volt_Allowed 0;
BA_ "GenSigTimeoutTime_BPCM" SG_ 485 BPCM_Min_Pk_Volt_Allowed 0;
BA_ "GenSigTimeoutTime_PBWM" SG_ 485 BPCM_OCV_Avg_Cell_Volt 0;
BA_ "GenSigTimeoutTime_MCPB" SG_ 485 BPCM_OCV_Avg_Cell_Volt 0;
BA_ "GenSigTimeoutTime_MCPA" SG_ 485 BPCM_OCV_Avg_Cell_Volt 0;
BA_ "GenSigTimeoutTime_IDCM" SG_ 485 BPCM_OCV_Avg_Cell_Volt 0;
BA_ "GenSigTimeoutTime_ECM" SG_ 485 BPCM_OCV_Avg_Cell_Volt 0;
BA_ "GenSigTimeoutTime_DMPI" SG_ 485 BPCM_OCV_Avg_Cell_Volt 0;
BA_ "GenSigTimeoutTime_BPCM" SG_ 485 BPCM_OCV_Avg_Cell_Volt 0;
BA_ "GenSigTimeoutTime_PBWM" SG_ 485 BPCM_OCV_Max_Cell_Volt 0;
BA_ "GenSigTimeoutTime_MCPB" SG_ 485 BPCM_OCV_Max_Cell_Volt 0;
BA_ "GenSigTimeoutTime_MCPA" SG_ 485 BPCM_OCV_Max_Cell_Volt 0;
BA_ "GenSigTimeoutTime_IDCM" SG_ 485 BPCM_OCV_Max_Cell_Volt 0;
BA_ "GenSigTimeoutTime_ECM" SG_ 485 BPCM_OCV_Max_Cell_Volt 0;
BA_ "GenSigTimeoutTime_DMPI" SG_ 485 BPCM_OCV_Max_Cell_Volt 0;
BA_ "GenSigTimeoutTime_BPCM" SG_ 485 BPCM_OCV_Max_Cell_Volt 0;
BA_ "GenSigTimeoutTime_PBWM" SG_ 485 BPCM_OCV_Min_Cell_Volt 0;
BA_ "GenSigTimeoutTime_MCPB" SG_ 485 BPCM_OCV_Min_Cell_Volt 0;
BA_ "GenSigTimeoutTime_MCPA" SG_ 485 BPCM_OCV_Min_Cell_Volt 0;
BA_ "GenSigTimeoutTime_IDCM" SG_ 485 BPCM_OCV_Min_Cell_Volt 0;
BA_ "GenSigTimeoutTime_ECM" SG_ 485 BPCM_OCV_Min_Cell_Volt 0;
BA_ "GenSigTimeoutTime_DMPI" SG_ 485 BPCM_OCV_Min_Cell_Volt 0;
BA_ "GenSigTimeoutTime_BPCM" SG_ 485 BPCM_OCV_Min_Cell_Volt 0;
BA_ "GenSigTimeoutTime_PBWM" SG_ 485 BPCM_HV_NumCellMinVolt 0;
BA_ "GenSigTimeoutTime_MCPB" SG_ 485 BPCM_HV_NumCellMinVolt 0;
BA_ "GenSigTimeoutTime_MCPA" SG_ 485 BPCM_HV_NumCellMinVolt 0;
BA_ "GenSigTimeoutTime_IDCM" SG_ 485 BPCM_HV_NumCellMinVolt 0;
BA_ "GenSigTimeoutTime_ECM" SG_ 485 BPCM_HV_NumCellMinVolt 0;
BA_ "GenSigTimeoutTime_DMPI" SG_ 485 BPCM_HV_NumCellMinVolt 0;
BA_ "GenSigTimeoutTime_BPCM" SG_ 485 BPCM_HV_NumCellMinVolt 0;
BA_ "GenSigTimeoutTime_PBWM" SG_ 485 BPCM_HV_NumCellMinTemp 0;
BA_ "GenSigTimeoutTime_PBWM" SG_ 485 CRC_BATT_HV_VLIMITS 0;
BA_ "GenSigTimeoutTime_MCPB" SG_ 485 CRC_BATT_HV_VLIMITS 0;
BA_ "GenSigTimeoutTime_MCPA" SG_ 485 CRC_BATT_HV_VLIMITS 0;
BA_ "GenSigTimeoutTime_IDCM" SG_ 485 CRC_BATT_HV_VLIMITS 0;
BA_ "GenSigTimeoutTime_ECM" SG_ 485 CRC_BATT_HV_VLIMITS 0;
BA_ "GenSigTimeoutTime_DMPI" SG_ 485 CRC_BATT_HV_VLIMITS 0;
BA_ "GenSigTimeoutTime_BPCM" SG_ 485 CRC_BATT_HV_VLIMITS 0;
BA_ "GenSigTimeoutTime_PBWM" SG_ 485 MessageCounter_BATT_HV_VLIMITS 0;
BA_ "GenSigTimeoutTime_MCPB" SG_ 485 MessageCounter_BATT_HV_VLIMITS 0;
BA_ "GenSigTimeoutTime_MCPA" SG_ 485 MessageCounter_BATT_HV_VLIMITS 0;
BA_ "GenSigTimeoutTime_IDCM" SG_ 485 MessageCounter_BATT_HV_VLIMITS 0;
BA_ "GenSigTimeoutTime_ECM" SG_ 485 MessageCounter_BATT_HV_VLIMITS 0;
BA_ "GenSigTimeoutTime_DMPI" SG_ 485 MessageCounter_BATT_HV_VLIMITS 0;
BA_ "GenSigTimeoutTime_BPCM" SG_ 485 MessageCounter_BATT_HV_VLIMITS 0;
BA_ "GenSigTimeoutTime_PBWM" SG_ 485 BPCM_Max_Cell_Volt_Allowed 0;
BA_ "GenSigTimeoutTime_MCPB" SG_ 485 BPCM_Max_Cell_Volt_Allowed 0;
BA_ "GenSigTimeoutTime_MCPA" SG_ 485 BPCM_Max_Cell_Volt_Allowed 0;
BA_ "GenSigTimeoutTime_IDCM" SG_ 485 BPCM_Max_Cell_Volt_Allowed 0;
BA_ "GenSigTimeoutTime_ECM" SG_ 485 BPCM_Max_Cell_Volt_Allowed 0;
BA_ "GenSigTimeoutTime_DMPI" SG_ 485 BPCM_Max_Cell_Volt_Allowed 0;
BA_ "GenSigTimeoutTime_BPCM" SG_ 485 BPCM_Max_Cell_Volt_Allowed 0;
BA_ "GenSigTimeoutTime_MCPB" SG_ 485 BPCM_Min_Cell_Volt_Allowed 0;
BA_ "GenSigTimeoutTime_MCPA" SG_ 485 BPCM_Min_Cell_Volt_Allowed 0;
BA_ "GenSigTimeoutTime_IDCM" SG_ 485 BPCM_Min_Cell_Volt_Allowed 0;
BA_ "GenSigTimeoutTime_ECM" SG_ 485 BPCM_Min_Cell_Volt_Allowed 0;
BA_ "GenSigTimeoutTime_DMPI" SG_ 485 BPCM_Min_Cell_Volt_Allowed 0;
BA_ "GenSigTimeoutTime_BPCM" SG_ 485 BPCM_Min_Cell_Volt_Allowed 0;
BA_ "GenSigTimeoutTime_PBWM" SG_ 485 BPCM_Min_Cell_Volt_Allowed 0;
BA_ "GenSigTimeoutTime_PBWM" SG_ 485 BPCM_Cell_Volt_Min 0;
BA_ "GenSigTimeoutTime_MCPB" SG_ 485 BPCM_Cell_Volt_Min 0;
BA_ "GenSigTimeoutTime_MCPA" SG_ 485 BPCM_Cell_Volt_Min 0;
BA_ "GenSigTimeoutTime_IDCM" SG_ 485 BPCM_Cell_Volt_Min 0;
BA_ "GenSigTimeoutTime_ECM" SG_ 485 BPCM_Cell_Volt_Min 0;
BA_ "GenSigTimeoutTime_DMPI" SG_ 485 BPCM_Cell_Volt_Min 0;
BA_ "GenSigTimeoutTime_BPCM" SG_ 485 BPCM_Cell_Volt_Min 0;
BA_ "GenSigTimeoutTime_PBWM" SG_ 485 BPCM_HV_Insulation_Resistance 0;
BA_ "GenSigTimeoutTime_MCPB" SG_ 485 BPCM_HV_Insulation_Resistance 0;
BA_ "GenSigTimeoutTime_MCPA" SG_ 485 BPCM_HV_Insulation_Resistance 0;
BA_ "GenSigTimeoutTime_IDCM" SG_ 485 BPCM_HV_Insulation_Resistance 0;
BA_ "GenSigTimeoutTime_ECM" SG_ 485 BPCM_HV_Insulation_Resistance 0;
BA_ "GenSigTimeoutTime_DMPI" SG_ 485 BPCM_HV_Insulation_Resistance 0;
BA_ "GenSigTimeoutTime_BPCM" SG_ 485 BPCM_HV_Insulation_Resistance 0;
BA_ "GenSigTimeoutTime_BPCM" SG_ 292 BPCM_HV_Temperature_Max 0;
BA_ "GenSigTimeoutTime_PBWM" SG_ 292 BPCM_HV_Temperature_Max 0;
BA_ "GenSigTimeoutTime_MCPB" SG_ 292 BPCM_HV_Temperature_Max 0;
BA_ "GenSigTimeoutTime_MCPA" SG_ 292 BPCM_HV_Temperature_Max 0;
BA_ "GenSigTimeoutTime_IDCM" SG_ 292 BPCM_HV_Temperature_Max 0;
BA_ "GenSigTimeoutTime_ECM" SG_ 292 BPCM_HV_Temperature_Max 0;
BA_ "GenSigTimeoutTime_DMPI" SG_ 292 BPCM_HV_Temperature_Max 0;
BA_ "GenSigTimeoutTime_PBWM" SG_ 292 BPCM_HV_Temperature_Min 0;
BA_ "GenSigTimeoutTime_MCPB" SG_ 292 BPCM_HV_Temperature_Min 0;
BA_ "GenSigTimeoutTime_MCPA" SG_ 292 BPCM_HV_Temperature_Min 0;
BA_ "GenSigTimeoutTime_IDCM" SG_ 292 BPCM_HV_Temperature_Min 0;
BA_ "GenSigTimeoutTime_ECM" SG_ 292 BPCM_HV_Temperature_Min 0;
BA_ "GenSigTimeoutTime_DMPI" SG_ 292 BPCM_HV_Temperature_Min 0;
BA_ "GenSigTimeoutTime_BPCM" SG_ 292 BPCM_HV_Temperature_Min 0;
BA_ "GenSigTimeoutTime_PBWM" SG_ 485 BPCM_Cell_Volt_Avg 0;
BA_ "GenSigTimeoutTime_MCPB" SG_ 485 BPCM_Cell_Volt_Avg 0;
BA_ "GenSigTimeoutTime_MCPA" SG_ 485 BPCM_Cell_Volt_Avg 0;
BA_ "GenSigTimeoutTime_IDCM" SG_ 485 BPCM_Cell_Volt_Avg 0;
BA_ "GenSigTimeoutTime_ECM" SG_ 485 BPCM_Cell_Volt_Avg 0;
BA_ "GenSigTimeoutTime_DMPI" SG_ 485 BPCM_Cell_Volt_Avg 0;
BA_ "GenSigTimeoutTime_BPCM" SG_ 485 BPCM_Cell_Volt_Avg 0;
BA_ "GenSigTimeoutTime_PBWM" SG_ 485 BPCM_Cell_Volt_Max 0;
BA_ "GenSigTimeoutTime_MCPB" SG_ 485 BPCM_Cell_Volt_Max 0;
BA_ "GenSigTimeoutTime_MCPA" SG_ 485 BPCM_Cell_Volt_Max 0;
BA_ "GenSigTimeoutTime_IDCM" SG_ 485 BPCM_Cell_Volt_Max 0;
BA_ "GenSigTimeoutTime_ECM" SG_ 485 BPCM_Cell_Volt_Max 0;
BA_ "GenSigTimeoutTime_DMPI" SG_ 485 BPCM_Cell_Volt_Max 0;
BA_ "GenSigTimeoutTime_BPCM" SG_ 485 BPCM_Cell_Volt_Max 0;
BA_ "GenSigTimeoutTime_PBWM" SG_ 292 BPCM_HV_SOC 0;
BA_ "GenSigTimeoutTime_MCPB" SG_ 292 BPCM_HV_SOC 0;
BA_ "GenSigTimeoutTime_MCPA" SG_ 292 BPCM_HV_SOC 0;
BA_ "GenSigTimeoutTime_IDCM" SG_ 292 BPCM_HV_SOC 0;
BA_ "GenSigTimeoutTime_ECM" SG_ 292 BPCM_HV_SOC 0;
BA_ "GenSigTimeoutTime_BPCM" SG_ 292 BPCM_HV_SOC 0;
BA_ "GenSigTimeoutTime_PBWM" SG_ 292 BPCM_HV_Temperature_Avg 0;
BA_ "GenSigTimeoutTime_MCPB" SG_ 292 BPCM_HV_Temperature_Avg 0;
BA_ "GenSigTimeoutTime_MCPA" SG_ 292 BPCM_HV_Temperature_Avg 0;
BA_ "GenSigTimeoutTime_IDCM" SG_ 292 BPCM_HV_Temperature_Avg 0;
BA_ "GenSigTimeoutTime_ECM" SG_ 292 BPCM_HV_Temperature_Avg 0;
BA_ "GenSigTimeoutTime_DMPI" SG_ 292 BPCM_HV_Temperature_Avg 0;
BA_ "GenSigTimeoutTime_BPCM" SG_ 292 BPCM_HV_Temperature_Avg 0;
BA_ "GenSigTimeoutTime_PBWM" SG_ 292 BPCM_Wakeup_Request 0;
BA_ "GenSigTimeoutTime_MCPB" SG_ 292 BPCM_Wakeup_Request 0;
BA_ "GenSigTimeoutTime_MCPA" SG_ 292 BPCM_Wakeup_Request 0;
BA_ "GenSigTimeoutTime_IDCM" SG_ 292 BPCM_Wakeup_Request 0;
BA_ "GenSigTimeoutTime_ECM" SG_ 292 BPCM_Wakeup_Request 0;
BA_ "GenSigTimeoutTime_DMPI" SG_ 292 BPCM_Wakeup_Request 0;
BA_ "GenSigTimeoutTime_BPCM" SG_ 292 BPCM_Wakeup_Request 0;
BA_ "GenSigSendType" SG_ 292 BPCM_Wakeup_Request 3;
BA_ "GenSigTimeoutTime_PBWM" SG_ 292 BPCM_HV_ThermalRunaway 0;
BA_ "GenSigTimeoutTime_MCPB" SG_ 292 BPCM_HV_ThermalRunaway 0;
BA_ "GenSigTimeoutTime_MCPA" SG_ 292 BPCM_HV_ThermalRunaway 0;
BA_ "GenSigTimeoutTime_IDCM" SG_ 292 BPCM_HV_ThermalRunaway 0;
BA_ "GenSigTimeoutTime_ECM" SG_ 292 BPCM_HV_ThermalRunaway 0;
BA_ "GenSigTimeoutTime_DMPI" SG_ 292 BPCM_HV_ThermalRunaway 0;
BA_ "GenSigTimeoutTime_BPCM" SG_ 292 BPCM_HV_ThermalRunaway 0;
BA_ "GenSigSendType" SG_ 292 BPCM_HV_ThermalRunaway 3;
BA_ "GenSigTimeoutTime_PBWM" SG_ 292 HVBP_Busbar_Temp 0;
BA_ "GenSigTimeoutTime_MCPB" SG_ 292 HVBP_Busbar_Temp 0;
BA_ "GenSigTimeoutTime_MCPA" SG_ 292 HVBP_Busbar_Temp 0;
BA_ "GenSigTimeoutTime_IDCM" SG_ 292 HVBP_Busbar_Temp 0;
BA_ "GenSigTimeoutTime_ECM" SG_ 292 HVBP_Busbar_Temp 0;
BA_ "GenSigTimeoutTime_DMPI" SG_ 292 HVBP_Busbar_Temp 0;
BA_ "GenSigTimeoutTime_BPCM" SG_ 292 HVBP_Busbar_Temp 0;
BA_ "GenSigTimeoutTime_PBWM" SG_ 292 BPCM_MILRequest 0;
BA_ "GenSigTimeoutTime_MCPB" SG_ 292 BPCM_MILRequest 0;
BA_ "GenSigTimeoutTime_MCPA" SG_ 292 BPCM_MILRequest 0;
BA_ "GenSigTimeoutTime_IDCM" SG_ 292 BPCM_MILRequest 0;
BA_ "GenSigTimeoutTime_ECM" SG_ 292 BPCM_MILRequest 0;
BA_ "GenSigTimeoutTime_DMPI" SG_ 292 BPCM_MILRequest 0;
BA_ "GenSigTimeoutTime_BPCM" SG_ 292 BPCM_MILRequest 0;
BA_ "GenSigTimeoutTime_PBWM" SG_ 292 HVBP_BDU_Busbar_Temp 0;
BA_ "GenSigTimeoutTime_MCPB" SG_ 292 HVBP_BDU_Busbar_Temp 0;
BA_ "GenSigTimeoutTime_MCPA" SG_ 292 HVBP_BDU_Busbar_Temp 0;
BA_ "GenSigTimeoutTime_IDCM" SG_ 292 HVBP_BDU_Busbar_Temp 0;
BA_ "GenSigTimeoutTime_ECM" SG_ 292 HVBP_BDU_Busbar_Temp 0;
BA_ "GenSigTimeoutTime_DMPI" SG_ 292 HVBP_BDU_Busbar_Temp 0;
BA_ "GenSigTimeoutTime_BPCM" SG_ 292 HVBP_BDU_Busbar_Temp 0;
BA_ "GenSigTimeoutTime_PBWM" SG_ 292 BPCM_HV_Trac_PreCha_Contac_Sts 0;
BA_ "GenSigTimeoutTime_MCPB" SG_ 292 BPCM_HV_Trac_PreCha_Contac_Sts 0;
BA_ "GenSigTimeoutTime_MCPA" SG_ 292 BPCM_HV_Trac_PreCha_Contac_Sts 0;
BA_ "GenSigTimeoutTime_IDCM" SG_ 292 BPCM_HV_Trac_PreCha_Contac_Sts 0;
BA_ "GenSigTimeoutTime_ECM" SG_ 292 BPCM_HV_Trac_PreCha_Contac_Sts 0;
BA_ "GenSigTimeoutTime_DMPI" SG_ 292 BPCM_HV_Trac_PreCha_Contac_Sts 0;
BA_ "GenSigTimeoutTime_BPCM" SG_ 292 BPCM_HV_Trac_PreCha_Contac_Sts 0;
BA_ "GenSigTimeoutTime_PBWM" SG_ 292 HVBatLastSlept 0;
BA_ "GenSigTimeoutTime_MCPB" SG_ 292 HVBatLastSlept 0;
BA_ "GenSigTimeoutTime_MCPA" SG_ 292 HVBatLastSlept 0;
BA_ "GenSigTimeoutTime_IDCM" SG_ 292 HVBatLastSlept 0;
BA_ "GenSigTimeoutTime_ECM" SG_ 292 HVBatLastSlept 0;
BA_ "GenSigTimeoutTime_DMPI" SG_ 292 HVBatLastSlept 0;
BA_ "GenSigTimeoutTime_BPCM" SG_ 292 HVBatLastSlept 0;
BA_ "GenSigTimeoutTime_PBWM" SG_ 292 HVBatContactorOpenTime 0;
BA_ "GenSigTimeoutTime_MCPB" SG_ 292 HVBatContactorOpenTime 0;
BA_ "GenSigTimeoutTime_MCPA" SG_ 292 HVBatContactorOpenTime 0;
BA_ "GenSigTimeoutTime_IDCM" SG_ 292 HVBatContactorOpenTime 0;
BA_ "GenSigTimeoutTime_ECM" SG_ 292 HVBatContactorOpenTime 0;
BA_ "GenSigTimeoutTime_DMPI" SG_ 292 HVBatContactorOpenTime 0;
BA_ "GenSigTimeoutTime_BPCM" SG_ 292 HVBatContactorOpenTime 0;
BA_ "GenSigTimeoutTime_MCPB" SG_ 485 BPCM_HV_NumCellMinTemp 0;
BA_ "GenSigTimeoutTime_MCPA" SG_ 485 BPCM_HV_NumCellMinTemp 0;
BA_ "GenSigTimeoutTime_IDCM" SG_ 485 BPCM_HV_NumCellMinTemp 0;
BA_ "GenSigTimeoutTime_ECM" SG_ 485 BPCM_HV_NumCellMinTemp 0;
BA_ "GenSigTimeoutTime_DMPI" SG_ 485 BPCM_HV_NumCellMinTemp 0;
BA_ "GenSigTimeoutTime_BPCM" SG_ 485 BPCM_HV_NumCellMinTemp 0;
BA_ "GenSigTimeoutTime_PBWM" SG_ 485 BPCM_HV_NumCellMaxTemp 0;
BA_ "GenSigTimeoutTime_MCPB" SG_ 485 BPCM_HV_NumCellMaxTemp 0;
BA_ "GenSigTimeoutTime_MCPA" SG_ 485 BPCM_HV_NumCellMaxTemp 0;
BA_ "GenSigTimeoutTime_IDCM" SG_ 485 BPCM_HV_NumCellMaxTemp 0;
BA_ "GenSigTimeoutTime_ECM" SG_ 485 BPCM_HV_NumCellMaxTemp 0;
BA_ "GenSigTimeoutTime_DMPI" SG_ 485 BPCM_HV_NumCellMaxTemp 0;
BA_ "GenSigTimeoutTime_BPCM" SG_ 485 BPCM_HV_NumCellMaxTemp 0;
BA_ "GenSigTimeoutTime_PBWM" SG_ 485 BPCM_HV_NumCellMaxVolt 0;
BA_ "GenSigTimeoutTime_MCPB" SG_ 485 BPCM_HV_NumCellMaxVolt 0;
BA_ "GenSigTimeoutTime_MCPA" SG_ 485 BPCM_HV_NumCellMaxVolt 0;
BA_ "GenSigTimeoutTime_IDCM" SG_ 485 BPCM_HV_NumCellMaxVolt 0;
BA_ "GenSigTimeoutTime_ECM" SG_ 485 BPCM_HV_NumCellMaxVolt 0;
BA_ "GenSigTimeoutTime_DMPI" SG_ 485 BPCM_HV_NumCellMaxVolt 0;
BA_ "GenSigTimeoutTime_BPCM" SG_ 485 BPCM_HV_NumCellMaxVolt 0;
BA_ "GenSigTimeoutTime_PBWM" SG_ 292 BPCMInterlockSts 0;
BA_ "GenSigTimeoutTime_MCPB" SG_ 292 BPCMInterlockSts 0;
BA_ "GenSigTimeoutTime_MCPA" SG_ 292 BPCMInterlockSts 0;
BA_ "GenSigTimeoutTime_IDCM" SG_ 292 BPCMInterlockSts 0;
BA_ "GenSigTimeoutTime_ECM" SG_ 292 BPCMInterlockSts 0;
BA_ "GenSigTimeoutTime_DMPI" SG_ 292 BPCMInterlockSts 0;
BA_ "GenSigTimeoutTime_BPCM" SG_ 292 BPCMInterlockSts 0;
BA_ "GenSigTimeoutTime_PBWM" SG_ 292 CRC_BATT_HV_STATUS1 0;
BA_ "GenSigTimeoutTime_ECM" SG_ 292 CRC_BATT_HV_STATUS1 0;
BA_ "GenSigTimeoutTime_BPCM" SG_ 292 CRC_BATT_HV_STATUS1 0;
BA_ "GenSigTimeoutTime_PBWM" SG_ 292 HVBatContactorWeldCheck 0;
BA_ "GenSigTimeoutTime_MCPB" SG_ 292 HVBatContactorWeldCheck 0;
BA_ "GenSigTimeoutTime_MCPA" SG_ 292 HVBatContactorWeldCheck 0;
BA_ "GenSigTimeoutTime_IDCM" SG_ 292 HVBatContactorWeldCheck 0;
BA_ "GenSigTimeoutTime_ECM" SG_ 292 HVBatContactorWeldCheck 0;
BA_ "GenSigTimeoutTime_DMPI" SG_ 292 HVBatContactorWeldCheck 0;
BA_ "GenSigTimeoutTime_BPCM" SG_ 292 HVBatContactorWeldCheck 0;
BA_ "GenSigTimeoutTime_PBWM" SG_ 292 HVBatReady 0;
BA_ "GenSigTimeoutTime_MCPB" SG_ 292 HVBatReady 0;
BA_ "GenSigTimeoutTime_MCPA" SG_ 292 HVBatReady 0;
BA_ "GenSigTimeoutTime_IDCM" SG_ 292 HVBatReady 0;
BA_ "GenSigTimeoutTime_ECM" SG_ 292 HVBatReady 0;
BA_ "GenSigTimeoutTime_DMPI" SG_ 292 HVBatReady 0;
BA_ "GenSigTimeoutTime_BPCM" SG_ 292 HVBatReady 0;
BA_ "GenSigTimeoutTime_PBWM" SG_ 292 BPCM_ImpactHardwire 0;
BA_ "GenSigTimeoutTime_MCPB" SG_ 292 BPCM_ImpactHardwire 0;
BA_ "GenSigTimeoutTime_MCPA" SG_ 292 BPCM_ImpactHardwire 0;
BA_ "GenSigTimeoutTime_IDCM" SG_ 292 BPCM_ImpactHardwire 0;
BA_ "GenSigTimeoutTime_ECM" SG_ 292 BPCM_ImpactHardwire 0;
BA_ "GenSigTimeoutTime_DMPI" SG_ 292 BPCM_ImpactHardwire 0;
BA_ "GenSigTimeoutTime_BPCM" SG_ 292 BPCM_ImpactHardwire 0;
BA_ "GenSigTimeoutTime_PBWM" SG_ 292 BPCM_ImpactHardwireV 0;
BA_ "GenSigTimeoutTime_MCPB" SG_ 292 BPCM_ImpactHardwireV 0;
BA_ "GenSigTimeoutTime_MCPA" SG_ 292 BPCM_ImpactHardwireV 0;
BA_ "GenSigTimeoutTime_IDCM" SG_ 292 BPCM_ImpactHardwireV 0;
BA_ "GenSigTimeoutTime_ECM" SG_ 292 BPCM_ImpactHardwireV 0;
BA_ "GenSigTimeoutTime_DMPI" SG_ 292 BPCM_ImpactHardwireV 0;
BA_ "GenSigTimeoutTime_BPCM" SG_ 292 BPCM_ImpactHardwireV 0;
BA_ "GenSigTimeoutTime_PBWM" SG_ 292 BPCM_HV_SOH 0;
BA_ "GenSigTimeoutTime_MCPB" SG_ 292 BPCM_HV_SOH 0;
BA_ "GenSigTimeoutTime_MCPA" SG_ 292 BPCM_HV_SOH 0;
BA_ "GenSigTimeoutTime_IDCM" SG_ 292 BPCM_HV_SOH 0;
BA_ "GenSigTimeoutTime_ECM" SG_ 292 BPCM_HV_SOH 0;
BA_ "GenSigTimeoutTime_DMPI" SG_ 292 BPCM_HV_SOH 0;
BA_ "GenSigTimeoutTime_BPCM" SG_ 292 BPCM_HV_SOH 0;
BA_ "GenSigTimeoutTime_PBWM" SG_ 292 BPCM_HV_SOH_Low 0;
BA_ "GenSigTimeoutTime_MCPB" SG_ 292 BPCM_HV_SOH_Low 0;
BA_ "GenSigTimeoutTime_MCPA" SG_ 292 BPCM_HV_SOH_Low 0;
BA_ "GenSigTimeoutTime_IDCM" SG_ 292 BPCM_HV_SOH_Low 0;
BA_ "GenSigTimeoutTime_ECM" SG_ 292 BPCM_HV_SOH_Low 0;
BA_ "GenSigTimeoutTime_DMPI" SG_ 292 BPCM_HV_SOH_Low 0;
BA_ "GenSigTimeoutTime_BPCM" SG_ 292 BPCM_HV_SOH_Low 0;
BA_ "GenSigTimeoutTime_PBWM" SG_ 292 BPCM_HV_Trac_Bus_Sts 0;
BA_ "GenSigTimeoutTime_ECM" SG_ 292 BPCM_HV_Trac_Bus_Sts 0;
BA_ "GenSigTimeoutTime_DMPI" SG_ 292 BPCM_HV_Trac_Bus_Sts 0;
BA_ "GenSigTimeoutTime_BPCM" SG_ 292 BPCM_HV_Trac_Bus_Sts 0;
BA_ "GenSigTimeoutTime_PBWM" SG_ 292 BPCM_Pwr_Limp_Home_On 0;
BA_ "GenSigTimeoutTime_MCPB" SG_ 292 BPCM_Pwr_Limp_Home_On 0;
BA_ "GenSigTimeoutTime_MCPA" SG_ 292 BPCM_Pwr_Limp_Home_On 0;
BA_ "GenSigTimeoutTime_IDCM" SG_ 292 BPCM_Pwr_Limp_Home_On 0;
BA_ "GenSigTimeoutTime_ECM" SG_ 292 BPCM_Pwr_Limp_Home_On 0;
BA_ "GenSigTimeoutTime_DMPI" SG_ 292 BPCM_Pwr_Limp_Home_On 0;
BA_ "GenSigTimeoutTime_BPCM" SG_ 292 BPCM_Pwr_Limp_Home_On 0;
BA_ "GenSigTimeoutTime_PBWM" SG_ 292 BPCM_HV_TractionBusVoltage 0;
BA_ "GenSigTimeoutTime_ECM" SG_ 292 BPCM_HV_TractionBusVoltage 0;
BA_ "GenSigTimeoutTime_BPCM" SG_ 292 BPCM_HV_TractionBusVoltage 0;
BA_ "GenSigTimeoutTime_PBWM" SG_ 292 BPCM_HV_Trac_Main_Contac_Sts 0;
BA_ "GenSigTimeoutTime_ECM" SG_ 292 BPCM_HV_Trac_Main_Contac_Sts 0;
BA_ "GenSigTimeoutTime_BPCM" SG_ 292 BPCM_HV_Trac_Main_Contac_Sts 0;
BA_ "GenSigTimeoutTime_PBWM" SG_ 292 MessageCounter_BATT_HV_STATUS1 0;
BA_ "GenSigTimeoutTime_ECM" SG_ 292 MessageCounter_BATT_HV_STATUS1 0;
BA_ "GenSigTimeoutTime_BPCM" SG_ 292 MessageCounter_BATT_HV_STATUS1 0;
BA_ "GenSigTimeoutTime_PBWM" SG_ 292 BPCM_HV_ChargingBusVoltage 0;
BA_ "GenSigTimeoutTime_MCPB" SG_ 292 BPCM_HV_ChargingBusVoltage 0;
BA_ "GenSigTimeoutTime_MCPA" SG_ 292 BPCM_HV_ChargingBusVoltage 0;
BA_ "GenSigTimeoutTime_IDCM" SG_ 292 BPCM_HV_ChargingBusVoltage 0;
BA_ "GenSigTimeoutTime_ECM" SG_ 292 BPCM_HV_ChargingBusVoltage 0;
BA_ "GenSigTimeoutTime_DMPI" SG_ 292 BPCM_HV_ChargingBusVoltage 0;
BA_ "GenSigTimeoutTime_BPCM" SG_ 292 BPCM_HV_ChargingBusVoltage 0;
BA_ "GenSigTimeoutTime_PBWM" SG_ 292 BPCM_HV_BalancingMode 0;
BA_ "GenSigTimeoutTime_MCPB" SG_ 292 BPCM_HV_BalancingMode 0;
BA_ "GenSigTimeoutTime_MCPA" SG_ 292 BPCM_HV_BalancingMode 0;
BA_ "GenSigTimeoutTime_IDCM" SG_ 292 BPCM_HV_BalancingMode 0;
BA_ "GenSigTimeoutTime_ECM" SG_ 292 BPCM_HV_BalancingMode 0;
BA_ "GenSigTimeoutTime_DMPI" SG_ 292 BPCM_HV_BalancingMode 0;
BA_ "GenSigTimeoutTime_BPCM" SG_ 292 BPCM_HV_BalancingMode 0;
BA_ "GenSigTimeoutTime_PBWM" SG_ 292 BPCM_HV_Char_Bus_Sts 0;
BA_ "GenSigTimeoutTime_MCPB" SG_ 292 BPCM_HV_Char_Bus_Sts 0;
BA_ "GenSigTimeoutTime_MCPA" SG_ 292 BPCM_HV_Char_Bus_Sts 0;
BA_ "GenSigTimeoutTime_IDCM" SG_ 292 BPCM_HV_Char_Bus_Sts 0;
BA_ "GenSigTimeoutTime_ECM" SG_ 292 BPCM_HV_Char_Bus_Sts 0;
BA_ "GenSigTimeoutTime_DMPI" SG_ 292 BPCM_HV_Char_Bus_Sts 0;
BA_ "GenSigTimeoutTime_BPCM" SG_ 292 BPCM_HV_Char_Bus_Sts 0;
BA_ "GenSigTimeoutTime_PBWM" SG_ 292 BPCM_DC_CntctrsShtTrmOpeningWarn 0;
BA_ "GenSigTimeoutTime_MCPB" SG_ 292 BPCM_DC_CntctrsShtTrmOpeningWarn 0;
BA_ "GenSigTimeoutTime_MCPA" SG_ 292 BPCM_DC_CntctrsShtTrmOpeningWarn 0;
BA_ "GenSigTimeoutTime_IDCM" SG_ 292 BPCM_DC_CntctrsShtTrmOpeningWarn 0;
BA_ "GenSigTimeoutTime_ECM" SG_ 292 BPCM_DC_CntctrsShtTrmOpeningWarn 0;
BA_ "GenSigTimeoutTime_DMPI" SG_ 292 BPCM_DC_CntctrsShtTrmOpeningWarn 0;
BA_ "GenSigTimeoutTime_BPCM" SG_ 292 BPCM_DC_CntctrsShtTrmOpeningWarn 0;
BA_ "GenSigTimeoutTime_PBWM" SG_ 292 BPCM_HV_Char_Main_Contac_Sts 0;
BA_ "GenSigTimeoutTime_MCPB" SG_ 292 BPCM_HV_Char_Main_Contac_Sts 0;
BA_ "GenSigTimeoutTime_MCPA" SG_ 292 BPCM_HV_Char_Main_Contac_Sts 0;
BA_ "GenSigTimeoutTime_IDCM" SG_ 292 BPCM_HV_Char_Main_Contac_Sts 0;
BA_ "GenSigTimeoutTime_ECM" SG_ 292 BPCM_HV_Char_Main_Contac_Sts 0;
BA_ "GenSigTimeoutTime_DMPI" SG_ 292 BPCM_HV_Char_Main_Contac_Sts 0;
BA_ "GenSigTimeoutTime_BPCM" SG_ 292 BPCM_HV_Char_Main_Contac_Sts 0;
BA_ "GenSigTimeoutTime_PBWM" SG_ 292 BPCM_DC_CntctrsMidTrmOpeningWarn 0;
BA_ "GenSigTimeoutTime_MCPB" SG_ 292 BPCM_DC_CntctrsMidTrmOpeningWarn 0;
BA_ "GenSigTimeoutTime_MCPA" SG_ 292 BPCM_DC_CntctrsMidTrmOpeningWarn 0;
BA_ "GenSigTimeoutTime_IDCM" SG_ 292 BPCM_DC_CntctrsMidTrmOpeningWarn 0;
BA_ "GenSigTimeoutTime_ECM" SG_ 292 BPCM_DC_CntctrsMidTrmOpeningWarn 0;
BA_ "GenSigTimeoutTime_DMPI" SG_ 292 BPCM_DC_CntctrsMidTrmOpeningWarn 0;
BA_ "GenSigTimeoutTime_BPCM" SG_ 292 BPCM_DC_CntctrsMidTrmOpeningWarn 0;
BA_ "GenSigTimeoutTime_PBWM" SG_ 288 BPCM_HV_HVBatChargeStat 0;
BA_ "GenSigTimeoutTime_MCPB" SG_ 288 BPCM_HV_HVBatChargeStat 0;
BA_ "GenSigTimeoutTime_MCPA" SG_ 288 BPCM_HV_HVBatChargeStat 0;
BA_ "GenSigTimeoutTime_IDCM" SG_ 288 BPCM_HV_HVBatChargeStat 0;
BA_ "GenSigTimeoutTime_ECM" SG_ 288 BPCM_HV_HVBatChargeStat 0;
BA_ "GenSigTimeoutTime_DMPI" SG_ 288 BPCM_HV_HVBatChargeStat 0;
BA_ "GenSigTimeoutTime_BPCM" SG_ 288 BPCM_HV_HVBatChargeStat 0;
BA_ "GenSigTimeoutTime_PBWM" SG_ 292 BPCM_HV_BatIntrlk_InternalStat 0;
BA_ "GenSigTimeoutTime_MCPB" SG_ 292 BPCM_HV_BatIntrlk_InternalStat 0;
BA_ "GenSigTimeoutTime_MCPA" SG_ 292 BPCM_HV_BatIntrlk_InternalStat 0;
BA_ "GenSigTimeoutTime_IDCM" SG_ 292 BPCM_HV_BatIntrlk_InternalStat 0;
BA_ "GenSigTimeoutTime_ECM" SG_ 292 BPCM_HV_BatIntrlk_InternalStat 0;
BA_ "GenSigTimeoutTime_DMPI" SG_ 292 BPCM_HV_BatIntrlk_InternalStat 0;
BA_ "GenSigTimeoutTime_BPCM" SG_ 292 BPCM_HV_BatIntrlk_InternalStat 0;
BA_ "GenSigTimeoutTime_PBWM" SG_ 292 BPCM_HV_DCFC_Isolation_Sts 0;
BA_ "GenSigTimeoutTime_MCPB" SG_ 292 BPCM_HV_DCFC_Isolation_Sts 0;
BA_ "GenSigTimeoutTime_MCPA" SG_ 292 BPCM_HV_DCFC_Isolation_Sts 0;
BA_ "GenSigTimeoutTime_IDCM" SG_ 292 BPCM_HV_DCFC_Isolation_Sts 0;
BA_ "GenSigTimeoutTime_ECM" SG_ 292 BPCM_HV_DCFC_Isolation_Sts 0;
BA_ "GenSigTimeoutTime_DMPI" SG_ 292 BPCM_HV_DCFC_Isolation_Sts 0;
BA_ "GenSigTimeoutTime_BPCM" SG_ 292 BPCM_HV_DCFC_Isolation_Sts 0;
BA_ "GenSigTimeoutTime_PBWM" SG_ 288 MessageCounter_BATT_HV_POWERLIMS 0;
BA_ "GenSigTimeoutTime_MCPB" SG_ 288 MessageCounter_BATT_HV_POWERLIMS 0;
BA_ "GenSigTimeoutTime_MCPA" SG_ 288 MessageCounter_BATT_HV_POWERLIMS 0;
BA_ "GenSigTimeoutTime_IDCM" SG_ 288 MessageCounter_BATT_HV_POWERLIMS 0;
BA_ "GenSigTimeoutTime_ECM" SG_ 288 MessageCounter_BATT_HV_POWERLIMS 0;
BA_ "GenSigTimeoutTime_DMPI" SG_ 288 MessageCounter_BATT_HV_POWERLIMS 0;
BA_ "GenSigTimeoutTime_BPCM" SG_ 288 MessageCounter_BATT_HV_POWERLIMS 0;
BA_ "GenSigTimeoutTime_PBWM" SG_ 288 CRC_BATT_HV_POWERLIMS 0;
BA_ "GenSigTimeoutTime_MCPB" SG_ 288 CRC_BATT_HV_POWERLIMS 0;
BA_ "GenSigTimeoutTime_MCPA" SG_ 288 CRC_BATT_HV_POWERLIMS 0;
BA_ "GenSigTimeoutTime_IDCM" SG_ 288 CRC_BATT_HV_POWERLIMS 0;
BA_ "GenSigTimeoutTime_ECM" SG_ 288 CRC_BATT_HV_POWERLIMS 0;
BA_ "GenSigTimeoutTime_DMPI" SG_ 288 CRC_BATT_HV_POWERLIMS 0;
BA_ "GenSigTimeoutTime_BPCM" SG_ 288 CRC_BATT_HV_POWERLIMS 0;
BA_ "GenSigTimeoutTime_PBWM" SG_ 292 BPCM_HV_InternalVoltage 0;
BA_ "GenSigTimeoutTime_MCPB" SG_ 292 BPCM_HV_InternalVoltage 0;
BA_ "GenSigTimeoutTime_MCPA" SG_ 292 BPCM_HV_InternalVoltage 0;
BA_ "GenSigTimeoutTime_IDCM" SG_ 292 BPCM_HV_InternalVoltage 0;
BA_ "GenSigTimeoutTime_ECM" SG_ 292 BPCM_HV_InternalVoltage 0;
BA_ "GenSigTimeoutTime_BPCM" SG_ 292 BPCM_HV_InternalVoltage 0;
BA_ "GenSigTimeoutTime_PBWM" SG_ 292 BPCM_HV_Outlet_Temp 0;
BA_ "GenSigTimeoutTime_MCPB" SG_ 292 BPCM_HV_Outlet_Temp 0;
BA_ "GenSigTimeoutTime_MCPA" SG_ 292 BPCM_HV_Outlet_Temp 0;
BA_ "GenSigTimeoutTime_IDCM" SG_ 292 BPCM_HV_Outlet_Temp 0;
BA_ "GenSigTimeoutTime_ECM" SG_ 292 BPCM_HV_Outlet_Temp 0;
BA_ "GenSigTimeoutTime_DMPI" SG_ 292 BPCM_HV_Outlet_Temp 0;
BA_ "GenSigTimeoutTime_BPCM" SG_ 292 BPCM_HV_Outlet_Temp 0;
BA_ "GenSigStartValue" SG_ 292 BPCM_HV_Outlet_Temp 40;
BA_ "GenSigTimeoutTime_PBWM" SG_ 292 BPCM_HV_Battery_GFD_Sts 0;
BA_ "GenSigTimeoutTime_MCPB" SG_ 292 BPCM_HV_Battery_GFD_Sts 0;
BA_ "GenSigTimeoutTime_MCPA" SG_ 292 BPCM_HV_Battery_GFD_Sts 0;
BA_ "GenSigTimeoutTime_IDCM" SG_ 292 BPCM_HV_Battery_GFD_Sts 0;
BA_ "GenSigTimeoutTime_ECM" SG_ 292 BPCM_HV_Battery_GFD_Sts 0;
BA_ "GenSigTimeoutTime_DMPI" SG_ 292 BPCM_HV_Battery_GFD_Sts 0;
BA_ "GenSigTimeoutTime_BPCM" SG_ 292 BPCM_HV_Battery_GFD_Sts 0;
BA_ "GenSigTimeoutTime_PBWM" SG_ 292 BPCM_HV_Capacity 0;
BA_ "GenSigTimeoutTime_MCPB" SG_ 292 BPCM_HV_Capacity 0;
BA_ "GenSigTimeoutTime_MCPA" SG_ 292 BPCM_HV_Capacity 0;
BA_ "GenSigTimeoutTime_IDCM" SG_ 292 BPCM_HV_Capacity 0;
BA_ "GenSigTimeoutTime_ECM" SG_ 292 BPCM_HV_Capacity 0;
BA_ "GenSigTimeoutTime_DMPI" SG_ 292 BPCM_HV_Capacity 0;
BA_ "GenSigTimeoutTime_BPCM" SG_ 292 BPCM_HV_Capacity 0;
BA_ "GenSigTimeoutTime_PBWM" SG_ 292 BPCM_HV_Current 0;
BA_ "GenSigTimeoutTime_MCPB" SG_ 292 BPCM_HV_Current 0;
BA_ "GenSigTimeoutTime_MCPA" SG_ 292 BPCM_HV_Current 0;
BA_ "GenSigTimeoutTime_IDCM" SG_ 292 BPCM_HV_Current 0;
BA_ "GenSigTimeoutTime_ECM" SG_ 292 BPCM_HV_Current 0;
BA_ "GenSigTimeoutTime_BPCM" SG_ 292 BPCM_HV_Current 0;
BA_ "GenSigTimeoutTime_PBWM" SG_ 292 BPCM_HV_Inlet_Temp 0;
BA_ "GenSigTimeoutTime_MCPB" SG_ 292 BPCM_HV_Inlet_Temp 0;
BA_ "GenSigTimeoutTime_MCPA" SG_ 292 BPCM_HV_Inlet_Temp 0;
BA_ "GenSigTimeoutTime_IDCM" SG_ 292 BPCM_HV_Inlet_Temp 0;
BA_ "GenSigTimeoutTime_ECM" SG_ 292 BPCM_HV_Inlet_Temp 0;
BA_ "GenSigTimeoutTime_DMPI" SG_ 292 BPCM_HV_Inlet_Temp 0;
BA_ "GenSigTimeoutTime_BPCM" SG_ 292 BPCM_HV_Inlet_Temp 0;
BA_ "GenSigStartValue" SG_ 292 BPCM_HV_Inlet_Temp 40;
BA_ "GenSigTimeoutTime_PBWM" SG_ 288 BPCM_HV_Cell_MaxDischrg_Imped 0;
BA_ "GenSigTimeoutTime_MCPB" SG_ 288 BPCM_HV_Cell_MaxDischrg_Imped 0;
BA_ "GenSigTimeoutTime_MCPA" SG_ 288 BPCM_HV_Cell_MaxDischrg_Imped 0;
BA_ "GenSigTimeoutTime_IDCM" SG_ 288 BPCM_HV_Cell_MaxDischrg_Imped 0;
BA_ "GenSigTimeoutTime_ECM" SG_ 288 BPCM_HV_Cell_MaxDischrg_Imped 0;
BA_ "GenSigTimeoutTime_DMPI" SG_ 288 BPCM_HV_Cell_MaxDischrg_Imped 0;
BA_ "GenSigTimeoutTime_PBWM" SG_ 288 BPCM_HV_Cell_MinDischrg_Imped 0;
BA_ "GenSigTimeoutTime_MCPB" SG_ 288 BPCM_HV_Cell_MinDischrg_Imped 0;
BA_ "GenSigTimeoutTime_MCPA" SG_ 288 BPCM_HV_Cell_MinDischrg_Imped 0;
BA_ "GenSigTimeoutTime_IDCM" SG_ 288 BPCM_HV_Cell_MinDischrg_Imped 0;
BA_ "GenSigTimeoutTime_ECM" SG_ 288 BPCM_HV_Cell_MinDischrg_Imped 0;
BA_ "GenSigTimeoutTime_DMPI" SG_ 288 BPCM_HV_Cell_MinDischrg_Imped 0;
BA_ "GenSigTimeoutTime_BPCM" SG_ 288 BPCM_HV_Cell_MinDischrg_Imped 0;
BA_ "GenSigTimeoutTime_PBWM" SG_ 288 BPCM_HV_ChargingCurrentProfile 0;
BA_ "GenSigTimeoutTime_MCPB" SG_ 288 BPCM_HV_ChargingCurrentProfile 0;
BA_ "GenSigTimeoutTime_MCPA" SG_ 288 BPCM_HV_ChargingCurrentProfile 0;
BA_ "GenSigTimeoutTime_IDCM" SG_ 288 BPCM_HV_ChargingCurrentProfile 0;
BA_ "GenSigTimeoutTime_ECM" SG_ 288 BPCM_HV_ChargingCurrentProfile 0;
BA_ "GenSigTimeoutTime_DMPI" SG_ 288 BPCM_HV_ChargingCurrentProfile 0;
BA_ "GenSigTimeoutTime_BPCM" SG_ 288 BPCM_HV_ChargingCurrentProfile 0;
BA_ "GenSigTimeoutTime_PBWM" SG_ 288 BPCM_HV_CrntLmtInstChrg 0;
BA_ "GenSigTimeoutTime_MCPB" SG_ 288 BPCM_HV_CrntLmtInstChrg 0;
BA_ "GenSigTimeoutTime_MCPA" SG_ 288 BPCM_HV_CrntLmtInstChrg 0;
BA_ "GenSigTimeoutTime_IDCM" SG_ 288 BPCM_HV_CrntLmtInstChrg 0;
BA_ "GenSigTimeoutTime_ECM" SG_ 288 BPCM_HV_CrntLmtInstChrg 0;
BA_ "GenSigTimeoutTime_DMPI" SG_ 288 BPCM_HV_CrntLmtInstChrg 0;
BA_ "GenSigTimeoutTime_BPCM" SG_ 288 BPCM_HV_CrntLmtInstChrg 0;
BA_ "GenSigTimeoutTime_BPCM" SG_ 288 BPCM_HV_CrntLmtInstDschg 0;
BA_ "GenSigTimeoutTime_PBWM" SG_ 288 BPCM_HV_CrntLmtInstDschg 0;
BA_ "GenSigTimeoutTime_MCPB" SG_ 288 BPCM_HV_CrntLmtInstDschg 0;
BA_ "GenSigTimeoutTime_MCPA" SG_ 288 BPCM_HV_CrntLmtInstDschg 0;
BA_ "GenSigTimeoutTime_IDCM" SG_ 288 BPCM_HV_CrntLmtInstDschg 0;
BA_ "GenSigTimeoutTime_ECM" SG_ 288 BPCM_HV_CrntLmtInstDschg 0;
BA_ "GenSigTimeoutTime_DMPI" SG_ 288 BPCM_HV_CrntLmtInstDschg 0;
BA_ "GenSigTimeoutTime_PBWM" SG_ 288 BPCM_HV_Power_MaxCharge_LgTrm 0;
BA_ "GenSigTimeoutTime_MCPB" SG_ 288 BPCM_HV_Power_MaxCharge_LgTrm 0;
BA_ "GenSigTimeoutTime_MCPA" SG_ 288 BPCM_HV_Power_MaxCharge_LgTrm 0;
BA_ "GenSigTimeoutTime_IDCM" SG_ 288 BPCM_HV_Power_MaxCharge_LgTrm 0;
BA_ "GenSigTimeoutTime_ECM" SG_ 288 BPCM_HV_Power_MaxCharge_LgTrm 0;
BA_ "GenSigTimeoutTime_DMPI" SG_ 288 BPCM_HV_Power_MaxCharge_LgTrm 0;
BA_ "GenSigTimeoutTime_BPCM" SG_ 288 BPCM_HV_Power_MaxCharge_LgTrm 0;
BA_ "GenSigTimeoutTime_PBWM" SG_ 288 BPCM_HV_Power_MaxCharge_MdTrm 0;
BA_ "GenSigTimeoutTime_MCPB" SG_ 288 BPCM_HV_Power_MaxCharge_MdTrm 0;
BA_ "GenSigTimeoutTime_MCPA" SG_ 288 BPCM_HV_Power_MaxCharge_MdTrm 0;
BA_ "GenSigTimeoutTime_IDCM" SG_ 288 BPCM_HV_Power_MaxCharge_MdTrm 0;
BA_ "GenSigTimeoutTime_ECM" SG_ 288 BPCM_HV_Power_MaxCharge_MdTrm 0;
BA_ "GenSigTimeoutTime_DMPI" SG_ 288 BPCM_HV_Power_MaxCharge_MdTrm 0;
BA_ "GenSigTimeoutTime_BPCM" SG_ 288 BPCM_HV_Power_MaxCharge_MdTrm 0;
BA_ "GenSigTimeoutTime_PBWM" SG_ 288 BPCM_HV_Power_MaxCharge_ShrTrm 0;
BA_ "GenSigTimeoutTime_MCPB" SG_ 288 BPCM_HV_Power_MaxCharge_ShrTrm 0;
BA_ "GenSigTimeoutTime_MCPA" SG_ 288 BPCM_HV_Power_MaxCharge_ShrTrm 0;
BA_ "GenSigTimeoutTime_IDCM" SG_ 288 BPCM_HV_Power_MaxCharge_ShrTrm 0;
BA_ "GenSigTimeoutTime_ECM" SG_ 288 BPCM_HV_Power_MaxCharge_ShrTrm 0;
BA_ "GenSigTimeoutTime_DMPI" SG_ 288 BPCM_HV_Power_MaxCharge_ShrTrm 0;
BA_ "GenSigTimeoutTime_BPCM" SG_ 288 BPCM_HV_Power_MaxCharge_ShrTrm 0;
BA_ "GenSigTimeoutTime_PBWM" SG_ 288 BPCM_HV_Power_MaxDischarge_LgTrm 0;
BA_ "GenSigTimeoutTime_MCPB" SG_ 288 BPCM_HV_Power_MaxDischarge_LgTrm 0;
BA_ "GenSigTimeoutTime_MCPA" SG_ 288 BPCM_HV_Power_MaxDischarge_LgTrm 0;
BA_ "GenSigTimeoutTime_IDCM" SG_ 288 BPCM_HV_Power_MaxDischarge_LgTrm 0;
BA_ "GenSigTimeoutTime_ECM" SG_ 288 BPCM_HV_Power_MaxDischarge_LgTrm 0;
BA_ "GenSigTimeoutTime_DMPI" SG_ 288 BPCM_HV_Power_MaxDischarge_LgTrm 0;
BA_ "GenSigTimeoutTime_BPCM" SG_ 288 BPCM_HV_Power_MaxDischarge_LgTrm 0;
BA_ "GenSigTimeoutTime_PBWM" SG_ 288 BPCM_HV_Power_MaxDischarge_MdTrm 0;
BA_ "GenSigTimeoutTime_MCPB" SG_ 288 BPCM_HV_Power_MaxDischarge_MdTrm 0;
BA_ "GenSigTimeoutTime_MCPA" SG_ 288 BPCM_HV_Power_MaxDischarge_MdTrm 0;
BA_ "GenSigTimeoutTime_IDCM" SG_ 288 BPCM_HV_Power_MaxDischarge_MdTrm 0;
BA_ "GenSigTimeoutTime_ECM" SG_ 288 BPCM_HV_Power_MaxDischarge_MdTrm 0;
BA_ "GenSigTimeoutTime_DMPI" SG_ 288 BPCM_HV_Power_MaxDischarge_MdTrm 0;
BA_ "GenSigTimeoutTime_BPCM" SG_ 288 BPCM_HV_Power_MaxDischarge_MdTrm 0;
BA_ "GenSigTimeoutTime_PBWM" SG_ 288 BPCM_HV_Pwr_MaxDischrg_ShrTrm 0;
BA_ "GenSigTimeoutTime_MCPB" SG_ 288 BPCM_HV_Pwr_MaxDischrg_ShrTrm 0;
BA_ "GenSigTimeoutTime_MCPA" SG_ 288 BPCM_HV_Pwr_MaxDischrg_ShrTrm 0;
BA_ "GenSigTimeoutTime_IDCM" SG_ 288 BPCM_HV_Pwr_MaxDischrg_ShrTrm 0;
BA_ "GenSigTimeoutTime_ECM" SG_ 288 BPCM_HV_Pwr_MaxDischrg_ShrTrm 0;
BA_ "GenSigTimeoutTime_BPCM" SG_ 288 BPCM_HV_Pwr_MaxDischrg_ShrTrm 0;
BA_ "GenSigTimeoutTime_PBWM" SG_ 288 BPCM_HV_PwrLmtInstChrg 0;
BA_ "GenSigTimeoutTime_MCPB" SG_ 288 BPCM_HV_PwrLmtInstChrg 0;
BA_ "GenSigTimeoutTime_MCPA" SG_ 288 BPCM_HV_PwrLmtInstChrg 0;
BA_ "GenSigTimeoutTime_IDCM" SG_ 288 BPCM_HV_PwrLmtInstChrg 0;
BA_ "GenSigTimeoutTime_ECM" SG_ 288 BPCM_HV_PwrLmtInstChrg 0;
BA_ "GenSigTimeoutTime_DMPI" SG_ 288 BPCM_HV_PwrLmtInstChrg 0;
BA_ "GenSigTimeoutTime_BPCM" SG_ 288 BPCM_HV_PwrLmtInstChrg 0;
BA_ "GenSigTimeoutTime_PBWM" SG_ 288 BPCM_HV_PwrLmtInstDschg 0;
BA_ "GenSigTimeoutTime_MCPB" SG_ 288 BPCM_HV_PwrLmtInstDschg 0;
BA_ "GenSigTimeoutTime_MCPA" SG_ 288 BPCM_HV_PwrLmtInstDschg 0;
BA_ "GenSigTimeoutTime_IDCM" SG_ 288 BPCM_HV_PwrLmtInstDschg 0;
BA_ "GenSigTimeoutTime_ECM" SG_ 288 BPCM_HV_PwrLmtInstDschg 0;
BA_ "GenSigTimeoutTime_DMPI" SG_ 288 BPCM_HV_PwrLmtInstDschg 0;
BA_ "GenSigTimeoutTime_BPCM" SG_ 288 BPCM_HV_PwrLmtInstDschg 0;
BA_ "GenSigTimeoutTime_BPCM" SG_ 288 BPCM_HV_Cell_MaxDischrg_Imped 0;
BA_ "GenSigTimeoutTime_PBWM" SG_ 288 BPCM_CntctrsShtTrmOpeningWarn 0;
BA_ "GenSigTimeoutTime_MCPB" SG_ 288 BPCM_CntctrsShtTrmOpeningWarn 0;
BA_ "GenSigTimeoutTime_MCPA" SG_ 288 BPCM_CntctrsShtTrmOpeningWarn 0;
BA_ "GenSigTimeoutTime_ECM" SG_ 288 BPCM_CntctrsShtTrmOpeningWarn 0;
BA_ "GenSigTimeoutTime_BPCM" SG_ 288 BPCM_CntctrsShtTrmOpeningWarn 0;
BA_ "GenSigTimeoutTime_PBWM" SG_ 288 BPCM_CntctrsMidTrmOpeningWarn 0;
BA_ "GenSigTimeoutTime_MCPB" SG_ 288 BPCM_CntctrsMidTrmOpeningWarn 0;
BA_ "GenSigTimeoutTime_MCPA" SG_ 288 BPCM_CntctrsMidTrmOpeningWarn 0;
BA_ "GenSigTimeoutTime_IDCM" SG_ 288 BPCM_CntctrsMidTrmOpeningWarn 0;
BA_ "GenSigTimeoutTime_ECM" SG_ 288 BPCM_CntctrsMidTrmOpeningWarn 0;
BA_ "GenSigTimeoutTime_DMPI" SG_ 288 BPCM_CntctrsMidTrmOpeningWarn 0;
BA_ "GenSigTimeoutTime_BPCM" SG_ 288 BPCM_CntctrsMidTrmOpeningWarn 0;
BA_ "GenSigTimeoutTime_PBWM" SG_ 211 PIM_A_AccelRaw 0;
BA_ "GenSigTimeoutTime_MCPB" SG_ 211 PIM_A_AccelRaw 0;
BA_ "GenSigTimeoutTime_MCPA" SG_ 211 PIM_A_AccelRaw 0;
BA_ "GenSigTimeoutTime_IDCM" SG_ 211 PIM_A_AccelRaw 0;
BA_ "GenSigTimeoutTime_ECM" SG_ 211 PIM_A_AccelRaw 0;
BA_ "GenSigTimeoutTime_DMPI" SG_ 211 PIM_A_AccelRaw 0;
BA_ "GenSigTimeoutTime_BPCM" SG_ 211 PIM_A_AccelRaw 0;
BA_ "GenSigStartValue" SG_ 211 PIM_A_AccelRaw 32768;
BA_ "GenSigTimeoutTime_PBWM" SG_ 211 PIM_A_6SO_Status 0;
BA_ "GenSigTimeoutTime_MCPB" SG_ 211 PIM_A_6SO_Status 0;
BA_ "GenSigTimeoutTime_MCPA" SG_ 211 PIM_A_6SO_Status 0;
BA_ "GenSigTimeoutTime_IDCM" SG_ 211 PIM_A_6SO_Status 0;
BA_ "GenSigTimeoutTime_ECM" SG_ 211 PIM_A_6SO_Status 0;
BA_ "GenSigTimeoutTime_DMPI" SG_ 211 PIM_A_6SO_Status 0;
BA_ "GenSigTimeoutTime_BPCM" SG_ 211 PIM_A_6SO_Status 0;
BA_ "GenSigTimeoutTime_PBWM" SG_ 211 PIM_A_AccelRawV 0;
BA_ "GenSigTimeoutTime_MCPB" SG_ 211 PIM_A_AccelRawV 0;
BA_ "GenSigTimeoutTime_MCPA" SG_ 211 PIM_A_AccelRawV 0;
BA_ "GenSigTimeoutTime_IDCM" SG_ 211 PIM_A_AccelRawV 0;
BA_ "GenSigTimeoutTime_ECM" SG_ 211 PIM_A_AccelRawV 0;
BA_ "GenSigTimeoutTime_DMPI" SG_ 211 PIM_A_AccelRawV 0;
BA_ "GenSigTimeoutTime_BPCM" SG_ 211 PIM_A_AccelRawV 0;
BA_ "GenSigTimeoutTime_PBWM" SG_ 211 PIM_A_CoolantTemp 0;
BA_ "GenSigTimeoutTime_MCPB" SG_ 211 PIM_A_CoolantTemp 0;
BA_ "GenSigTimeoutTime_MCPA" SG_ 211 PIM_A_CoolantTemp 0;
BA_ "GenSigTimeoutTime_IDCM" SG_ 211 PIM_A_CoolantTemp 0;
BA_ "GenSigTimeoutTime_ECM" SG_ 211 PIM_A_CoolantTemp 0;
BA_ "GenSigTimeoutTime_DMPI" SG_ 211 PIM_A_CoolantTemp 0;
BA_ "GenSigTimeoutTime_BPCM" SG_ 211 PIM_A_CoolantTemp 0;
BA_ "GenSigTimeoutTime_PBWM" SG_ 211 PIM_A_CpbltySpdDivVolt 0;
BA_ "GenSigTimeoutTime_MCPB" SG_ 211 PIM_A_CpbltySpdDivVolt 0;
BA_ "GenSigTimeoutTime_MCPA" SG_ 211 PIM_A_CpbltySpdDivVolt 0;
BA_ "GenSigTimeoutTime_IDCM" SG_ 211 PIM_A_CpbltySpdDivVolt 0;
BA_ "GenSigTimeoutTime_ECM" SG_ 211 PIM_A_CpbltySpdDivVolt 0;
BA_ "GenSigTimeoutTime_DMPI" SG_ 211 PIM_A_CpbltySpdDivVolt 0;
BA_ "GenSigTimeoutTime_BPCM" SG_ 211 PIM_A_CpbltySpdDivVolt 0;
BA_ "GenSigTimeoutTime_PBWM" SG_ 211 PIM_A_DC_Current 0;
BA_ "GenSigTimeoutTime_MCPB" SG_ 211 PIM_A_DC_Current 0;
BA_ "GenSigTimeoutTime_MCPA" SG_ 211 PIM_A_DC_Current 0;
BA_ "GenSigTimeoutTime_IDCM" SG_ 211 PIM_A_DC_Current 0;
BA_ "GenSigTimeoutTime_ECM" SG_ 211 PIM_A_DC_Current 0;
BA_ "GenSigTimeoutTime_DMPI" SG_ 211 PIM_A_DC_Current 0;
BA_ "GenSigStartValue" SG_ 211 PIM_A_DC_Current 16384;
BA_ "GenSigTimeoutTime_PBWM" SG_ 211 PIM_A_DC_Current_V 0;
BA_ "GenSigTimeoutTime_MCPB" SG_ 211 PIM_A_DC_Current_V 0;
BA_ "GenSigTimeoutTime_MCPA" SG_ 211 PIM_A_DC_Current_V 0;
BA_ "GenSigTimeoutTime_IDCM" SG_ 211 PIM_A_DC_Current_V 0;
BA_ "GenSigTimeoutTime_ECM" SG_ 211 PIM_A_DC_Current_V 0;
BA_ "GenSigTimeoutTime_DMPI" SG_ 211 PIM_A_DC_Current_V 0;
BA_ "GenSigTimeoutTime_BPCM" SG_ 211 PIM_A_DC_Current_V 0;
BA_ "GenSigTimeoutTime_PBWM" SG_ 211 PIM_A_DC_Volt_V 0;
BA_ "GenSigTimeoutTime_MCPB" SG_ 211 PIM_A_DC_Volt_V 0;
BA_ "GenSigTimeoutTime_MCPA" SG_ 211 PIM_A_DC_Volt_V 0;
BA_ "GenSigTimeoutTime_IDCM" SG_ 211 PIM_A_DC_Volt_V 0;
BA_ "GenSigTimeoutTime_ECM" SG_ 211 PIM_A_DC_Volt_V 0;
BA_ "GenSigTimeoutTime_DMPI" SG_ 211 PIM_A_DC_Volt_V 0;
BA_ "GenSigTimeoutTime_BPCM" SG_ 211 PIM_A_DC_Volt_V 0;
BA_ "GenSigTimeoutTime_PBWM" SG_ 211 PIM_A_DC_Voltage 0;
BA_ "GenSigTimeoutTime_MCPB" SG_ 211 PIM_A_DC_Voltage 0;
BA_ "GenSigTimeoutTime_MCPA" SG_ 211 PIM_A_DC_Voltage 0;
BA_ "GenSigTimeoutTime_IDCM" SG_ 211 PIM_A_DC_Voltage 0;
BA_ "GenSigTimeoutTime_ECM" SG_ 211 PIM_A_DC_Voltage 0;
BA_ "GenSigTimeoutTime_DMPI" SG_ 211 PIM_A_DC_Voltage 0;
BA_ "GenSigTimeoutTime_BPCM" SG_ 211 PIM_A_DC_Voltage 0;
BA_ "GenSigTimeoutTime_PBWM" SG_ 211 PIM_A_DerateReason 0;
BA_ "GenSigTimeoutTime_MCPB" SG_ 211 PIM_A_DerateReason 0;
BA_ "GenSigTimeoutTime_MCPA" SG_ 211 PIM_A_DerateReason 0;
BA_ "GenSigTimeoutTime_IDCM" SG_ 211 PIM_A_DerateReason 0;
BA_ "GenSigTimeoutTime_ECM" SG_ 211 PIM_A_DerateReason 0;
BA_ "GenSigTimeoutTime_DMPI" SG_ 211 PIM_A_DerateReason 0;
BA_ "GenSigTimeoutTime_BPCM" SG_ 211 PIM_A_DerateReason 0;
BA_ "GenSigTimeoutTime_PBWM" SG_ 211 PIM_A_DeratingFactor 0;
BA_ "GenSigTimeoutTime_MCPB" SG_ 211 PIM_A_DeratingFactor 0;
BA_ "GenSigTimeoutTime_MCPA" SG_ 211 PIM_A_DeratingFactor 0;
BA_ "GenSigTimeoutTime_IDCM" SG_ 211 PIM_A_DeratingFactor 0;
BA_ "GenSigTimeoutTime_ECM" SG_ 211 PIM_A_DeratingFactor 0;
BA_ "GenSigTimeoutTime_DMPI" SG_ 211 PIM_A_DeratingFactor 0;
BA_ "GenSigTimeoutTime_BPCM" SG_ 211 PIM_A_DeratingFactor 0;
BA_ "GenSigTimeoutTime_PBWM" SG_ 211 PIM_A_Dschrge_Status 0;
BA_ "GenSigTimeoutTime_MCPB" SG_ 211 PIM_A_Dschrge_Status 0;
BA_ "GenSigTimeoutTime_MCPA" SG_ 211 PIM_A_Dschrge_Status 0;
BA_ "GenSigTimeoutTime_IDCM" SG_ 211 PIM_A_Dschrge_Status 0;
BA_ "GenSigTimeoutTime_ECM" SG_ 211 PIM_A_Dschrge_Status 0;
BA_ "GenSigTimeoutTime_DMPI" SG_ 211 PIM_A_Dschrge_Status 0;
BA_ "GenSigTimeoutTime_BPCM" SG_ 211 PIM_A_Dschrge_Status 0;
BA_ "GenSigTimeoutTime_PBWM" SG_ 211 PIM_A_HV_CnctrOpn_Req 0;
BA_ "GenSigTimeoutTime_MCPB" SG_ 211 PIM_A_HV_CnctrOpn_Req 0;
BA_ "GenSigTimeoutTime_MCPA" SG_ 211 PIM_A_HV_CnctrOpn_Req 0;
BA_ "GenSigTimeoutTime_IDCM" SG_ 211 PIM_A_HV_CnctrOpn_Req 0;
BA_ "GenSigTimeoutTime_ECM" SG_ 211 PIM_A_HV_CnctrOpn_Req 0;
BA_ "GenSigTimeoutTime_DMPI" SG_ 211 PIM_A_HV_CnctrOpn_Req 0;
BA_ "GenSigTimeoutTime_BPCM" SG_ 211 PIM_A_HV_CnctrOpn_Req 0;
BA_ "GenSigTimeoutTime_PBWM" SG_ 211 PIM_A_InterlockSts 0;
BA_ "GenSigTimeoutTime_MCPB" SG_ 211 PIM_A_InterlockSts 0;
BA_ "GenSigTimeoutTime_MCPA" SG_ 211 PIM_A_InterlockSts 0;
BA_ "GenSigTimeoutTime_IDCM" SG_ 211 PIM_A_InterlockSts 0;
BA_ "GenSigTimeoutTime_ECM" SG_ 211 PIM_A_InterlockSts 0;
BA_ "GenSigTimeoutTime_DMPI" SG_ 211 PIM_A_InterlockSts 0;
BA_ "GenSigTimeoutTime_BPCM" SG_ 211 PIM_A_InterlockSts 0;
BA_ "GenSigTimeoutTime_PBWM" SG_ 211 PIM_A_Invrtr_State 0;
BA_ "GenSigTimeoutTime_MCPB" SG_ 211 PIM_A_Invrtr_State 0;
BA_ "GenSigTimeoutTime_MCPA" SG_ 211 PIM_A_Invrtr_State 0;
BA_ "GenSigTimeoutTime_IDCM" SG_ 211 PIM_A_Invrtr_State 0;
BA_ "GenSigTimeoutTime_ECM" SG_ 211 PIM_A_Invrtr_State 0;
BA_ "GenSigTimeoutTime_DMPI" SG_ 211 PIM_A_Invrtr_State 0;
BA_ "GenSigTimeoutTime_BPCM" SG_ 211 PIM_A_Invrtr_State 0;
BA_ "GenSigTimeoutTime_PBWM" SG_ 211 PIM_A_MaxTorq 0;
BA_ "GenSigTimeoutTime_MCPB" SG_ 211 PIM_A_MaxTorq 0;
BA_ "GenSigTimeoutTime_MCPA" SG_ 211 PIM_A_MaxTorq 0;
BA_ "GenSigTimeoutTime_IDCM" SG_ 211 PIM_A_MaxTorq 0;
BA_ "GenSigTimeoutTime_ECM" SG_ 211 PIM_A_MaxTorq 0;
BA_ "GenSigTimeoutTime_DMPI" SG_ 211 PIM_A_MaxTorq 0;
BA_ "GenSigTimeoutTime_BPCM" SG_ 211 PIM_A_MaxTorq 0;
BA_ "GenSigStartValue" SG_ 211 PIM_A_MaxTorq 4096;
BA_ "GenSigTimeoutTime_PBWM" SG_ 211 PIM_A_MinTorq 0;
BA_ "GenSigTimeoutTime_MCPB" SG_ 211 PIM_A_MinTorq 0;
BA_ "GenSigTimeoutTime_MCPA" SG_ 211 PIM_A_MinTorq 0;
BA_ "GenSigTimeoutTime_IDCM" SG_ 211 PIM_A_MinTorq 0;
BA_ "GenSigTimeoutTime_ECM" SG_ 211 PIM_A_MinTorq 0;
BA_ "GenSigTimeoutTime_DMPI" SG_ 211 PIM_A_MinTorq 0;
BA_ "GenSigTimeoutTime_BPCM" SG_ 211 PIM_A_MinTorq 0;
BA_ "GenSigStartValue" SG_ 211 PIM_A_MinTorq 4096;
BA_ "GenSigTimeoutTime_PBWM" SG_ 211 PIM_A_MtrIndex 0;
BA_ "GenSigTimeoutTime_MCPB" SG_ 211 PIM_A_MtrIndex 0;
BA_ "GenSigTimeoutTime_MCPA" SG_ 211 PIM_A_MtrIndex 0;
BA_ "GenSigTimeoutTime_IDCM" SG_ 211 PIM_A_MtrIndex 0;
BA_ "GenSigTimeoutTime_ECM" SG_ 211 PIM_A_MtrIndex 0;
BA_ "GenSigTimeoutTime_DMPI" SG_ 211 PIM_A_MtrIndex 0;
BA_ "GenSigTimeoutTime_BPCM" SG_ 211 PIM_A_MtrIndex 0;
BA_ "GenSigTimeoutTime_PBWM" SG_ 211 PIM_A_MtrMaxCpbltyTrq 0;
BA_ "GenSigTimeoutTime_MCPB" SG_ 211 PIM_A_MtrMaxCpbltyTrq 0;
BA_ "GenSigTimeoutTime_MCPA" SG_ 211 PIM_A_MtrMaxCpbltyTrq 0;
BA_ "GenSigTimeoutTime_IDCM" SG_ 211 PIM_A_MtrMaxCpbltyTrq 0;
BA_ "GenSigTimeoutTime_ECM" SG_ 211 PIM_A_MtrMaxCpbltyTrq 0;
BA_ "GenSigTimeoutTime_DMPI" SG_ 211 PIM_A_MtrMaxCpbltyTrq 0;
BA_ "GenSigTimeoutTime_BPCM" SG_ 211 PIM_A_MtrMaxCpbltyTrq 0;
BA_ "GenSigStartValue" SG_ 211 PIM_A_MtrMaxCpbltyTrq 4096;
BA_ "GenSigTimeoutTime_PBWM" SG_ 211 PIM_A_MtrMinCpbltyTrq 0;
BA_ "GenSigTimeoutTime_MCPB" SG_ 211 PIM_A_MtrMinCpbltyTrq 0;
BA_ "GenSigTimeoutTime_MCPA" SG_ 211 PIM_A_MtrMinCpbltyTrq 0;
BA_ "GenSigTimeoutTime_IDCM" SG_ 211 PIM_A_MtrMinCpbltyTrq 0;
BA_ "GenSigTimeoutTime_ECM" SG_ 211 PIM_A_MtrMinCpbltyTrq 0;
BA_ "GenSigTimeoutTime_DMPI" SG_ 211 PIM_A_MtrMinCpbltyTrq 0;
BA_ "GenSigTimeoutTime_BPCM" SG_ 211 PIM_A_MtrMinCpbltyTrq 0;
BA_ "GenSigStartValue" SG_ 211 PIM_A_MtrMinCpbltyTrq 4096;
BA_ "GenSigTimeoutTime_PBWM" SG_ 212 CRC_PIM_B 0;
BA_ "GenSigTimeoutTime_MCPB" SG_ 212 CRC_PIM_B 0;
BA_ "GenSigTimeoutTime_MCPA" SG_ 212 CRC_PIM_B 0;
BA_ "GenSigTimeoutTime_IDCM" SG_ 212 CRC_PIM_B 0;
BA_ "GenSigTimeoutTime_ECM" SG_ 212 CRC_PIM_B 0;
BA_ "GenSigTimeoutTime_DMPI" SG_ 212 CRC_PIM_B 0;
BA_ "GenSigTimeoutTime_BPCM" SG_ 212 CRC_PIM_B 0;
BA_ "GenSigTimeoutTime_PBWM" SG_ 211 PIM_A_RPM 0;
BA_ "GenSigTimeoutTime_MCPB" SG_ 211 PIM_A_RPM 0;
BA_ "GenSigTimeoutTime_MCPA" SG_ 211 PIM_A_RPM 0;
BA_ "GenSigTimeoutTime_IDCM" SG_ 211 PIM_A_RPM 0;
BA_ "GenSigTimeoutTime_ECM" SG_ 211 PIM_A_RPM 0;
BA_ "GenSigTimeoutTime_DMPI" SG_ 211 PIM_A_RPM 0;
BA_ "GenSigTimeoutTime_BPCM" SG_ 211 PIM_A_RPM 0;
BA_ "GenSigStartValue" SG_ 211 PIM_A_RPM 32768;
BA_ "GenSigTimeoutTime_PBWM" SG_ 211 PIM_A_RPM_V 0;
BA_ "GenSigTimeoutTime_MCPB" SG_ 211 PIM_A_RPM_V 0;
BA_ "GenSigTimeoutTime_MCPA" SG_ 211 PIM_A_RPM_V 0;
BA_ "GenSigTimeoutTime_IDCM" SG_ 211 PIM_A_RPM_V 0;
BA_ "GenSigTimeoutTime_ECM" SG_ 211 PIM_A_RPM_V 0;
BA_ "GenSigTimeoutTime_DMPI" SG_ 211 PIM_A_RPM_V 0;
BA_ "GenSigTimeoutTime_BPCM" SG_ 211 PIM_A_RPM_V 0;
BA_ "GenSigTimeoutTime_PBWM" SG_ 211 PIM_A_Spd_Lim 0;
BA_ "GenSigTimeoutTime_MCPB" SG_ 211 PIM_A_Spd_Lim 0;
BA_ "GenSigTimeoutTime_MCPA" SG_ 211 PIM_A_Spd_Lim 0;
BA_ "GenSigTimeoutTime_IDCM" SG_ 211 PIM_A_Spd_Lim 0;
BA_ "GenSigTimeoutTime_ECM" SG_ 211 PIM_A_Spd_Lim 0;
BA_ "GenSigTimeoutTime_DMPI" SG_ 211 PIM_A_Spd_Lim 0;
BA_ "GenSigTimeoutTime_BPCM" SG_ 211 PIM_A_Spd_Lim 0;
BA_ "GenSigTimeoutTime_PBWM" SG_ 211 PIM_A_SPT_Stat 0;
BA_ "GenSigTimeoutTime_MCPB" SG_ 211 PIM_A_SPT_Stat 0;
BA_ "GenSigTimeoutTime_MCPA" SG_ 211 PIM_A_SPT_Stat 0;
BA_ "GenSigTimeoutTime_IDCM" SG_ 211 PIM_A_SPT_Stat 0;
BA_ "GenSigTimeoutTime_ECM" SG_ 211 PIM_A_SPT_Stat 0;
BA_ "GenSigTimeoutTime_DMPI" SG_ 211 PIM_A_SPT_Stat 0;
BA_ "GenSigTimeoutTime_BPCM" SG_ 211 PIM_A_SPT_Stat 0;
BA_ "GenSigTimeoutTime_PBWM" SG_ 211 PIM_A_TorqAchieved_AEMD 0;
BA_ "GenSigTimeoutTime_MCPB" SG_ 211 PIM_A_TorqAchieved_AEMD 0;
BA_ "GenSigTimeoutTime_MCPA" SG_ 211 PIM_A_TorqAchieved_AEMD 0;
BA_ "GenSigTimeoutTime_IDCM" SG_ 211 PIM_A_TorqAchieved_AEMD 0;
BA_ "GenSigTimeoutTime_ECM" SG_ 211 PIM_A_TorqAchieved_AEMD 0;
BA_ "GenSigTimeoutTime_DMPI" SG_ 211 PIM_A_TorqAchieved_AEMD 0;
BA_ "GenSigTimeoutTime_BPCM" SG_ 211 PIM_A_TorqAchieved_AEMD 0;
BA_ "GenSigStartValue" SG_ 211 PIM_A_TorqAchieved_AEMD 4096;
BA_ "GenSigTimeoutTime_PBWM" SG_ 211 PIM_A_TorqAchieved_AEMD_V 0;
BA_ "GenSigTimeoutTime_MCPB" SG_ 211 PIM_A_TorqAchieved_AEMD_V 0;
BA_ "GenSigTimeoutTime_MCPA" SG_ 211 PIM_A_TorqAchieved_AEMD_V 0;
BA_ "GenSigTimeoutTime_IDCM" SG_ 211 PIM_A_TorqAchieved_AEMD_V 0;
BA_ "GenSigTimeoutTime_ECM" SG_ 211 PIM_A_TorqAchieved_AEMD_V 0;
BA_ "GenSigTimeoutTime_DMPI" SG_ 211 PIM_A_TorqAchieved_AEMD_V 0;
BA_ "GenSigTimeoutTime_BPCM" SG_ 211 PIM_A_TorqAchieved_AEMD_V 0;
BA_ "GenSigTimeoutTime_PBWM" SG_ 211 PIM_A_Torque_Achieved_V 0;
BA_ "GenSigTimeoutTime_MCPB" SG_ 211 PIM_A_Torque_Achieved_V 0;
BA_ "GenSigTimeoutTime_MCPA" SG_ 211 PIM_A_Torque_Achieved_V 0;
BA_ "GenSigTimeoutTime_IDCM" SG_ 211 PIM_A_Torque_Achieved_V 0;
BA_ "GenSigTimeoutTime_DMPI" SG_ 211 PIM_A_Torque_Achieved_V 0;
BA_ "GenSigTimeoutTime_BPCM" SG_ 211 PIM_A_Torque_Achieved_V 0;
BA_ "GenSigTimeoutTime_PBWM" SG_ 212 Cntr_PIM_B 0;
BA_ "GenSigTimeoutTime_MCPB" SG_ 212 Cntr_PIM_B 0;
BA_ "GenSigTimeoutTime_MCPA" SG_ 212 Cntr_PIM_B 0;
BA_ "GenSigTimeoutTime_IDCM" SG_ 212 Cntr_PIM_B 0;
BA_ "GenSigTimeoutTime_ECM" SG_ 212 Cntr_PIM_B 0;
BA_ "GenSigTimeoutTime_DMPI" SG_ 212 Cntr_PIM_B 0;
BA_ "GenSigTimeoutTime_BPCM" SG_ 212 Cntr_PIM_B 0;
BA_ "GenSigTimeoutTime_PBWM" SG_ 211 PIM_A_Torque_Achieved 0;
BA_ "GenSigTimeoutTime_MCPB" SG_ 211 PIM_A_Torque_Achieved 0;
BA_ "GenSigTimeoutTime_MCPA" SG_ 211 PIM_A_Torque_Achieved 0;
BA_ "GenSigTimeoutTime_IDCM" SG_ 211 PIM_A_Torque_Achieved 0;
BA_ "GenSigTimeoutTime_DMPI" SG_ 211 PIM_A_Torque_Achieved 0;
BA_ "GenSigTimeoutTime_BPCM" SG_ 211 PIM_A_Torque_Achieved 0;
BA_ "GenSigStartValue" SG_ 211 PIM_A_Torque_Achieved 4096;
BA_ "GenSigTimeoutTime_PBWM" SG_ 1041 Eamount 0;
BA_ "GenSigTimeoutTime_MCPB" SG_ 1041 Eamount 0;
BA_ "GenSigTimeoutTime_MCPA" SG_ 1041 Eamount 0;
BA_ "GenSigTimeoutTime_EVCU2" SG_ 1041 Eamount 0;
BA_ "GenSigTimeoutTime_ECM" SG_ 1041 Eamount 0;
BA_ "GenSigTimeoutTime_DMPI" SG_ 1041 Eamount 0;
BA_ "GenSigTimeoutTime_BPCM" SG_ 1041 Eamount 0;
BA_ "GenSigTimeoutTime_PBWM" SG_ 1041 EVMaxCurrent 0;
BA_ "GenSigTimeoutTime_MCPB" SG_ 1041 EVMaxCurrent 0;
BA_ "GenSigTimeoutTime_MCPA" SG_ 1041 EVMaxCurrent 0;
BA_ "GenSigTimeoutTime_EVCU2" SG_ 1041 EVMaxCurrent 0;
BA_ "GenSigTimeoutTime_ECM" SG_ 1041 EVMaxCurrent 0;
BA_ "GenSigTimeoutTime_DMPI" SG_ 1041 EVMaxCurrent 0;
BA_ "GenSigTimeoutTime_BPCM" SG_ 1041 EVMaxCurrent 0;
BA_ "GenSigTimeoutTime_PBWM" SG_ 1041 EVMaxVoltage 0;
BA_ "GenSigTimeoutTime_MCPB" SG_ 1041 EVMaxVoltage 0;
BA_ "GenSigTimeoutTime_MCPA" SG_ 1041 EVMaxVoltage 0;
BA_ "GenSigTimeoutTime_EVCU2" SG_ 1041 EVMaxVoltage 0;
BA_ "GenSigTimeoutTime_ECM" SG_ 1041 EVMaxVoltage 0;
BA_ "GenSigTimeoutTime_DMPI" SG_ 1041 EVMaxVoltage 0;
BA_ "GenSigTimeoutTime_BPCM" SG_ 1041 EVMaxVoltage 0;
BA_ "GenSigTimeoutTime_PBWM" SG_ 1041 EVMinCurrent 0;
BA_ "GenSigTimeoutTime_MCPB" SG_ 1041 EVMinCurrent 0;
BA_ "GenSigTimeoutTime_MCPA" SG_ 1041 EVMinCurrent 0;
BA_ "GenSigTimeoutTime_EVCU2" SG_ 1041 EVMinCurrent 0;
BA_ "GenSigTimeoutTime_ECM" SG_ 1041 EVMinCurrent 0;
BA_ "GenSigTimeoutTime_DMPI" SG_ 1041 EVMinCurrent 0;
BA_ "GenSigTimeoutTime_BPCM" SG_ 1041 EVMinCurrent 0;
VAL_ 2654486592 CBV_bit4_ActiveWakeupBit 0 "PassiveWakeup" 1 "ActiveWakeup";
VAL_ 292 BPCM_HV_Trac_Main_Contac_Sts 0 "Open" 1 "Closed" 3 "Error_Stuck_Open" 4 "Error_Stuck_Closed" 7 "SNA";
VAL_ 292 BPCM_HV_BalancingMode 0 "No_balancing" 1 "Balancing_in_progress" 2 "Balancing_complete" 3 "Balancing_Error";
VAL_ 292 BPCM_HV_ChargingBusVoltage 2047 "SNA";
VAL_ 292 BPCM_HV_TractionBusVoltage 2047 "SNA";
VAL_ 292 BPCM_Pwr_Limp_Home_On 0 "Disable" 1 "Enable";
VAL_ 292 BPCM_HV_Trac_Bus_Sts 0 "Open" 1 "Closed" 2 "Precharging" 3 "Precharging_Failed" 4 "Precharging_Inhibited" 7 "SNA";
VAL_ 292 BPCM_HV_Char_Bus_Sts 0 "Open" 1 "Closed" 2 "Precharging" 3 "Precharging_Failed" 4 "Precharging_Inhibited" 7 "SNA";
VAL_ 292 BPCM_HV_SOH_Low 127 "SNA";
VAL_ 292 BPCM_HV_SOH 127 "SNA";
VAL_ 292 HVBatContactorWeldCheck 0 "Not_Complete" 1 "Complete";
VAL_ 292 HVBatReady 0 "False" 1 "True";
VAL_ 292 BPCM_DC_CntctrsMidTrmOpeningWarn 0 "False" 1 "True";
VAL_ 292 BPCM_DC_CntctrsShtTrmOpeningWarn 0 "False" 1 "True";
VAL_ 292 BPCM_ImpactHardwireV 0 "Fail_Not_Present" 1 "Fail_Present";
VAL_ 292 BPCM_ImpactHardwire 0 "Not_Actuate" 1 "Actuate";
VAL_ 292 BPCM_HV_Char_Main_Contac_Sts 0 "Open" 1 "Closed" 3 "Error_Stuck_Open" 4 "Error_Stuck_Closed" 7 "SNA";
VAL_ 485 BPCM_HV_NumCellMinTemp 511 "SNA";
VAL_ 485 BPCM_HV_NumCellMaxTemp 511 "SNA";
VAL_ 485 BPCM_HV_NumCellMinVolt 511 "SNA";
VAL_ 485 BPCM_HV_NumCellMaxVolt 511 "SNA";
VAL_ 485 BPCM_Min_Pk_Volt_Allowed 2047 "SNA";
VAL_ 485 BPCM_Max_Pk_Volt_Allowed 2047 "SNA";
VAL_ 288 BPCM_HV_HVBatChargeStat 0 "NOT_READY" 1 "READY" 2 "ERROR_DETECTED" 3 "COMPLETE" 7 "SNA";
VAL_ 292 BPCMInterlockSts 0 "Not_Performed" 1 "OK" 2 "Fail" 3 "Invalid" 4 "Service_Disconnect";
VAL_ 292 BPCM_HV_BatIntrlk_InternalStat 0 "Not_Performed" 1 "OK" 2 "Fail" 3 "Invalid";
VAL_ 485 BPCM_OCV_Min_Cell_Volt 8191 "SNA";
VAL_ 485 BPCM_OCV_Max_Cell_Volt 8191 "SNA";
VAL_ 485 BPCM_OCV_Avg_Cell_Volt 8191 "SNA";
VAL_ 485 BPCM_Min_Cell_Volt_Allowed 8191 "SNA";
VAL_ 485 BPCM_Max_Cell_Volt_Allowed 8191 "SNA";
VAL_ 485 BPCM_Cell_Volt_Min 8191 "SNA";
VAL_ 485 BPCM_Cell_Volt_Max 8191 "SNA";
VAL_ 485 BPCM_Cell_Volt_Avg 8191 "SNA";
VAL_ 292 BPCM_HV_Temperature_Min 2047 "SNA";
VAL_ 292 BPCM_HV_Temperature_Max 2047 "SNA";
VAL_ 292 BPCM_HV_Temperature_Avg 2047 "SNA";
VAL_ 292 BPCM_HV_SOC 1023 "SNA";
VAL_ 292 BPCM_HV_Outlet_Temp 2047 "SNA";
VAL_ 292 BPCM_HV_InternalVoltage 16383 "SNA";
VAL_ 292 BPCM_HV_Inlet_Temp 2047 "SNA";
VAL_ 292 BPCM_HV_Current 65535 "SNA";
VAL_ 292 BPCM_HV_Capacity 4095 "SNA";
VAL_ 292 BPCM_HV_Battery_GFD_Sts 0 "GFD_Not_Performed" 1 "GFD_OK" 2 "GFD_Fail" 3 "GFD_INVALID_meas_noise" 4 "Disabled";
VAL_ 288 BPCM_HV_PwrLmtInstDschg 16383 "SNA";
VAL_ 288 BPCM_HV_PwrLmtInstChrg 16383 "SNA";
VAL_ 288 BPCM_HV_Pwr_MaxDischrg_ShrTrm 16383 "SNA";
VAL_ 288 BPCM_HV_Power_MaxDischarge_MdTrm 16383 "SNA";
VAL_ 288 BPCM_HV_Power_MaxDischarge_LgTrm 16383 "SNA";
VAL_ 288 BPCM_HV_Power_MaxCharge_ShrTrm 16383 "SNA";
VAL_ 288 BPCM_HV_Power_MaxCharge_MdTrm 16383 "SNA";
VAL_ 288 BPCM_HV_Power_MaxCharge_LgTrm 16383 "SNA";
VAL_ 288 BPCM_HV_CrntLmtInstDschg 32767 "SNA";
VAL_ 288 BPCM_HV_CrntLmtInstChrg 32767 "SNA";
VAL_ 288 BPCM_HV_ChargingCurrentProfile 32767 "SNA";
VAL_ 288 BPCM_HV_Cell_MinDischrg_Imped 8191 "SNA";
VAL_ 288 BPCM_HV_Cell_MaxDischrg_Imped 8191 "SNA";
VAL_ 288 BPCM_CntctrsShtTrmOpeningWarn 0 "FALSE" 1 "TRUE";
VAL_ 288 BPCM_CntctrsMidTrmOpeningWarn 0 "FALSE" 1 "TRUE";
VAL_ 2654339161 WakeupSource_FD16_MCPB 0 "No_Wakeup";
VAL_ 2654339161 WakeupSource_FD05_MCPB 0 "No_Wakeup";
VAL_ 2654339161 PreviousCanNMState_FD16_MCPB 0 "Uninitialized State" 1 "Bus-Sleep State" 2 "Prepare-Bus State" 3 "Ready-Sleep State" 4 "Normal Operation State" 5 "Repeat Message State" 6 "Synchronize State" 7 "Offline State";
VAL_ 2654339161 PreviousCanNMState_FD05_MCPB 0 "Uninitialized State" 1 "Bus-Sleep State" 2 "Prepare-Bus State" 3 "Ready-Sleep State" 4 "Normal Operation State" 5 "Repeat Message State" 6 "Synchronize State" 7 "Offline State";
VAL_ 2654339161 GenericFailSts_FD05_MCPB 0 "No_Fail_Present" 1 "Fail_Present";
VAL_ 2654339161 EOL_FD16_MCPB 0 "No_EOL_Programming" 1 "EOL_Programming";
VAL_ 2654339161 EOL_FD05_MCPB 0 "No_EOL_Programming" 1 "EOL_Programming";
VAL_ 2654339161 DES_FD05_MCPB 0 "Error_Active_state" 1 "Error_passive_warning_state" 2 "Bus_off_state" 3 "Not_used";
VAL_ 2654339161 CurrentFailSts_FD05_MCPB 0 "No_Fail_Present" 1 "Fail_Present";
VAL_ 2654339161 CurrentCanNMState_FD16_MCPB 0 "Uninitialized State" 1 "Bus-Sleep State" 2 "Prepare-Bus State" 3 "Ready-Sleep State" 4 "Normal Operation State" 5 "Repeat Message State" 6 "Synchronize State" 7 "Offline State";
VAL_ 2654339161 CurrentCanNMState_FD05_MCPB 0 "Uninitialized State" 1 "Bus-Sleep State" 2 "Prepare-Bus State" 3 "Ready-Sleep State" 4 "Normal Operation State" 5 "Repeat Message State" 6 "Synchronize State" 7 "Offline State";
VAL_ 2654339160 WakeupSource_FD16_MCPA 0 "No_Wakeup";
VAL_ 2654339160 WakeupSource_FD05_MCPA 0 "No_Wakeup";
VAL_ 2654339160 PreviousCanNMState_FD16_MCPA 0 "Uninitialized State" 1 "Bus-Sleep State" 2 "Prepare-Bus State" 3 "Ready-Sleep State" 4 "Normal Operation State" 5 "Repeat Message State" 6 "Synchronize State" 7 "Offline State";
VAL_ 2654339160 PreviousCanNMState_FD05_MCPA 0 "Uninitialized State" 1 "Bus-Sleep State" 2 "Prepare-Bus State" 3 "Ready-Sleep State" 4 "Normal Operation State" 5 "Repeat Message State" 6 "Synchronize State" 7 "Offline State";
VAL_ 2654339160 GenericFailSts_FD05_MCPA 0 "No_Fail_Present" 1 "Fail_Present";
VAL_ 2654339160 EOL_FD16_MCPA 0 "No_EOL_Programming" 1 "EOL_Programming";
VAL_ 2654339160 EOL_FD05_MCPA 0 "No_EOL_Programming" 1 "EOL_Programming";
VAL_ 2654339160 DES_FD05_MCPA 0 "Error_Active_state" 1 "Error_passive_warning_state" 2 "Bus_off_state" 3 "Not_used";
VAL_ 2654339160 CurrentFailSts_FD05_MCPA 0 "No_Fail_Present" 1 "Fail_Present";
VAL_ 2654339160 CurrentCanNMState_FD16_MCPA 0 "Uninitialized State" 1 "Bus-Sleep State" 2 "Prepare-Bus State" 3 "Ready-Sleep State" 4 "Normal Operation State" 5 "Repeat Message State" 6 "Synchronize State" 7 "Offline State";
VAL_ 2654339160 CurrentCanNMState_FD05_MCPA 0 "Uninitialized State" 1 "Bus-Sleep State" 2 "Prepare-Bus State" 3 "Ready-Sleep State" 4 "Normal Operation State" 5 "Repeat Message State" 6 "Synchronize State" 7 "Offline State";
VAL_ 263 OptimdStrtReqdActr 0 "No_Action" 1 "P1f" 2 "P1r" 3 "Starter_12V" 4 "P2" 7 "SNA";
VAL_ 263 OptimdEngStrtStpType 0 "No_Action" 1 "Hybrid_Torque_Start" 2 "Engine_Torque_Start" 3 "Low_Power_Start" 4 "Generic_Torque_Start" 5 "Smooth_AutoStart" 6 "Normal_AutoStart" 7 "Aggressive_Autostart" 8 "Generic_Autostart" 9 "Compression_Test" 10 "Green_Engine_Start" 11 "Controlled_Stop" 12 "Immediate_Stop" 13 "Reverse_Autostart" 14 "Clutch_Autostart" 15 "Imp_Autostart" 16 "EM_Autostart" 17 "EM_LowPower" 31 "SNA";
VAL_ 263 OptimdEngOnOffCmd 0 "Off_Command" 1 "On_Command";
VAL_ 263 Hyb_ProducingTorque 0 "Not_Producing_Torque" 1 "Producing_Torque";
VAL_ 263 HCPFuelDisable 0 "Do_Not_Disable_Fuel" 1 "Disable_Fuel";
VAL_ 263 PowertrainPrplsnActv_PT 0 "Not_Active" 1 "Active";
VAL_ 263 GearEngagedForDisplay_PT 0 "Initialize" 1 "Gear_1st" 2 "Gear_2nd" 3 "Gear_3rd" 4 "Gear_4th" 5 "Gear_5th" 6 "Gear_6th" 7 "Gear_7th" 8 "Gear_8th" 9 "Gear_9th" 12 "Park" 13 "Neutral" 14 "Reverse" 15 "Drive" 16 "Low" 17 "Manual" 18 "Sport_Mode" 31 "SNA";
VAL_ 263 GearEngaged_PT 0 "Neutral" 1 "ForwardGear_1" 2 "ForwardGear_2" 3 "ForwardGear_3" 4 "ForwardGear_4" 5 "ForwardGear_5" 6 "ForwardGear_6" 7 "ForwardGear_7" 8 "ForwardGear_8" 9 "ForwardGear_9" 13 "Parking" 14 "ReverseGear" 15 "SNA";
VAL_ 263 DriveReady_PT 0 "Default" 1 "Veh_Allwd_Shift_Out_Of_P_Or_N";
VAL_ 216 DCChargeInitialized_PT 0 "FALSE" 1 "TRUE";
VAL_ 216 DCChargeEnRq_PT 0 "ChargeNotEnabled" 1 "ChargeEnabled";
VAL_ 216 BPCM_OBCM_AC_ContactorCmd_PT 0 "OPEN" 1 "SYNC" 2 "CLOSE" 7 "SNA";
VAL_ 216 BMS_HV_TracCntctr_Cmd_PT 0 "OPEN" 1 "CLOSED" 2 "IMPACT_OPEN" 3 "FAST_OPEN" 7 "SNA";
VAL_ 216 BMS_HV_RefTracHVBus_V_Vldty_PT 0 "VALID" 1 "INVALID";
VAL_ 216 BMS_HV_RefTracHVBus_V_PT 1023 "SNA";
VAL_ 216 BMS_HV_GFD_Inhibition_PT 0 "GFD_Allowed" 1 "GFD_Inhibited";
VAL_ 216 BMS_HV_DC_Chrgng_Cntct_K_Cmd_PT 0 "OPEN" 2 "CLOSE" 7 "SNA";
VAL_ 216 APM_LV_VsetPoint_PT 2047 "SNA";
VAL_ 216 APM_LV_VActual_PT 511 "SNA";
VAL_ 216 APM_LV_IMax_PT 511 "SNA";
VAL_ 292 BPCM_Wakeup_Request 0 "No_Event" 1 "Wakeup_Event";
VAL_ 292 BPCM_HV_ThermalRunaway 0 "Default" 1 "No_Thermal_Runaway" 2 "Thermal_Runaway_Detected" 3 "SNA";
VAL_ 263 ParkCmd_PT 0 "No_Request" 1 "Disengage" 2 "Engage" 3 "SNA";
VAL_ 2654339161 GenericFailSts_FD16_MCPB 0 "No_Fail_Present" 1 "Fail_Present";
VAL_ 2654339161 DES_FD16_MCPB 0 "Error_Active_state" 1 "Error_passive_warning_state" 2 "Bus_off_state" 3 "Not_used";
VAL_ 2654339161 CurrentFailSts_FD16_MCPB 0 "No_Fail_Present" 1 "Fail_Present";
VAL_ 2654339160 GenericFailSts_FD16_MCPA 0 "No_Fail_Present" 1 "Fail_Present";
VAL_ 2654339160 DES_FD16_MCPA 0 "Error_Active_state" 1 "Error_passive_warning_state" 2 "Bus_off_state" 3 "Not_used";
VAL_ 2654339160 CurrentFailSts_FD16_MCPA 0 "No_Fail_Present" 1 "Fail_Present";
VAL_ 263 ShiftLeverPosition_PT 0 "No_Selection_Active_Or_Available" 1 "Park" 2 "Reverse" 3 "Neutral" 4 "Drive" 5 "Low" 6 "TIP_Autostick" 7 "Plus" 8 "Minus" 9 "Sport" 15 "SNA";
VAL_ 1041 EVMinCurrent 511 "SNA";
VAL_ 1041 EVMaxVoltage 1023 "SNA";
VAL_ 1041 EVMaxCurrent 511 "SNA";
VAL_ 1041 Eamount 262143 "SNA";
VAL_ 1811 Real_Time_Validity 0 "Valid" 1 "Not_Valid";
VAL_ 1811 Real_Time_Clock 4294967295 "SNA";
VAL_ 216 APM_TypeCtrl_PT 0 "IDLE" 1 "Buck_CV" 2 "Buck_CC" 3 "Buck_CP" 4 "Buck_Special" 6 "PreCharge" 7 "DisCharge" 8 "OFF" 15 "SNA";
VAL_ 212 PIM_B_Torque_Achieved_V 0 "Valid" 1 "Invalid";
VAL_ 212 PIM_B_TorqAchieved_AEMD_V 0 "Valid" 1 "Invalid";
VAL_ 212 PIM_B_SPT_Stat 0 "Undetermined " 1 "Passed" 2 "Failed";
VAL_ 212 PIM_B_RPM_V 0 "Valid" 1 "Invalid";
VAL_ 212 PIM_B_MtrMinCpbltyTrq 8191 "SNA";
VAL_ 212 PIM_B_MtrMaxCpbltyTrq 8191 "SNA";
VAL_ 212 PIM_B_MtrIndex 31 "SNA";
VAL_ 212 PIM_B_MinTorq 8191 "SNA";
VAL_ 212 PIM_B_MaxTorq 8191 "SNA";
VAL_ 212 PIM_B_Invrtr_State 0 "NORMAL_POWER_STAGE_OFF " 1 "NORMAL_POWER_STAGE_ON " 2 "NORMAL_POWER_STAGE_OVERRIDE" 3 "ACTIVE_DISCHARGE " 4 "INVERTER_FAULTED " 5 "NORMAL_POWER_STAGE_OFF_HV_RQD" 6 "NORMAL_VC_PRIMING" 7 "NORMAL_VC_ON";
VAL_ 212 PIM_B_InterlockSts 0 "Not_Performed" 1 "OK" 2 "Fail" 3 "Invalid";
VAL_ 212 PIM_B_HV_CnctrOpn_Req 0 "False" 1 "True";
VAL_ 212 PIM_B_Dschrge_Status 0 "AD_INDETERMINATE" 1 "AD_INPROGRESS" 2 "AD_COMPLETE" 3 "AD_FAILED";
VAL_ 212 PIM_B_DeratingFactor 63 "SNA";
VAL_ 212 PIM_B_DerateReason 0 "Reason1" 1 "Reason2" 2 "Reason3" 3 "Reason4" 4 "Reason5" 5 "Reason6" 6 "Reason7" 7 "Reason8" 8 "Reason9" 9 "Reason10" 10 "Reason11" 11 "Reason12" 12 "Reason13" 13 "Reason14" 14 "Reason15" 15 "Reason16";
VAL_ 212 PIM_B_DC_Voltage 1023 "SNA";
VAL_ 212 PIM_B_DC_Volt_V 0 "Valid" 1 "Invalid";
VAL_ 212 PIM_B_DC_Current_V 0 "Valid" 1 "Invalid";
VAL_ 212 PIM_B_CpbltySpdDivVolt 65535 "SNA";
VAL_ 212 PIM_B_CoolantTemp 2047 "SNA";
VAL_ 212 PIM_B_AccelRawV 0 "Valid" 1 "Invalid";
VAL_ 212 PIM_B_6SO_Status 0 "3PS" 1 "6SO" 2 "Switching" 3 "SNA";
VAL_ 212 PIM_B_3PS_Pos 0 "False" 1 "True";
VAL_ 211 PIM_A_Torque_Achieved_V 0 "Valid" 1 "Invalid";
VAL_ 211 PIM_A_TorqAchieved_AEMD_V 0 "Valid" 1 "Invalid";
VAL_ 211 PIM_A_SPT_Stat 0 "Undetermined " 1 "Passed" 2 "Failed";
VAL_ 211 PIM_A_RPM_V 0 "Valid" 1 "Invalid";
VAL_ 211 PIM_A_MtrMinCpbltyTrq 8191 "SNA";
VAL_ 211 PIM_A_MtrMaxCpbltyTrq 8191 "SNA";
VAL_ 211 PIM_A_MtrIndex 31 "SNA";
VAL_ 211 PIM_A_MinTorq 8191 "SNA";
VAL_ 211 PIM_A_MaxTorq 8191 "SNA";
VAL_ 211 PIM_A_Invrtr_State 0 "NORMAL_POWER_STAGE_OFF " 1 "NORMAL_POWER_STAGE_ON " 2 "NORMAL_POWER_STAGE_OVERRIDE" 3 "ACTIVE_DISCHARGE " 4 "INVERTER_FAULTED " 5 "NORMAL_POWER_STAGE_OFF_HV_RQD" 6 "NORMAL_VC_PRIMING" 7 "NORMAL_VC_ON";
VAL_ 211 PIM_A_InterlockSts 0 "Not_Performed" 1 "OK" 2 "Fail" 3 "Invalid";
VAL_ 211 PIM_A_HV_CnctrOpn_Req 0 "False" 1 "True";
VAL_ 211 PIM_A_Dschrge_Status 0 "AD_INDETERMINATE" 1 "AD_INPROGRESS" 2 "AD_COMPLETE" 3 "AD_FAILED";
VAL_ 211 PIM_A_DeratingFactor 63 "SNA";
VAL_ 211 PIM_A_DerateReason 0 "Reason1" 1 "Reason2" 2 "Reason3" 3 "Reason4" 4 "Reason5" 5 "Reason6" 6 "Reason7" 7 "Reason8" 8 "Reason9" 9 "Reason10" 10 "Reason11" 11 "Reason12" 12 "Reason13" 13 "Reason14" 14 "Reason15" 15 "Reason16";
VAL_ 211 PIM_A_DC_Voltage 1023 "SNA";
VAL_ 211 PIM_A_DC_Volt_V 0 "Valid" 1 "Invalid";
VAL_ 211 PIM_A_DC_Current_V 0 "Valid" 1 "Invalid";
VAL_ 211 PIM_A_CpbltySpdDivVolt 65535 "SNA";
VAL_ 211 PIM_A_CoolantTemp 2047 "SNA";
VAL_ 211 PIM_A_AccelRawV 0 "Valid" 1 "Invalid";
VAL_ 211 PIM_A_6SO_Status 0 "3PS" 1 "6SO" 2 "Switching" 3 "1PS";
VAL_ 211 PIM_A_3PS_Pos 0 "False" 1 "True";
VAL_ 215 Pinion_OverspeedWarning 0 "False" 1 "True";
VAL_ 215 PCU_Temporary_Stop_Flag 0 "No_Request" 1 "Temporary_Stop_Request";
VAL_ 215 PCU_MIL_Request 0 "NO_MIL_Request" 1 "MIL_Request";
VAL_ 215 PCU_MaxBoostedVoltage 1023 "SNA";
VAL_ 215 PCU_Max_DischargePowerLmt 16383 "SNA";
VAL_ 215 PCU_Max_ChargePowerLmt 16383 "SNA";
VAL_ 215 PCU_DriveReadyCompletion_Status 0 "Not_ready" 1 "Ready";
VAL_ 215 PCU_Diagnostic_Code 65535 "SNA";
VAL_ 215 BoostConverterFailureSts 0 "Normal" 1 "Faulted" 2 "Power_Limitation" 3 "Voltage_Limitation";
VAL_ 215 BoostConverter_Current 32767 "SNA";
VAL_ 215 BoostConv_UpperIGBT_TempFltd 4095 "SNA";
VAL_ 215 BoostConv_ReactorTemp 4095 "SNA";
VAL_ 215 BoostConv_LowerIGBT_TempFltd 4095 "SNA";
VAL_ 292 BPCM_MILRequest 0 "False" 1 "True";
VAL_ 292 HVBP_Busbar_Temp 255 "SNA";
VAL_ 292 HVBP_BDU_Busbar_Temp 255 "SNA";
VAL_ 292 BPCM_HV_DCFC_Isolation_Sts 0 "Not_Performed" 1 "No_Failure" 3 "Failure" 4 "Error" 7 "SNA";
VAL_ 216 BMS_HV_Char_Main_Contac_Cmd_PT 0 "Open" 1 "Close" 2 "Impact_Open" 3 "Fast_Open" 7 "INV";
VAL_ 215 Output_Torque_Limit 32767 "SNA";
VAL_ 292 BPCM_HV_Trac_PreCha_Contac_Sts 0 "Not_Performed" 1 "No_Failure" 3 "Failure" 4 "Error" 7 "SNA";
VAL_ 215 PCU_Max_DischargePowerLmt_ShrTrm 16383 "SNA";
VAL_ 215 DMPI_OilTemperatureSts 0 "Normal" 1 "High";
VAL_ 263 EVCU_END_Request_Flag_PT 0 "No_Request" 1 "Request";
VAL_ 215 DMPI_TransmissionTemperature 63 "SNA";
VAL_ 212 PIM_B_AccelRaw 65535 "SNA";
VAL_ 211 PIM_A_AccelRaw 65535 "SNA";
SIG_GROUP_ 292 BATTERY_HV_STATUS1_Pkt 1 : MessageCounter_BATT_HV_STATUS1 CRC_BATT_HV_STATUS1 HVBatContactorWeldCheck HVBatReady BPCM_DC_CntctrsMidTrmOpeningWarn BPCM_DC_CntctrsShtTrmOpeningWarn BPCM_ImpactHardwireV BPCM_ImpactHardwire BPCM_HV_Char_Main_Contac_Sts BPCM_HV_Trac_Main_Contac_Sts BPCM_HV_BalancingMode BPCM_HV_ChargingBusVoltage BPCM_HV_TractionBusVoltage BPCM_Pwr_Limp_Home_On BPCM_HV_Trac_Bus_Sts BPCM_HV_Char_Bus_Sts BPCM_HV_SOH_Low BPCM_HV_SOH HVBatContactorOpenTime HVBatLastSlept BPCMInterlockSts BPCM_HV_BatIntrlk_InternalStat BPCM_HV_Temperature_Min BPCM_HV_Temperature_Max BPCM_HV_Temperature_Avg BPCM_HV_SOC BPCM_HV_Outlet_Temp BPCM_HV_InternalVoltage BPCM_HV_Inlet_Temp BPCM_HV_Current BPCM_HV_Capacity BPCM_HV_Battery_GFD_Sts BPCM_Wakeup_Request BPCM_HV_ThermalRunaway BPCM_MILRequest HVBP_Busbar_Temp HVBP_BDU_Busbar_Temp BPCM_HV_DCFC_Isolation_Sts BPCM_HV_Trac_PreCha_Contac_Sts;
SIG_GROUP_ 485 BATTERY_HV_VLIMITS_Pkt 1 : MessageCounter_BATT_HV_VLIMITS CRC_BATT_HV_VLIMITS BPCM_HV_NumCellMinTemp BPCM_HV_NumCellMaxTemp BPCM_HV_NumCellMinVolt BPCM_HV_NumCellMaxVolt BPCM_Min_Pk_Volt_Allowed BPCM_Max_Pk_Volt_Allowed BPCM_OCV_Min_Cell_Volt BPCM_OCV_Max_Cell_Volt BPCM_OCV_Avg_Cell_Volt BPCM_Min_Cell_Volt_Allowed BPCM_Max_Cell_Volt_Allowed BPCM_HV_Insulation_Resistance BPCM_Cell_Volt_Min BPCM_Cell_Volt_Max BPCM_Cell_Volt_Avg;
SIG_GROUP_ 288 BATTERY_HV_POWERLIMITS_Pkt 1 : BPCM_HV_HVBatChargeStat BPCM_HV_PwrLmtInstDschg BPCM_HV_PwrLmtInstChrg BPCM_HV_Pwr_MaxDischrg_ShrTrm BPCM_HV_Power_MaxDischarge_MdTrm BPCM_HV_Power_MaxDischarge_LgTrm BPCM_HV_Power_MaxCharge_ShrTrm BPCM_HV_Power_MaxCharge_MdTrm BPCM_HV_Power_MaxCharge_LgTrm BPCM_HV_CrntLmtInstDschg BPCM_HV_CrntLmtInstChrg BPCM_HV_ChargingCurrentProfile BPCM_HV_Cell_MinDischrg_Imped BPCM_HV_Cell_MaxDischrg_Imped BPCM_CntctrsShtTrmOpeningWarn BPCM_CntctrsMidTrmOpeningWarn MessageCounter_BATT_HV_POWERLIMS CRC_BATT_HV_POWERLIMS;
SIG_GROUP_ 263 PT_SYSTEM_FD_1_Pkt 1 : OptimdStrtReqdActr OptimdEngStrtStpType OptimdEngOnOffCmd Hyb_ProducingTorque HCPFuelDisable PowertrainPrplsnActv_PT GearEngagedForDisplay_PT GearEngaged_PT DriveReady_PT ParkCmd_PT ShiftLeverPosition_PT MessageCounter_PT_SYSTEM_FD_1 CRC_PT_SYSTEM_FD_1 EVCU_END_Request_Flag_PT;
SIG_GROUP_ 216 PT_ENERGY_FD_1_Pkt 1 : MC_PT_ENERGY_FD_1 DCChrgVoltMin_PT DCChrgVoltMax_PT DCChrgPwrLim_PT DCChrgCurrentRq_PT DCChrgCurrentLimit_PT DCChargeInitialized_PT DCChargeEnRq_PT CRC_PT_ENERGY_FD_1 BPCM_OBCM_AC_ContactorCmd_PT BMS_HV_TracCntctr_Cmd_PT BMS_HV_RefTracHVBus_V_Vldty_PT BMS_HV_RefTracHVBus_V_PT BMS_HV_GFD_Inhibition_PT BMS_HV_DC_Chrgng_Cntct_K_Cmd_PT BatteryVoltage_Raw_PT APM_LV_VsetPoint_PT APM_LV_VActual_PT APM_LV_IMax_PT APM_HV_IMax_PT APM_TypeCtrl_PT BMS_HV_Char_Main_Contac_Cmd_PT;
SIG_GROUP_ 212 PIM_B_Pkt 1 : PIM_B_Torque_Achieved PIM_B_Torque_Achieved_V PIM_B_TorqAchieved_AEMD_V PIM_B_TorqAchieved_AEMD PIM_B_SPT_Stat PIM_B_Spd_Lim PIM_B_RPM_V PIM_B_RPM PIM_B_MtrMinCpbltyTrq PIM_B_MtrMaxCpbltyTrq PIM_B_MtrIndex PIM_B_MinTorq PIM_B_MaxTorq PIM_B_Invrtr_State PIM_B_InterlockSts PIM_B_HV_CnctrOpn_Req PIM_B_Dschrge_Status PIM_B_DeratingFactor PIM_B_DerateReason PIM_B_DC_Voltage PIM_B_DC_Volt_V PIM_B_DC_Current_V PIM_B_DC_Current PIM_B_CpbltySpdDivVolt PIM_B_CoolantTemp PIM_B_AccelRawV PIM_B_6SO_Status PIM_B_3PS_Pos MC_PIM_B MAC_PIM_B CRC_PIM_B Cntr_PIM_B PIM_B_AccelRaw;
SIG_GROUP_ 211 PIM_A_Pkt 1 : PIM_A_Torque_Achieved PIM_A_Torque_Achieved_V PIM_A_TorqAchieved_AEMD_V PIM_A_TorqAchieved_AEMD PIM_A_SPT_Stat PIM_A_Spd_Lim PIM_A_RPM_V PIM_A_RPM PIM_A_MtrMinCpbltyTrq PIM_A_MtrMaxCpbltyTrq PIM_A_MtrIndex PIM_A_MinTorq PIM_A_MaxTorq PIM_A_Invrtr_State PIM_A_InterlockSts PIM_A_HV_CnctrOpn_Req PIM_A_Dschrge_Status PIM_A_DeratingFactor PIM_A_DerateReason PIM_A_DC_Voltage PIM_A_DC_Volt_V PIM_A_DC_Current_V PIM_A_DC_Current PIM_A_CpbltySpdDivVolt PIM_A_CoolantTemp PIM_A_AccelRawV PIM_A_6SO_Status PIM_A_3PS_Pos MC_PIM_A MAC_PIM_A CRC_PIM_A Cntr_PIM_A PIM_A_AccelRaw;
SIG_GROUP_ 215 PCU_FD_1_Pkt 1 : Pinion_OverspeedWarning PCU_Temporary_Stop_Flag PCU_MIL_Request PCU_MaxBoostedVoltage PCU_Max_DischargePowerLmt PCU_Max_ChargePowerLmt PCU_DriveReadyCompletion_Status PCU_Diagnostic_Code MessageCounter_PCU_FD_1 MAC_PCU_FD_1 CRC_PCU_FD_1 Cntr_PCU_FD_1 BoostConverterFailureSts BoostConverter_Current BoostConv_UpperIGBT_TempFltd BoostConv_ReactorTemp BoostConv_LowerIGBT_TempFltd Output_Torque_Limit BoostConverterDerateReason PCU_Max_DischargePowerLmt_ShrTrm DMPI_OilTemperatureSts DMPI_TransmissionTemperature;
